VERSION ""

NS_ :

BS_:

BU_: TestTool_HS BCP_HS ECM_HS TCM_HS CGM_HS BCM_HS EBCM_OBD_HS ACCM_HS EBCM_HS TCCM_HS SAS_HS ICCM_OBD_HS ICCM_HS EPS_HS EPB_HS HMIM_HS ONSTAR_HS

BO_ 3221225472 VECTOR__INDEPENDENT_SIG_MSG: 0 Vector__XXX
 SG_ PTOStdbSpdCsCrStVal : 0|3@0+ (1,0) [0|7] "" Vector__XXX
 SG_ HVBatChrgCrdAlrtReq : 0|2@0+ (1,0) [0|3] "" Vector__XXX
 SG_ PTOSet2SpdCsStAvl : 0|1@0+ (1,0) [0|1] "" Vector__XXX
 SG_ PTOSet2SpdCsCrStVal : 0|4@0+ (1,0) [0|15] "" Vector__XXX
 SG_ PTOSet1SpdCsStAvl : 0|1@0+ (1,0) [0|1] "" Vector__XXX
 SG_ PTOSet1SpdCsCrStVal : 0|4@0+ (1,0) [0|15] "" Vector__XXX
 SG_ PTOEngRnTmrCsStAvl : 0|1@0+ (1,0) [0|1] "" Vector__XXX
 SG_ PTOEnRnTmCsCrStVal : 0|4@0+ (1,0) [0|15] "" Vector__XXX
 SG_ ClntCrcFlwRtEst : 0|8@0+ (0.392157,0) [0|100.000035] "%" Vector__XXX
 SG_ MntnceMdStEngRq : 0|1@0+ (1,0) [0|1] "" Vector__XXX
 SG_ PTOAccelUpnBrkRelIO : 0|1@0+ (1,0) [0|1] "" Vector__XXX
 SG_ PTOEngUpnBrkRelIO : 0|1@0+ (1,0) [0|1] "" Vector__XXX
 SG_ PTOManTransInGrIO : 0|1@0+ (1,0) [0|1] "" Vector__XXX
 SG_ PTOServIndOn : 0|1@0+ (1,0) [0|1] "" Vector__XXX
 SG_ PTOTransInGearIO : 0|1@0+ (1,0) [0|1] "" Vector__XXX
 SG_ PTOSetPrkBrkIO : 0|1@0+ (1,0) [0|1] "" Vector__XXX
 SG_ PTORelCltPedIO : 0|1@0+ (1,0) [0|1] "" Vector__XXX
 SG_ PTORelBrkPedIO : 0|1@0+ (1,0) [0|1] "" Vector__XXX
 SG_ PTORelAccPedIO : 0|1@0+ (1,0) [0|1] "" Vector__XXX
 SG_ PTORedEngSpdIO : 0|1@0+ (1,0) [0|1] "" Vector__XXX
 SG_ PTOPrsRelCltPedIO : 0|1@0+ (1,0) [0|1] "" Vector__XXX
 SG_ PTOPrsRelBrkPedIO : 0|1@0+ (1,0) [0|1] "" Vector__XXX
 SG_ PTOEngmntStatInd : 0|2@0+ (1,0) [0|3] "" Vector__XXX
 SG_ PTODisengCrsCntlIO : 0|1@0+ (1,0) [0|1] "" Vector__XXX
 SG_ PTOMobModTrnsInGrIO : 0|1@0+ (1,0) [0|1] "" Vector__XXX
 SG_ ActVbnCtrlMlfIO : 0|1@0+ (1,0) [0|1] "" Vector__XXX
 SG_ SrvSuspSysIO : 0|1@0+ (1,0) [0|1] "" Vector__XXX
 SG_ DCCnvStblznErrIO : 0|1@0+ (1,0) [0|1] "" Vector__XXX

BO_ 558 Air_Cmpresor_Ctrl_Data2_HS: 8 ACCM_HS
 SG_ CDSP_CmpDgrdOp : 25|1@0+ (1,0) [0|1] "" Vector__XXX
 SG_ CDSP_CmpIntShdwnFltSt : 27|2@0+ (1,0) [0|3] "" Vector__XXX
 SG_ CDSP_CmpIntRecblFltSt : 29|2@0+ (1,0) [0|3] "" Vector__XXX
 SG_ CDSP_CmpOpOvrldSt : 31|2@0+ (1,0) [0|3] "" Vector__XXX
 SG_ CDSP_CmpDrCrctFltSt : 17|2@0+ (1,0) [0|3] "" Vector__XXX
 SG_ CDSP_CmpMtrPerfFltSt : 19|2@0+ (1,0) [0|3] "" Vector__XXX
 SG_ CDSP_CmpEEPROMFltSt : 21|2@0+ (1,0) [0|3] "" Vector__XXX
 SG_ CDSP_CmpROMFltSt : 23|2@0+ (1,0) [0|3] "" Vector__XXX
 SG_ CDSP_CmpRAMFltSt : 9|2@0+ (1,0) [0|3] "" Vector__XXX
 SG_ CmpSnsrStPktARC : 7|2@0+ (1,0) [0|3] "N/A" Vector__XXX
 SG_ CSSP_CmpIGBTTpOtRgLSt : 41|2@0+ (1,0) [0|3] "" Vector__XXX
 SG_ CSSP_CmpIGBTTpOtRgHSt : 43|2@0+ (1,0) [0|3] "" Vector__XXX
 SG_ CSSP_CmpCPUTmpOtRgLSt : 45|2@0+ (1,0) [0|3] "" Vector__XXX
 SG_ CSSP_CmpCPUTmpOtRgHSt : 47|2@0+ (1,0) [0|3] "" Vector__XXX
 SG_ CSSP_CmpHVSnsOtRgLSt : 33|2@0+ (1,0) [0|3] "" Vector__XXX
 SG_ CSSP_CmpHVSnsOtRgHSt : 35|2@0+ (1,0) [0|3] "" Vector__XXX
 SG_ CSSP_CmpPhCrntOtRgLSt : 37|2@0+ (1,0) [0|3] "" Vector__XXX
 SG_ CSSP_CmpPhCrntOtRgHSt : 39|2@0+ (1,0) [0|3] "" Vector__XXX
 SG_ CmpDataPktARC : 57|2@0+ (1,0) [0|3] "N/A" Vector__XXX
 SG_ CDP_HVDevShtdnCdARCSt : 49|2@0+ (1,0) [0|3] "" Vector__XXX
 SG_ CDP_CmpSpdReqARCSt : 51|2@0+ (1,0) [0|3] "" Vector__XXX
 SG_ CDP_CmpLossCommOcc : 52|1@0+ (1,0) [0|1] "" Vector__XXX
 SG_ CDP_CmpWkUp : 53|1@0+ (1,0) [0|1] "" Vector__XXX
 SG_ CDP_CmpRunCrnk : 54|1@0+ (1,0) [0|1] "" Vector__XXX
 SG_ CmpSnsrDevStPktARC : 5|2@0+ (1,0) [0|3] "N/A" Vector__XXX
 SG_ CDSP_CmpOvrTmpSt : 11|2@0+ (1,0) [0|3] "" Vector__XXX
 SG_ CDSP_CmpHVAbnrlOrVltSt : 13|2@0+ (1,0) [0|3] "" Vector__XXX
 SG_ CDSP_CmpHVUndrVltgSt : 15|2@0+ (1,0) [0|3] "" Vector__XXX
 SG_ CDSP_CmpHVOvrVltgSt : 1|2@0+ (1,0) [0|3] "" Vector__XXX
 SG_ CDSP_CmpHVOvrCrntSt : 3|2@0+ (1,0) [0|3] "" Vector__XXX
 SG_ CDSP_OvrTempWrnInd : 24|1@0+ (1,0) [0|1] "" Vector__XXX

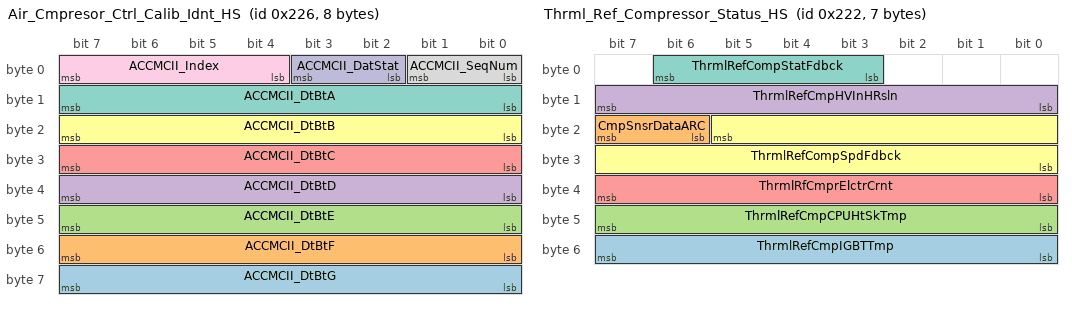
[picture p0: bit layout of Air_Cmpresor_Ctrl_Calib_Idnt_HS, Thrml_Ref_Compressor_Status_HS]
BO_ 550 Air_Cmpresor_Ctrl_Calib_Idnt_HS: 8 ACCM_HS
 SG_ ACCMCII_DtBtG : 63|8@0+ (1,0) [0|0] "" Vector__XXX
 SG_ ACCMCII_DtBtF : 55|8@0+ (1,0) [0|0] "" Vector__XXX
 SG_ ACCMCII_DtBtE : 47|8@0+ (1,0) [0|0] "" Vector__XXX
 SG_ ACCMCII_DtBtD : 39|8@0+ (1,0) [0|0] "" Vector__XXX
 SG_ ACCMCII_DtBtC : 31|8@0+ (1,0) [0|0] "" Vector__XXX
 SG_ ACCMCII_DtBtB : 23|8@0+ (1,0) [0|0] "" Vector__XXX
 SG_ ACCMCII_DtBtA : 15|8@0+ (1,0) [0|0] "" Vector__XXX
 SG_ ACCMCII_SeqNum : 1|2@0+ (1,0) [0|3] "" Vector__XXX
 SG_ ACCMCII_Index : 7|4@0+ (1,0) [0|15] "" Vector__XXX
 SG_ ACCMCII_DatStat : 3|2@0+ (1,0) [0|3] "" Vector__XXX

BO_ 546 Thrml_Ref_Compressor_Status_HS: 7 ACCM_HS
 SG_ ThrmlRefCmpIGBTTmp : 55|8@0+ (1,-40) [-40|215] "deg C" Vector__XXX
 SG_ CmpSnsrDataARC : 23|2@0+ (1,0) [0|3] "N/A" Vector__XXX
 SG_ ThrmlRefCmpCPUHtSkTmp : 47|8@0+ (1,-40) [-40|215] "deg C" Vector__XXX
 SG_ ThrmlRefCmpHVInHRsln : 15|8@0+ (2.5,0) [0|637.5] "V" Vector__XXX
 SG_ ThrmlRfCmprElctrCrnt : 39|8@0+ (0.2,0) [0|51] "A" Vector__XXX
 SG_ ThrmlRefCompSpdFdbck : 21|14@0+ (1,0) [0|16383] "rpm" Vector__XXX
 SG_ ThrmlRefCompStatFdbck : 6|4@0+ (1,0) [0|15] " " Vector__XXX

BO_ 289 ADASIS_RawData_Multiplexed_HS: 8 HMIM_HS
 SG_ Sig0936 : 4|61@0+ (1,0) [0|2.30584300921369E+018] "" Vector__XXX
 SG_ Sig0935 : 7|3@0+ (1,0) [0|7] "" Vector__XXX

BO_ 861 Temp_Diag_CAN_Resp_HS35D: 8 CGM_HS
 SG_ DgnInf : 7|64@0+ (1,0) [0|1.84467440737096E+019] "" Vector__XXX

BO_ 594 USDT_Req_to_HMIM_HS: 8 TestTool_HS
 SG_ DgnInf : 7|64@0+ (1,0) [0|1.84467440737096E+019] ""  CGM_HS,HMIM_HS

BO_ 593 USDT_Req_to_Free_51_HS: 8 TestTool_HS
 SG_ DgnInf : 7|64@0+ (1,0) [0|1.84467440737096E+019] "" Vector__XXX

BO_ 597 USDT_Req_to_Free_55_HS: 8 TestTool_HS
 SG_ DgnInf : 7|64@0+ (1,0) [0|1.84467440737096E+019] "" Vector__XXX

BO_ 592 USDT_Req_to_AVM_HS: 8 TestTool_HS
 SG_ DgnInf : 7|64@0+ (1,0) [0|1.84467440737096E+019] "" Vector__XXX

BO_ 589 USDT_Req_to_ONS_HS: 8 TestTool_HS
 SG_ DgnInf : 7|64@0+ (1,0) [0|1.84467440737096E+019] ""  CGM_HS,ONSTAR_HS

BO_ 582 USDT_Req_to_APPS_HS: 8 TestTool_HS
 SG_ DgnInf : 7|64@0+ (1,0) [0|1.84467440737096E+019] ""  CGM_HS

BO_ 601 USDT_Req_to_MCP_C_HS: 8 TestTool_HS
 SG_ DgnInf : 7|64@0+ (1,0) [0|1.84467440737096E+019] "" Vector__XXX

BO_ 2023 USDT_Req_to_VITM_HS: 8 TestTool_HS
 SG_ DgnInf : 7|64@0+ (1,0) [0|1.84467440737096E+019] "" Vector__XXX

BO_ 2021 USDT_Req_to_OBD_Device5: 8 TestTool_HS
 SG_ DgnInf : 7|64@0+ (1,0) [0|1.84467440737096E+019] ""  EBCM_OBD_HS

BO_ 2019 USDT_Req_to_ICCM_OBD_HS: 8 TestTool_HS
 SG_ DgnInf : 7|64@0+ (1,0) [0|1.84467440737096E+019] ""  ICCM_OBD_HS,ICCM_HS

BO_ 578 USDT_Req_to_EHPS_EPS_HS: 8 TestTool_HS
 SG_ DgnInf : 7|64@0+ (1,0) [0|1.84467440737096E+019] ""  EPS_HS

BO_ 2022 USDT_Req_to_OBD_Device6: 8 TestTool_HS
 SG_ DgnInf : 7|64@0+ (1,0) [0|1.84467440737096E+019] "" Vector__XXX

BO_ 584 USDT_Req_to_Free_48_HS: 8 TestTool_HS
 SG_ DgnInf : 7|64@0+ (1,0) [0|1.84467440737096E+019] "" Vector__XXX

BO_ 586 USDT_Req_to_SAS_HS: 8 TestTool_HS
 SG_ DgnInf : 7|64@0+ (1,0) [0|1.84467440737096E+019] ""  SAS_HS

BO_ 588 USDT_Req_to_PFAF_HS: 8 TestTool_HS
 SG_ DgnInf : 7|64@0+ (1,0) [0|1.84467440737096E+019] ""  CGM_HS

BO_ 580 USDT_Req_to_OBCM_HS: 8 TestTool_HS
 SG_ DgnInf : 7|64@0+ (1,0) [0|1.84467440737096E+019] "" Vector__XXX

BO_ 2020 USDT_Req_to_VICM_HS: 8 TestTool_HS
 SG_ DgnInf : 7|64@0+ (1,0) [0|1.84467440737096E+019] "" Vector__XXX

BO_ 599 USDT_Req_to_MCP_HS: 8 TestTool_HS
 SG_ DgnInf : 7|64@0+ (1,0) [0|1.84467440737096E+019] "" Vector__XXX

BO_ 2017 USDT_Req_to_BCP_HS: 8 TestTool_HS
 SG_ DgnInf : 7|64@0+ (1,0) [0|1.84467440737096E+019] ""  BCP_HS

BO_ 1910 DTC_Triggered_776: 7 BCP_HS
 SG_ DTCI_DTCFaultType_776 : 55|8@0+ (1,0) [0|255] ""  CGM_HS,HMIM_HS,ONSTAR_HS
 SG_ DTCI_CodeSupported_776 : 40|1@0+ (1,0) [0|1] ""  CGM_HS,HMIM_HS,ONSTAR_HS
 SG_ DTCI_CurrentStatus_776 : 41|1@0+ (1,0) [0|1] ""  CGM_HS,HMIM_HS,ONSTAR_HS
 SG_ DTCI_TstNPsdCdClrdSt_776 : 42|1@0+ (1,0) [0|1] ""  CGM_HS,HMIM_HS,ONSTAR_HS
 SG_ DTCI_TstFldCdClrdStat_776 : 43|1@0+ (1,0) [0|1] ""  CGM_HS,HMIM_HS,ONSTAR_HS
 SG_ DTCI_HistStat_776 : 44|1@0+ (1,0) [0|1] ""  CGM_HS,HMIM_HS,ONSTAR_HS
 SG_ DTCI_TstNPsdPwrUpSt_776 : 45|1@0+ (1,0) [0|1] ""  CGM_HS,HMIM_HS,ONSTAR_HS
 SG_ DTCI_TstFldPwrUpSt_776 : 46|1@0+ (1,0) [0|1] ""  CGM_HS,HMIM_HS,ONSTAR_HS
 SG_ DTCI_WrnIndRqdSt_776 : 47|1@0+ (1,0) [0|1] ""  CGM_HS,HMIM_HS,ONSTAR_HS
 SG_ DTCI_DTCFailType_776 : 39|8@0+ (1,0) [0|255] ""  CGM_HS,HMIM_HS,ONSTAR_HS
 SG_ DTCI_DTCNumber_776 : 23|16@0+ (1,0) [0|65535] ""  CGM_HS,HMIM_HS,ONSTAR_HS
 SG_ DTCI_DTCSource_776 : 15|8@0+ (1,0) [0|255] ""  CGM_HS,HMIM_HS,ONSTAR_HS
 SG_ DTCI_DTCTriggered_776 : 0|1@0+ (1,0) [0|1] ""  CGM_HS,HMIM_HS,ONSTAR_HS
 SG_ DTCIUnused7_776 : 1|1@0+ (1,0) [0|1] ""  CGM_HS,HMIM_HS,ONSTAR_HS
 SG_ DTCIUnused6_776 : 2|1@0+ (1,0) [0|1] ""  CGM_HS,HMIM_HS,ONSTAR_HS
 SG_ DTCIUnused5_776 : 3|1@0+ (1,0) [0|1] ""  CGM_HS,HMIM_HS,ONSTAR_HS
 SG_ DTCIUnused4_776 : 4|1@0+ (1,0) [0|1] ""  CGM_HS,HMIM_HS,ONSTAR_HS
 SG_ DTCIUnused3_776 : 5|1@0+ (1,0) [0|1] ""  CGM_HS,HMIM_HS,ONSTAR_HS
 SG_ DTCIUnused2_776 : 6|1@0+ (1,0) [0|1] ""  CGM_HS,HMIM_HS,ONSTAR_HS
 SG_ DTCIUnused1_776 : 7|1@0+ (1,0) [0|1] ""  CGM_HS,HMIM_HS,ONSTAR_HS

BO_ 2025 USDT_Resp_From_BCP_HS: 8 BCP_HS
 SG_ DgnInf : 7|64@0+ (1,0) [0|1.84467440737096E+019] ""  CGM_HS,TestTool_HS,ONSTAR_HS

BO_ 1513 UUDT_Resp_From_BCP_HS: 8 BCP_HS
 SG_ DgnInf : 7|64@0+ (1,0) [0|1.84467440737096E+019] ""  CGM_HS,TestTool_HS,ONSTAR_HS

BO_ 581 USDT_Req_to_ALC_HS: 8 TestTool_HS
 SG_ DgnInf : 7|64@0+ (1,0) [0|1.84467440737096E+019] "" Vector__XXX

BO_ 585 USDT_Req_to_AFL_AHL_HS: 8 TestTool_HS
 SG_ DgnInf : 7|64@0+ (1,0) [0|1.84467440737096E+019] ""  CGM_HS

BO_ 1916 DTC_Triggered_77C: 7 CGM_HS
 SG_ DTCI_DTCFaultType_77C : 55|8@0+ (1,0) [0|255] ""  CGM_HS,HMIM_HS,ONSTAR_HS
 SG_ DTCI_CodeSupported_77C : 40|1@0+ (1,0) [0|1] ""  CGM_HS,HMIM_HS,ONSTAR_HS
 SG_ DTCI_CurrentStatus_77C : 41|1@0+ (1,0) [0|1] ""  CGM_HS,HMIM_HS,ONSTAR_HS
 SG_ DTCI_TstNPsdCdClrdSt_77C : 42|1@0+ (1,0) [0|1] ""  CGM_HS,HMIM_HS,ONSTAR_HS
 SG_ DTCI_TstFldCdClrdStat_77C : 43|1@0+ (1,0) [0|1] ""  CGM_HS,HMIM_HS,ONSTAR_HS
 SG_ DTCI_HistStat_77C : 44|1@0+ (1,0) [0|1] ""  CGM_HS,HMIM_HS,ONSTAR_HS
 SG_ DTCI_TstNPsdPwrUpSt_77C : 45|1@0+ (1,0) [0|1] ""  CGM_HS,HMIM_HS,ONSTAR_HS
 SG_ DTCI_TstFldPwrUpSt_77C : 46|1@0+ (1,0) [0|1] ""  CGM_HS,HMIM_HS,ONSTAR_HS
 SG_ DTCI_WrnIndRqdSt_77C : 47|1@0+ (1,0) [0|1] ""  CGM_HS,HMIM_HS,ONSTAR_HS
 SG_ DTCI_DTCFailType_77C : 39|8@0+ (1,0) [0|255] ""  CGM_HS,HMIM_HS,ONSTAR_HS
 SG_ DTCI_DTCNumber_77C : 23|16@0+ (1,0) [0|65535] ""  CGM_HS,HMIM_HS,ONSTAR_HS
 SG_ DTCI_DTCSource_77C : 15|8@0+ (1,0) [0|255] ""  CGM_HS,HMIM_HS,ONSTAR_HS
 SG_ DTCI_DTCTriggered_77C : 0|1@0+ (1,0) [0|1] ""  CGM_HS,HMIM_HS,ONSTAR_HS
 SG_ DTCIUnused7_77C : 1|1@0+ (1,0) [0|1] ""  CGM_HS,HMIM_HS,ONSTAR_HS
 SG_ DTCIUnused6_77C : 2|1@0+ (1,0) [0|1] ""  CGM_HS,HMIM_HS,ONSTAR_HS
 SG_ DTCIUnused5_77C : 3|1@0+ (1,0) [0|1] ""  CGM_HS,HMIM_HS,ONSTAR_HS
 SG_ DTCIUnused4_77C : 4|1@0+ (1,0) [0|1] ""  CGM_HS,HMIM_HS,ONSTAR_HS
 SG_ DTCIUnused3_77C : 5|1@0+ (1,0) [0|1] ""  CGM_HS,HMIM_HS,ONSTAR_HS
 SG_ DTCIUnused2_77C : 6|1@0+ (1,0) [0|1] ""  CGM_HS,HMIM_HS,ONSTAR_HS
 SG_ DTCIUnused1_77C : 7|1@0+ (1,0) [0|1] ""  CGM_HS,HMIM_HS,ONSTAR_HS

BO_ 1353 UUDT_Resp_From_AHL_AFL_HS: 8 CGM_HS
 SG_ DgnInf_HS549 : 7|64@0+ (1,0) [0|1.84467440737096E+019] ""  CGM_HS,TestTool_HS,ONSTAR_HS

BO_ 1609 USDT_Resp_From_AHL_AFL_HS: 8 CGM_HS
 SG_ DgnInf : 7|64@0+ (1,0) [0|1.84467440737096E+019] ""  CGM_HS,TestTool_HS,ONSTAR_HS

BO_ 590 USDT_Req_to_SADS_HS: 8 TestTool_HS
 SG_ DgnInf : 7|64@0+ (1,0) [0|1.84467440737096E+019] "" Vector__XXX

BO_ 596 USDT_Req_to_EPB_HS: 8 TestTool_HS
 SG_ DgnInf : 7|64@0+ (1,0) [0|1.84467440737096E+019] ""  CGM_HS,EPB_HS

BO_ 1364 UUDT_Resp_From_EPB_HS: 8 EPB_HS
 SG_ DgnInf_HS554 : 7|64@0+ (1,0) [0|1.84467440737096E+019] ""  CGM_HS,ONSTAR_HS,TestTool_HS

BO_ 1917 DTC_Triggered_77D: 7 EPB_HS
 SG_ DTCI_DTCFaultType_77D : 55|8@0+ (1,0) [0|255] ""  CGM_HS,HMIM_HS,ONSTAR_HS
 SG_ DTCI_CodeSupported_77D : 40|1@0+ (1,0) [0|1] ""  CGM_HS,HMIM_HS,ONSTAR_HS
 SG_ DTCI_CurrentStatus_77D : 41|1@0+ (1,0) [0|1] ""  CGM_HS,HMIM_HS,ONSTAR_HS
 SG_ DTCI_TstNPsdCdClrdSt_77D : 42|1@0+ (1,0) [0|1] ""  CGM_HS,HMIM_HS,ONSTAR_HS
 SG_ DTCI_TstFldCdClrdStat_77D : 43|1@0+ (1,0) [0|1] ""  CGM_HS,HMIM_HS,ONSTAR_HS
 SG_ DTCI_HistStat_77D : 44|1@0+ (1,0) [0|1] ""  CGM_HS,HMIM_HS,ONSTAR_HS
 SG_ DTCI_TstNPsdPwrUpSt_77D : 45|1@0+ (1,0) [0|1] ""  CGM_HS,HMIM_HS,ONSTAR_HS
 SG_ DTCI_TstFldPwrUpSt_77D : 46|1@0+ (1,0) [0|1] ""  CGM_HS,HMIM_HS,ONSTAR_HS
 SG_ DTCI_WrnIndRqdSt_77D : 47|1@0+ (1,0) [0|1] ""  CGM_HS,HMIM_HS,ONSTAR_HS
 SG_ DTCI_DTCFailType_77D : 39|8@0+ (1,0) [0|255] ""  CGM_HS,HMIM_HS,ONSTAR_HS
 SG_ DTCI_DTCNumber_77D : 23|16@0+ (1,0) [0|65535] ""  CGM_HS,HMIM_HS,ONSTAR_HS
 SG_ DTCI_DTCSource_77D : 15|8@0+ (1,0) [0|255] ""  CGM_HS,HMIM_HS,ONSTAR_HS
 SG_ DTCI_DTCTriggered_77D : 0|1@0+ (1,0) [0|1] ""  CGM_HS,HMIM_HS,ONSTAR_HS
 SG_ DTCIUnused7_77D : 1|1@0+ (1,0) [0|1] ""  CGM_HS,HMIM_HS,ONSTAR_HS
 SG_ DTCIUnused6_77D : 2|1@0+ (1,0) [0|1] ""  CGM_HS,HMIM_HS,ONSTAR_HS
 SG_ DTCIUnused5_77D : 3|1@0+ (1,0) [0|1] ""  CGM_HS,HMIM_HS,ONSTAR_HS
 SG_ DTCIUnused4_77D : 4|1@0+ (1,0) [0|1] ""  CGM_HS,HMIM_HS,ONSTAR_HS
 SG_ DTCIUnused3_77D : 5|1@0+ (1,0) [0|1] ""  CGM_HS,HMIM_HS,ONSTAR_HS
 SG_ DTCIUnused2_77D : 6|1@0+ (1,0) [0|1] ""  CGM_HS,HMIM_HS,ONSTAR_HS
 SG_ DTCIUnused1_77D : 7|1@0+ (1,0) [0|1] ""  CGM_HS,HMIM_HS,ONSTAR_HS

BO_ 1620 USDT_Resp_From_EPB_HS: 8 EPB_HS
 SG_ DgnInf : 7|64@0+ (1,0) [0|1.84467440737096E+019] ""  CGM_HS,ONSTAR_HS,TestTool_HS

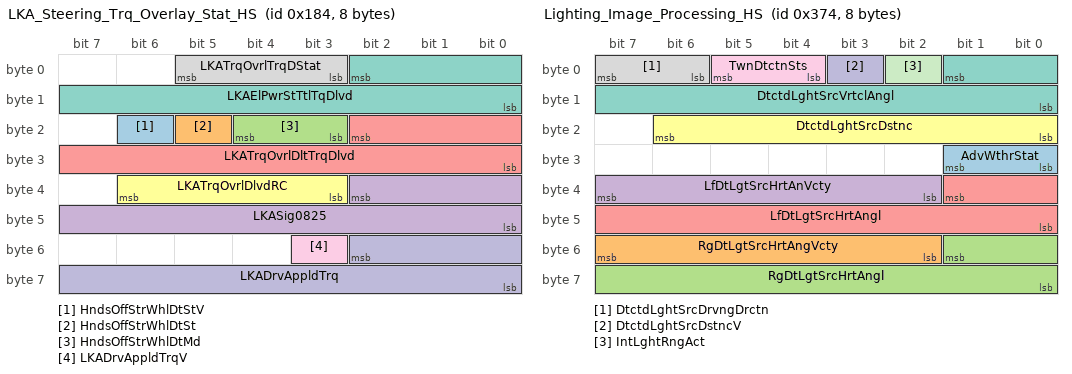
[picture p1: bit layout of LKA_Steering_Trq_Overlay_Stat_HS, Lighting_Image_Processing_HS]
BO_ 388 LKA_Steering_Trq_Overlay_Stat_HS: 8 EPS_HS
 SG_ HndsOffStrWhlDtStV : 22|1@0+ (1,0) [0|1] ""  CGM_HS
 SG_ HndsOffStrWhlDtSt : 21|1@0+ (1,0) [0|1] ""  CGM_HS
 SG_ HndsOffStrWhlDtMd : 20|2@0+ (1,0) [0|3] ""  CGM_HS
 SG_ LKASig0825 : 34|11@0+ (1,0) [0|2047] ""  CGM_HS
 SG_ LKATrqOvrlDltTrqDlvd : 18|11@0- (0.01,0) [-10.24|10.23] "Nm"  CGM_HS
 SG_ LKATrqOvrlDlvdRC : 38|4@0+ (1,0) [0|15] ""  CGM_HS
 SG_ LKAElPwrStTtlTqDlvd : 2|11@0- (0.01,0) [-10.24|10.23] "Nm"  CGM_HS
 SG_ LKATrqOvrlTrqDStat : 5|3@0+ (1,0) [0|7] ""  CGM_HS
 SG_ LKADrvAppldTrqV : 51|1@0+ (1,0) [0|1] ""  CGM_HS
 SG_ LKADrvAppldTrq : 50|11@0- (0.01,0) [-10.24|10.23] "Nm"  CGM_HS

BO_ 587 USDT_Req_to_ECU033_FCM_HS: 8 TestTool_HS
 SG_ DgnInf : 7|64@0+ (1,0) [0|1.84467440737096E+019] ""  CGM_HS

BO_ 884 Lighting_Image_Processing_HS: 8 CGM_HS
 SG_ AdvWthrStat : 25|2@0+ (1,0) [0|3] ""  CGM_HS
 SG_ RgDtLgtSrcHrtAngVcty : 55|6@0- (1,0) [-32|31] "deg/sec"  CGM_HS
 SG_ RgDtLgtSrcHrtAngl : 49|10@0- (0.04,0) [-20.48|20.44] "deg"  CGM_HS
 SG_ LfDtLgtSrcHrtAnVcty : 39|6@0- (1,0) [-32|31] "deg/sec"  CGM_HS
 SG_ LfDtLgtSrcHrtAngl : 33|10@0- (0.04,0) [-20.48|20.44] "deg"  CGM_HS
 SG_ DtctdLghtSrcDstnc : 22|7@0+ (10,0) [0|1270] "m"  CGM_HS
 SG_ DtctdLghtSrcVrtclAngl : 1|10@0- (0.04,0) [-20.48|20.44] "deg"  CGM_HS
 SG_ DtctdLghtSrcDrvngDrctn : 7|2@0+ (1,0) [0|3] ""  CGM_HS
 SG_ TwnDtctnSts : 5|2@0+ (1,0) [0|3] ""  CGM_HS
 SG_ DtctdLghtSrcDstncV : 3|1@0+ (1,0) [0|1] ""  CGM_HS
 SG_ IntLghtRngAct : 2|1@0+ (1,0) [0|1] ""  CGM_HS

BO_ 1930 DTC_Triggered_78A: 7 CGM_HS
 SG_ DTCI_CodeSupported_78A : 40|1@0+ (1,0) [0|1] ""  CGM_HS,HMIM_HS,ONSTAR_HS
 SG_ DTCI_CurrentStatus_78A : 41|1@0+ (1,0) [0|1] ""  CGM_HS,HMIM_HS,ONSTAR_HS
 SG_ DTCI_DTCFailType_78A : 39|8@0+ (1,0) [0|255] ""  CGM_HS,HMIM_HS,ONSTAR_HS
 SG_ DTCI_DTCFaultType_78A : 55|8@0+ (1,0) [0|255] ""  CGM_HS,HMIM_HS,ONSTAR_HS
 SG_ DTCI_DTCNumber_78A : 23|16@0+ (1,0) [0|65535] ""  CGM_HS,HMIM_HS,ONSTAR_HS
 SG_ DTCI_DTCSource_78A : 15|8@0+ (1,0) [0|255] ""  CGM_HS,HMIM_HS,ONSTAR_HS
 SG_ DTCI_DTCTriggered_78A : 0|1@0+ (1,0) [0|1] ""  CGM_HS,HMIM_HS,ONSTAR_HS
 SG_ DTCI_HistStat_78A : 44|1@0+ (1,0) [0|1] ""  CGM_HS,HMIM_HS,ONSTAR_HS
 SG_ DTCI_TstFldCdClrdStat_78A : 43|1@0+ (1,0) [0|1] ""  CGM_HS,HMIM_HS,ONSTAR_HS
 SG_ DTCI_TstFldPwrUpSt_78A : 46|1@0+ (1,0) [0|1] ""  CGM_HS,HMIM_HS,ONSTAR_HS
 SG_ DTCI_TstNPsdCdClrdSt_78A : 42|1@0+ (1,0) [0|1] ""  CGM_HS,HMIM_HS,ONSTAR_HS
 SG_ DTCI_TstNPsdPwrUpSt_78A : 45|1@0+ (1,0) [0|1] ""  CGM_HS,HMIM_HS,ONSTAR_HS
 SG_ DTCIUnused1_78A : 7|1@0+ (1,0) [0|1] ""  CGM_HS,HMIM_HS,ONSTAR_HS
 SG_ DTCIUnused2_78A : 6|1@0+ (1,0) [0|1] ""  CGM_HS,HMIM_HS,ONSTAR_HS
 SG_ DTCIUnused3_78A : 5|1@0+ (1,0) [0|1] ""  CGM_HS,HMIM_HS,ONSTAR_HS
 SG_ DTCIUnused4_78A : 4|1@0+ (1,0) [0|1] ""  CGM_HS,HMIM_HS,ONSTAR_HS
 SG_ DTCIUnused5_78A : 3|1@0+ (1,0) [0|1] ""  CGM_HS,HMIM_HS,ONSTAR_HS
 SG_ DTCIUnused6_78A : 2|1@0+ (1,0) [0|1] ""  CGM_HS,HMIM_HS,ONSTAR_HS
 SG_ DTCIUnused7_78A : 1|1@0+ (1,0) [0|1] ""  CGM_HS,HMIM_HS,ONSTAR_HS
 SG_ DTCI_WrnIndRqdSt_78A : 47|1@0+ (1,0) [0|1] ""  CGM_HS,HMIM_HS,ONSTAR_HS

BO_ 1611 USDT_Resp_From_ECU033_FCM_HS: 8 CGM_HS
 SG_ DgnInf : 7|64@0+ (1,0) [0|1.84467440737096E+019] ""  CGM_HS,TestTool_HS,ONSTAR_HS

BO_ 1355 UUDT_Resp_From_ECU033_FCM_HS: 8 CGM_HS
 SG_ DgnInf_HS54B : 7|64@0+ (1,0) [0|1.84467440737096E+019] ""  CGM_HS,TestTool_HS,ONSTAR_HS

BO_ 598 USDT_Req_to_TCCM_HS: 8 TestTool_HS
 SG_ DgnInf : 7|64@0+ (1,0) [0|1.84467440737096E+019] ""  TCCM_HS

BO_ 1366 UUDT_Resp_From_TCCM_HS: 8 TCCM_HS
 SG_ DgnInf_HS556 : 7|64@0+ (1,0) [0|1.84467440737096E+019] ""  CGM_HS,ONSTAR_HS,TestTool_HS

BO_ 1622 USDT_Resp_From_TCCM_HS: 8 TCCM_HS
 SG_ DgnInf : 7|64@0+ (1,0) [0|1.84467440737096E+019] ""  CGM_HS,ONSTAR_HS,TestTool_HS

BO_ 591 USDT_Req_to_RDCM_HS: 8 TestTool_HS
 SG_ DgnInf : 7|64@0+ (1,0) [0|1.84467440737096E+019] "" Vector__XXX

BO_ 1914 DTC_Triggered_77A: 7 TCCM_HS
 SG_ DTCI_DTCFaultType_77A : 55|8@0+ (1,0) [0|255] ""  CGM_HS,HMIM_HS,ONSTAR_HS
 SG_ DTCI_CodeSupported_77A : 40|1@0+ (1,0) [0|1] ""  CGM_HS,HMIM_HS,ONSTAR_HS
 SG_ DTCI_CurrentStatus_77A : 41|1@0+ (1,0) [0|1] ""  CGM_HS,HMIM_HS,ONSTAR_HS
 SG_ DTCI_TstNPsdCdClrdSt_77A : 42|1@0+ (1,0) [0|1] ""  CGM_HS,HMIM_HS,ONSTAR_HS
 SG_ DTCI_TstFldCdClrdStat_77A : 43|1@0+ (1,0) [0|1] ""  CGM_HS,HMIM_HS,ONSTAR_HS
 SG_ DTCI_HistStat_77A : 44|1@0+ (1,0) [0|1] ""  CGM_HS,HMIM_HS,ONSTAR_HS
 SG_ DTCI_TstNPsdPwrUpSt_77A : 45|1@0+ (1,0) [0|1] ""  CGM_HS,HMIM_HS,ONSTAR_HS
 SG_ DTCI_TstFldPwrUpSt_77A : 46|1@0+ (1,0) [0|1] ""  CGM_HS,HMIM_HS,ONSTAR_HS
 SG_ DTCI_WrnIndRqdSt_77A : 47|1@0+ (1,0) [0|1] ""  CGM_HS,HMIM_HS,ONSTAR_HS
 SG_ DTCI_DTCFailType_77A : 39|8@0+ (1,0) [0|255] ""  CGM_HS,HMIM_HS,ONSTAR_HS
 SG_ DTCI_DTCNumber_77A : 23|16@0+ (1,0) [0|65535] ""  CGM_HS,HMIM_HS,ONSTAR_HS
 SG_ DTCI_DTCSource_77A : 15|8@0+ (1,0) [0|255] ""  CGM_HS,HMIM_HS,ONSTAR_HS
 SG_ DTCI_DTCTriggered_77A : 0|1@0+ (1,0) [0|1] ""  CGM_HS,HMIM_HS,ONSTAR_HS
 SG_ DTCIUnused7_77A : 1|1@0+ (1,0) [0|1] ""  CGM_HS,HMIM_HS,ONSTAR_HS
 SG_ DTCIUnused6_77A : 2|1@0+ (1,0) [0|1] ""  CGM_HS,HMIM_HS,ONSTAR_HS
 SG_ DTCIUnused5_77A : 3|1@0+ (1,0) [0|1] ""  CGM_HS,HMIM_HS,ONSTAR_HS
 SG_ DTCIUnused4_77A : 4|1@0+ (1,0) [0|1] ""  CGM_HS,HMIM_HS,ONSTAR_HS
 SG_ DTCIUnused3_77A : 5|1@0+ (1,0) [0|1] ""  CGM_HS,HMIM_HS,ONSTAR_HS
 SG_ DTCIUnused2_77A : 6|1@0+ (1,0) [0|1] ""  CGM_HS,HMIM_HS,ONSTAR_HS
 SG_ DTCIUnused1_77A : 7|1@0+ (1,0) [0|1] ""  CGM_HS,HMIM_HS,ONSTAR_HS

BO_ 2032 CCP_Command_Receive_Object_HS: 8 TestTool_HS
 SG_ DgnInf : 7|64@0+ (1,0) [0|1.84467440737096E+019] ""  CGM_HS

BO_ 583 USDT_Req_to_PTO_HS: 8 TestTool_HS
 SG_ DgnInf : 7|64@0+ (1,0) [0|1.84467440737096E+019] "" Vector__XXX

BO_ 2034 CCP_Data_Transmission_Object_HS: 8 CGM_HS
 SG_ DgnInf : 7|64@0+ (1,0) [0|1.84467440737096E+019] ""  TestTool_HS

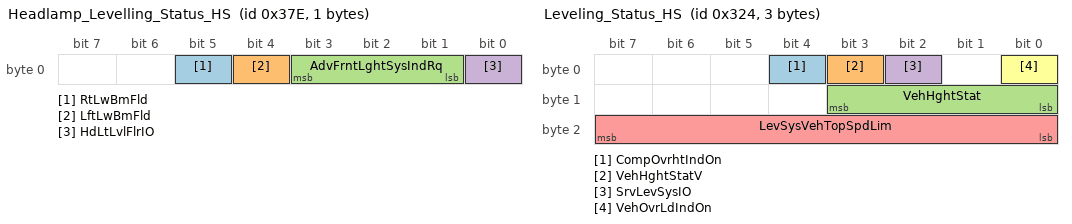
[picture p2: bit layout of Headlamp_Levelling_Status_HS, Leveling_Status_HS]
BO_ 894 Headlamp_Levelling_Status_HS: 1 CGM_HS
 SG_ RtLwBmFld : 5|1@0+ (1,0) [0|1] ""  BCM_HS
 SG_ LftLwBmFld : 4|1@0+ (1,0) [0|1] ""  BCM_HS
 SG_ AdvFrntLghtSysIndRq : 3|3@0+ (1,0) [0|7] ""  BCM_HS
 SG_ HdLtLvlFlrIO : 0|1@0+ (1,0) [0|1] ""  BCM_HS

BO_ 577 USDT_Req_to_BCM_HS: 8 TestTool_HS
 SG_ DgnInf : 7|64@0+ (1,0) [0|1.84467440737096E+019] ""  BCM_HS

BO_ 804 Leveling_Status_HS: 3 ICCM_HS
 SG_ CompOvrhtIndOn : 4|1@0+ (1,0) [0|1] ""  CGM_HS,BCM_HS
 SG_ VehHghtStatV : 3|1@0+ (1,0) [0|1] ""  CGM_HS,EBCM_OBD_HS,EBCM_HS,BCM_HS
 SG_ VehHghtStat : 11|4@0+ (1,0) [0|15] ""  CGM_HS,EBCM_OBD_HS,EBCM_HS,BCM_HS
 SG_ SrvLevSysIO : 2|1@0+ (1,0) [0|1] ""  CGM_HS,ONSTAR_HS,BCM_HS
 SG_ LevSysVehTopSpdLim : 23|8@0+ (2,0) [0|510] "km/h"  CGM_HS,BCM_HS
 SG_ VehOvrLdIndOn : 0|1@0+ (1,0) [0|1] ""  CGM_HS,ONSTAR_HS,BCM_HS

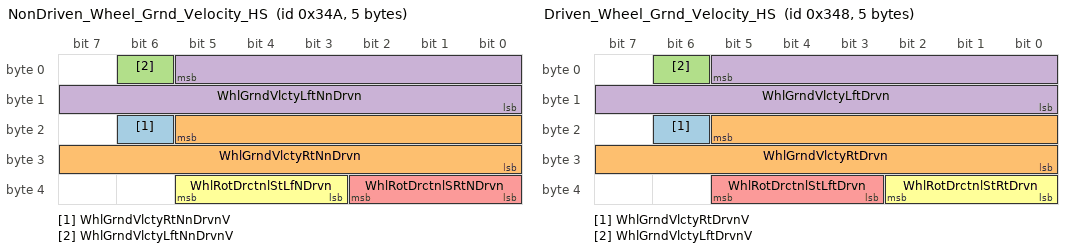
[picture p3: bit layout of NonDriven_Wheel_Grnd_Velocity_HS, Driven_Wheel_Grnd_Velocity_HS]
BO_ 842 NonDriven_Wheel_Grnd_Velocity_HS: 5 EBCM_HS
 SG_ WhlGrndVlctyRtNnDrvnV : 22|1@0+ (1,0) [0|1] ""  CGM_HS,HMIM_HS,EPS_HS,EPB_HS,TCCM_HS,BCM_HS
 SG_ WhlGrndVlctyRtNnDrvn : 21|14@0+ (0.03125,0) [0|511.96875] "km / h"  CGM_HS,HMIM_HS,EPS_HS,EPB_HS,TCCM_HS,BCM_HS
 SG_ WhlGrndVlctyLftNnDrvnV : 6|1@0+ (1,0) [0|1] ""  CGM_HS,HMIM_HS,EPS_HS,EPB_HS,TCCM_HS,BCM_HS
 SG_ WhlGrndVlctyLftNnDrvn : 5|14@0+ (0.03125,0) [0|511.96875] "km / h"  CGM_HS,HMIM_HS,EPS_HS,EPB_HS,TCCM_HS,BCM_HS
 SG_ WhlRotDrctnlSRtNDrvn : 34|3@0+ (1,0) [0|7] ""  CGM_HS,HMIM_HS,EPS_HS
 SG_ WhlRotDrctnlStLfNDrvn : 37|3@0+ (1,0) [0|7] ""  CGM_HS,HMIM_HS,EPS_HS

BO_ 840 Driven_Wheel_Grnd_Velocity_HS: 5 EBCM_HS
 SG_ WhlGrndVlctyRtDrvnV : 22|1@0+ (1,0) [0|1] ""  CGM_HS,HMIM_HS,EPS_HS,TCCM_HS,EPB_HS,BCM_HS
 SG_ WhlGrndVlctyRtDrvn : 21|14@0+ (0.03125,0) [0|511.96875] "km / h"  CGM_HS,HMIM_HS,EPS_HS,TCCM_HS,EPB_HS,BCM_HS
 SG_ WhlGrndVlctyLftDrvnV : 6|1@0+ (1,0) [0|1] ""  CGM_HS,HMIM_HS,EPS_HS,TCCM_HS,EPB_HS,BCM_HS
 SG_ WhlGrndVlctyLftDrvn : 5|14@0+ (0.03125,0) [0|511.96875] "km / h"  CGM_HS,HMIM_HS,EPS_HS,TCCM_HS,EPB_HS,BCM_HS
 SG_ WhlRotDrctnlStLftDrvn : 37|3@0+ (1,0) [0|7] ""  CGM_HS,HMIM_HS,EPS_HS
 SG_ WhlRotDrctnlStRtDrvn : 34|3@0+ (1,0) [0|7] ""  CGM_HS,HMIM_HS,EPS_HS

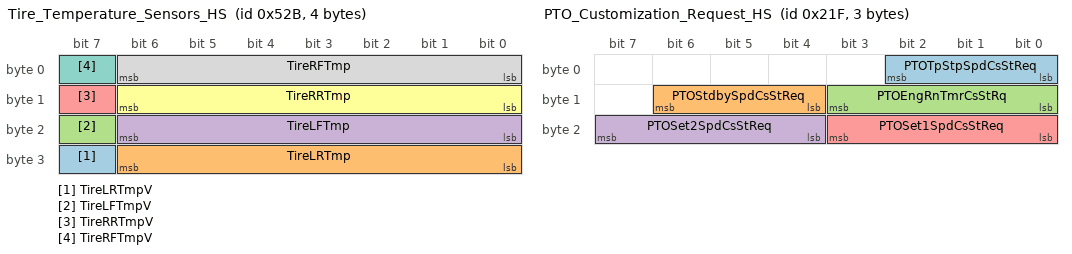
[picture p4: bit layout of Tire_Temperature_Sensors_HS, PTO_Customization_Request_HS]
BO_ 1323 Tire_Temperature_Sensors_HS: 4 BCM_HS
 SG_ TireLRTmpV : 31|1@0+ (1,0) [0|1] ""  CGM_HS,ICCM_OBD_HS,EBCM_OBD_HS,ICCM_HS,EBCM_HS
 SG_ TireLRTmp : 30|7@0+ (1,-20) [-20|107] "deg C"  CGM_HS,ICCM_OBD_HS,EBCM_OBD_HS,ICCM_HS,EBCM_HS
 SG_ TireLFTmpV : 23|1@0+ (1,0) [0|1] ""  CGM_HS,ICCM_OBD_HS,EBCM_OBD_HS,ICCM_HS,EBCM_HS
 SG_ TireLFTmp : 22|7@0+ (1,-20) [-20|107] "deg C"  CGM_HS,ICCM_OBD_HS,EBCM_OBD_HS,ICCM_HS,EBCM_HS
 SG_ TireRRTmpV : 15|1@0+ (1,0) [0|1] ""  CGM_HS,ICCM_OBD_HS,EBCM_OBD_HS,ICCM_HS,EBCM_HS
 SG_ TireRRTmp : 14|7@0+ (1,-20) [-20|107] "deg C"  CGM_HS,ICCM_OBD_HS,EBCM_OBD_HS,ICCM_HS,EBCM_HS
 SG_ TireRFTmpV : 7|1@0+ (1,0) [0|1] ""  CGM_HS,ICCM_OBD_HS,EBCM_OBD_HS,ICCM_HS,EBCM_HS
 SG_ TireRFTmp : 6|7@0+ (1,-20) [-20|107] "deg C"  CGM_HS,ICCM_OBD_HS,EBCM_OBD_HS,ICCM_HS,EBCM_HS

BO_ 543 PTO_Customization_Request_HS: 3 BCM_HS
 SG_ PTOTpStpSpdCsStReq : 2|3@0+ (1,0) [0|7] "" Vector__XXX
 SG_ PTOStdbySpdCsStReq : 14|3@0+ (1,0) [0|7] "" Vector__XXX
 SG_ PTOEngRnTmrCsStRq : 11|4@0+ (1,0) [0|15] "" Vector__XXX
 SG_ PTOSet2SpdCsStReq : 23|4@0+ (1,0) [0|15] "" Vector__XXX
 SG_ PTOSet1SpdCsStReq : 19|4@0+ (1,0) [0|15] "" Vector__XXX

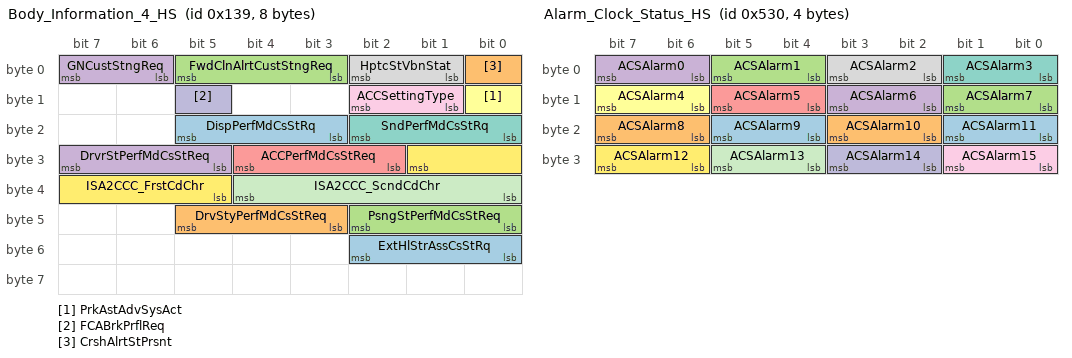
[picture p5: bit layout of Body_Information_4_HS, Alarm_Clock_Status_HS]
BO_ 313 Body_Information_4_HS: 8 BCM_HS
 SG_ ExtHlStrAssCsStRq : 50|3@0+ (1,0) [0|7] ""  EBCM_OBD_HS,EBCM_HS
 SG_ DrvStyPerfMdCsStReq : 45|3@0+ (1,0) [0|7] ""  CGM_HS,EBCM_OBD_HS,EBCM_HS
 SG_ PsngStPerfMdCsStReq : 42|3@0+ (1,0) [0|7] ""  CGM_HS,EBCM_OBD_HS,EBCM_HS
 SG_ DrvrStPerfMdCsStReq : 31|3@0+ (1,0) [0|7] ""  CGM_HS,EBCM_OBD_HS,EBCM_HS
 SG_ ACCPerfMdCsStReq : 28|3@0+ (1,0) [0|7] ""  CGM_HS,EBCM_OBD_HS,EBCM_HS
 SG_ PrkAstAdvSysAct : 8|1@0+ (1,0) [0|1] ""  CGM_HS
 SG_ SndPerfMdCsStRq : 18|3@0+ (1,0) [0|7] ""  CGM_HS,EBCM_OBD_HS,EBCM_HS
 SG_ HptcStVbnStat : 2|2@0+ (1,0) [0|3] ""  CGM_HS
 SG_ ACCSettingType : 10|2@0+ (1,0) [0|3] ""  CGM_HS
 SG_ FCABrkPrflReq : 13|1@0+ (1,0) [0|1] ""  CGM_HS,EBCM_OBD_HS,EBCM_HS
 SG_ ISA2CCC_ScndCdChr : 36|5@0+ (1,0) [0|31] ""  CGM_HS
 SG_ ISA2CCC_FrstCdChr : 25|5@0+ (1,0) [0|31] ""  CGM_HS
 SG_ DispPerfMdCsStRq : 21|3@0+ (1,0) [0|7] ""  CGM_HS,EBCM_OBD_HS,EBCM_HS
 SG_ CrshAlrtStPrsnt : 0|1@0+ (1,0) [0|1] ""  CGM_HS,EBCM_OBD_HS,EBCM_HS
 SG_ FwdClnAlrtCustStngReq : 5|3@0+ (1,0) [0|7] ""  CGM_HS
 SG_ GNCustStngReq : 7|2@0+ (1,0) [0|3] ""  CGM_HS

BO_ 1328 Alarm_Clock_Status_HS: 4 BCM_HS
 SG_ ACSAlarm9 : 21|2@0+ (1,0) [0|3] ""  ICCM_OBD_HS,ICCM_HS
 SG_ ACSAlarm8 : 23|2@0+ (1,0) [0|3] ""  ICCM_OBD_HS,ICCM_HS
 SG_ ACSAlarm7 : 9|2@0+ (1,0) [0|3] ""  ICCM_OBD_HS,ICCM_HS
 SG_ ACSAlarm6 : 11|2@0+ (1,0) [0|3] ""  ICCM_OBD_HS,ICCM_HS
 SG_ ACSAlarm5 : 13|2@0+ (1,0) [0|3] ""  ICCM_OBD_HS,ICCM_HS
 SG_ ACSAlarm4 : 15|2@0+ (1,0) [0|3] ""  ICCM_OBD_HS,ICCM_HS
 SG_ ACSAlarm3 : 1|2@0+ (1,0) [0|3] ""  ICCM_OBD_HS,ICCM_HS
 SG_ ACSAlarm2 : 3|2@0+ (1,0) [0|3] ""  ICCM_OBD_HS,ICCM_HS
 SG_ ACSAlarm15 : 25|2@0+ (1,0) [0|3] ""  ICCM_OBD_HS,ICCM_HS
 SG_ ACSAlarm14 : 27|2@0+ (1,0) [0|3] ""  ICCM_OBD_HS,ICCM_HS
 SG_ ACSAlarm13 : 29|2@0+ (1,0) [0|3] ""  ICCM_OBD_HS,ICCM_HS
 SG_ ACSAlarm12 : 31|2@0+ (1,0) [0|3] ""  ICCM_OBD_HS,ICCM_HS
 SG_ ACSAlarm11 : 17|2@0+ (1,0) [0|3] ""  ICCM_OBD_HS,ICCM_HS
 SG_ ACSAlarm10 : 19|2@0+ (1,0) [0|3] ""  ICCM_OBD_HS,ICCM_HS
 SG_ ACSAlarm1 : 5|2@0+ (1,0) [0|3] ""  ICCM_OBD_HS,ICCM_HS
 SG_ ACSAlarm0 : 7|2@0+ (1,0) [0|3] ""  ICCM_OBD_HS,ICCM_HS

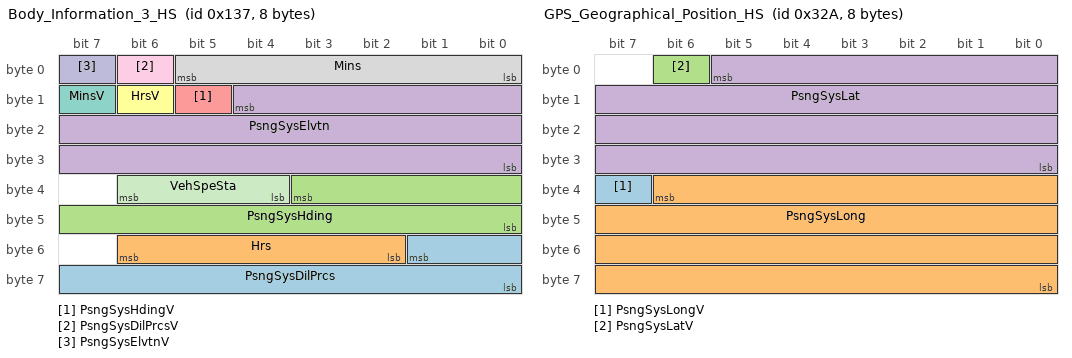
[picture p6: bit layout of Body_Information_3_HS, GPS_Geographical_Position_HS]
BO_ 311 Body_Information_3_HS: 8 BCM_HS
 SG_ PsngSysDilPrcs : 49|10@0+ (0.1,0) [0|102.3] ""  CGM_HS
 SG_ Hrs : 54|5@0+ (1,0) [0|31] "h"  CGM_HS
 SG_ PsngSysHding : 35|12@0+ (0.1,0) [0|409.5] "deg"  CGM_HS
 SG_ PsngSysElvtn : 12|21@0+ (1,-100000) [-100000|1997151] "cm"  CGM_HS
 SG_ PsngSysHdingV : 13|1@0+ (1,0) [0|1] ""  CGM_HS
 SG_ HrsV : 14|1@0+ (1,0) [0|1] ""  CGM_HS
 SG_ MinsV : 15|1@0+ (1,0) [0|1] ""  CGM_HS
 SG_ Mins : 5|6@0+ (1,0) [0|63] "min"  CGM_HS
 SG_ PsngSysDilPrcsV : 6|1@0+ (1,0) [0|1] ""  CGM_HS
 SG_ PsngSysElvtnV : 7|1@0+ (1,0) [0|1] ""  CGM_HS
 SG_ VehSpeSta : 38|3@0+ (1,0) [0|7] ""  CGM_HS

BO_ 810 GPS_Geographical_Position_HS: 8 BCM_HS
 SG_ PsngSysLongV : 39|1@0+ (1,0) [0|1] ""  CGM_HS,EBCM_OBD_HS,EBCM_HS
 SG_ PsngSysLong : 38|31@0- (1,0) [-1073741824|1073741823] "ms arc"  CGM_HS,EBCM_OBD_HS,EBCM_HS
 SG_ PsngSysLatV : 6|1@0+ (1,0) [0|1] ""  CGM_HS,EBCM_OBD_HS,EBCM_HS
 SG_ PsngSysLat : 5|30@0- (1,0) [-536870912|536870911] "ms arc"  CGM_HS,EBCM_OBD_HS,EBCM_HS

BO_ 304 Content_Theft_Sensor_Status_HS: 1 BCM_HS
 SG_ PedFrndlyAlrtCsStReq : 5|3@0+ (1,0) [0|7] ""  CGM_HS
 SG_ AlrmStat : 2|3@0+ (1,0) [0|7] ""  CGM_HS,ICCM_OBD_HS,ICCM_HS

BO_ 1345 UUDT_Resp_From_BCM_HS: 8 BCM_HS
 SG_ DgnInf_HS541 : 7|64@0+ (1,0) [0|1.84467440737096E+019] ""  CGM_HS,ONSTAR_HS,TestTool_HS

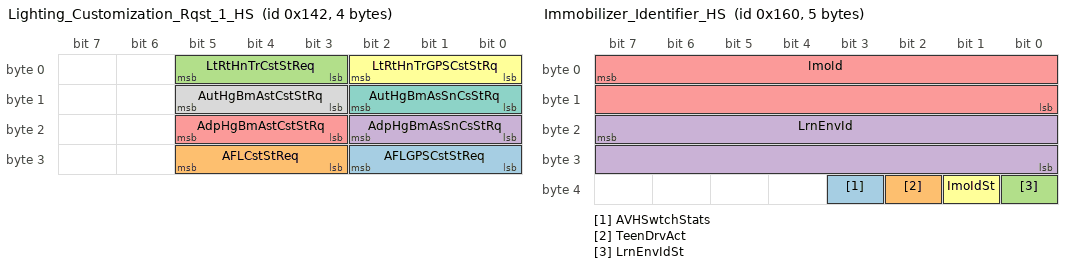
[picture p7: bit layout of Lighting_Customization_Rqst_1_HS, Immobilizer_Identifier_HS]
BO_ 322 Lighting_Customization_Rqst_1_HS: 4 BCM_HS
 SG_ AFLGPSCstStReq : 26|3@0+ (1,0) [0|7] ""  CGM_HS
 SG_ AFLCstStReq : 29|3@0+ (1,0) [0|7] ""  CGM_HS
 SG_ LtRtHnTrCstStReq : 5|3@0+ (1,0) [0|7] ""  CGM_HS
 SG_ AdpHgBmAsSnCsStRq : 18|3@0+ (1,0) [0|7] ""  CGM_HS
 SG_ AdpHgBmAstCstStRq : 21|3@0+ (1,0) [0|7] ""  CGM_HS
 SG_ LtRtHnTrGPSCstStRq : 2|3@0+ (1,0) [0|7] ""  CGM_HS
 SG_ AutHgBmAsSnCsStRq : 10|3@0+ (1,0) [0|7] ""  CGM_HS
 SG_ AutHgBmAstCstStRq : 13|3@0+ (1,0) [0|7] ""  CGM_HS

BO_ 309 Body_Information_2_HS: 8 BCM_HS
 SG_ StBltTgtCSRq : 23|3@0+ (1,0) [0|7] ""  CGM_HS,EBCM_OBD_HS,EBCM_HS
 SG_ ColPrSysCustReq : 15|3@0+ (1,0) [0|7] ""  CGM_HS
 SG_ SecV : 62|1@0+ (1,0) [0|1] ""  CGM_HS
 SG_ Sec : 61|6@0+ (1,0) [0|63] "s"  CGM_HS
 SG_ CldrYr_154 : 55|8@0+ (1,2000) [2000|2255] "year"  CGM_HS
 SG_ CldrYr : 47|8@0+ (1,2000) [2000|2255] "year"  CGM_HS,EBCM_OBD_HS,EBCM_HS
 SG_ CldrMth_154 : 39|4@0+ (1,0) [0|15] ""  CGM_HS
 SG_ CldrMth : 35|4@0+ (1,0) [0|15] ""  CGM_HS,EBCM_OBD_HS,EBCM_HS
 SG_ CldrDay_154 : 30|5@0+ (1,0) [0|31] "days"  CGM_HS
 SG_ CldrDay : 20|5@0+ (1,0) [0|31] "days"  CGM_HS,EBCM_OBD_HS,EBCM_HS
 SG_ PedFrndlyAlrtSndMnAct : 8|1@0+ (1,0) [0|1] ""  CGM_HS
 SG_ AutoHiBmVDA : 25|1@0+ (1,0) [0|1] ""  CGM_HS
 SG_ CtLghtDet : 24|1@0+ (1,0) [0|1] ""  CGM_HS
 SG_ RrClosVDA : 11|1@0+ (1,0) [0|1] ""  CGM_HS,ICCM_OBD_HS,ICCM_HS
 SG_ TCSysDisSwAtv : 4|1@0+ (1,0) [0|1] ""  CGM_HS,EBCM_OBD_HS,EBCM_HS
 SG_ VehMovState : 2|3@0+ (1,0) [0|7] ""  CGM_HS,EBCM_OBD_HS,HMIM_HS,EBCM_HS
 SG_ TCSysDisSwAtvV : 3|1@0+ (1,0) [0|1] ""  CGM_HS,EBCM_OBD_HS,EBCM_HS
 SG_ HillDesCtrlMdSwActV : 10|1@0+ (1,0) [0|1] ""  CGM_HS,EBCM_OBD_HS,EBCM_HS
 SG_ WSWshSwAtv : 5|1@0+ (1,0) [0|1] ""  CGM_HS
 SG_ HillDesCtrlMdSwAct : 9|1@0+ (1,0) [0|1] ""  CGM_HS,EBCM_OBD_HS,EBCM_HS
 SG_ RrClosAjarSwAct : 12|1@0+ (1,0) [0|1] ""  CGM_HS,ICCM_OBD_HS,ICCM_HS
 SG_ WSWprAct : 6|1@0+ (1,0) [0|1] ""  CGM_HS,EBCM_OBD_HS,EBCM_HS

BO_ 352 Immobilizer_Identifier_HS: 5 BCM_HS
 SG_ AVHSwtchStats : 35|1@0+ (1,0) [0|1] ""  EBCM_OBD_HS,EBCM_HS
 SG_ TeenDrvAct : 34|1@0+ (1,0) [0|1] ""  CGM_HS,EBCM_OBD_HS,EBCM_HS
 SG_ LrnEnvIdSt : 32|1@0+ (1,0) [0|1] ""  CGM_HS,EBCM_OBD_HS,ONSTAR_HS,EBCM_HS
 SG_ LrnEnvId : 23|16@0+ (1,0) [0|65535] ""  CGM_HS,EBCM_OBD_HS,ONSTAR_HS,EBCM_HS
 SG_ ImoId : 7|16@0+ (1,0) [0|65535] ""  CGM_HS,EBCM_OBD_HS,ONSTAR_HS,EBCM_HS
 SG_ ImoIdSt : 33|1@0+ (1,0) [0|1] ""  CGM_HS,EBCM_OBD_HS,ONSTAR_HS,EBCM_HS

BO_ 2041 PCU_Resp_From_SDM_HS: 8 BCM_HS
 SG_ PCUInfo_7F9 : 7|64@0+ (1,0) [0|1.84467440737096E+019] ""  TestTool_HS

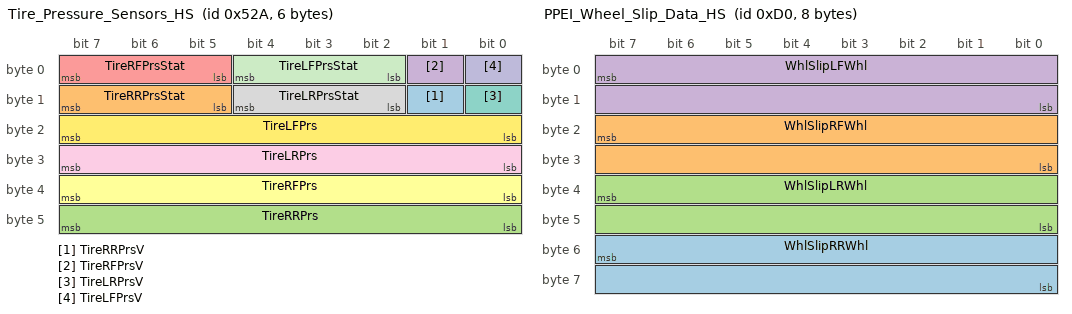
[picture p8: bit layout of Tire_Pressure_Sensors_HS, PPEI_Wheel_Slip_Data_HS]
BO_ 1322 Tire_Pressure_Sensors_HS: 6 BCM_HS
 SG_ TireRRPrsV : 9|1@0+ (1,0) [0|1] ""  CGM_HS,ICCM_OBD_HS,EBCM_OBD_HS,ICCM_HS,EBCM_HS
 SG_ TireRRPrsStat : 15|3@0+ (1,0) [0|7] ""  CGM_HS,ICCM_OBD_HS,EBCM_OBD_HS,ICCM_HS,EBCM_HS
 SG_ TireRRPrs : 47|8@0+ (4,0) [0|1020] "kPaG"  CGM_HS,ICCM_OBD_HS,EBCM_OBD_HS,ICCM_HS,EBCM_HS
 SG_ TireRFPrsV : 1|1@0+ (1,0) [0|1] ""  CGM_HS,ICCM_OBD_HS,EBCM_OBD_HS,ICCM_HS,EBCM_HS
 SG_ TireRFPrsStat : 7|3@0+ (1,0) [0|7] ""  CGM_HS,ICCM_OBD_HS,EBCM_OBD_HS,ICCM_HS,EBCM_HS
 SG_ TireRFPrs : 39|8@0+ (4,0) [0|1020] "kPaG"  CGM_HS,ICCM_OBD_HS,EBCM_OBD_HS,ICCM_HS,EBCM_HS
 SG_ TireLRPrsV : 8|1@0+ (1,0) [0|1] ""  CGM_HS,ICCM_OBD_HS,EBCM_OBD_HS,ICCM_HS,EBCM_HS
 SG_ TireLRPrsStat : 12|3@0+ (1,0) [0|7] ""  CGM_HS,ICCM_OBD_HS,EBCM_OBD_HS,ICCM_HS,EBCM_HS
 SG_ TireLRPrs : 31|8@0+ (4,0) [0|1020] "kPaG"  CGM_HS,ICCM_OBD_HS,EBCM_OBD_HS,ICCM_HS,EBCM_HS
 SG_ TireLFPrsV : 0|1@0+ (1,0) [0|1] ""  CGM_HS,ICCM_OBD_HS,EBCM_OBD_HS,ICCM_HS,EBCM_HS
 SG_ TireLFPrsStat : 4|3@0+ (1,0) [0|7] ""  CGM_HS,ICCM_OBD_HS,EBCM_OBD_HS,ICCM_HS,EBCM_HS
 SG_ TireLFPrs : 23|8@0+ (4,0) [0|1020] "kPaG"  CGM_HS,ICCM_OBD_HS,EBCM_OBD_HS,ICCM_HS,EBCM_HS

BO_ 1601 USDT_Resp_From_BCM_HS: 8 BCM_HS
 SG_ DgnInf : 7|64@0+ (1,0) [0|1.84467440737096E+019] ""  CGM_HS,TestTool_HS,ONSTAR_HS

BO_ 1300 VIN_Digits_2_to_9_HS: 8 BCM_HS
 SG_ VehIdNmDig2_9 : 7|64@0+ (1,0) [0|1] ""  CGM_HS,EBCM_OBD_HS,EPS_HS,EPB_HS,TCCM_HS,EBCM_HS

BO_ 288 Vehicle_Odometer_HS: 5 BCM_HS
 SG_ VehOdo : 7|32@0+ (0.015625,0) [0|67108863.984375] "km"  CGM_HS,EBCM_OBD_HS,EPB_HS,TCCM_HS,EBCM_HS
 SG_ VehOdoV : 32|1@0+ (1,0) [0|1] ""  CGM_HS,EBCM_OBD_HS,EPB_HS,TCCM_HS,EBCM_HS

BO_ 208 PPEI_Wheel_Slip_Data_HS: 8 EBCM_HS
 SG_ WhlSlipRRWhl : 55|16@0+ (0.390625,-12800) [-12800|12799.609375] "%"  TCM_HS
 SG_ WhlSlipRFWhl : 23|16@0+ (0.390625,-12800) [-12800|12799.609375] "%"  TCM_HS
 SG_ WhlSlipLRWhl : 39|16@0+ (0.390625,-12800) [-12800|12799.609375] "%"  TCM_HS
 SG_ WhlSlipLFWhl : 7|16@0+ (0.390625,-12800) [-12800|12799.609375] "%"  TCM_HS

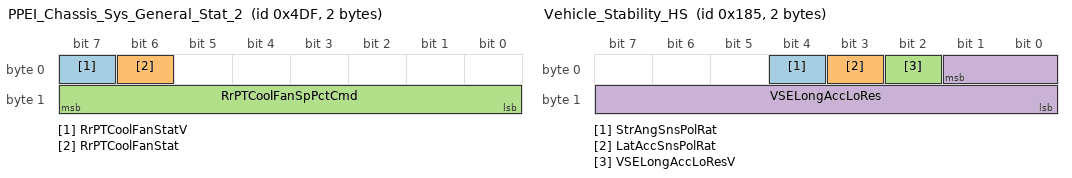
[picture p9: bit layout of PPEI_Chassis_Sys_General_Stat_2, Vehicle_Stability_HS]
BO_ 1247 PPEI_Chassis_Sys_General_Stat_2: 2 ICCM_HS
 SG_ RrPTCoolFanStatV : 7|1@0+ (1,0) [0|1] ""  TCM_HS
 SG_ RrPTCoolFanStat : 6|1@0+ (1,0) [0|1] ""  TCM_HS
 SG_ RrPTCoolFanSpPctCmd : 15|8@0+ (0.392157,0) [0|100.000035] "%"  TCM_HS

BO_ 389 Vehicle_Stability_HS: 2 EBCM_HS
 SG_ StrAngSnsPolRat : 4|1@0+ (1,0) [0|1] ""  CGM_HS,EPS_HS
 SG_ LatAccSnsPolRat : 3|1@0+ (1,0) [0|1] ""  CGM_HS,EPS_HS
 SG_ VSELongAccLoResV : 2|1@0+ (1,0) [0|1] ""  CGM_HS,ICCM_OBD_HS,EPS_HS,ICCM_HS,EPB_HS,BCM_HS,TCM_HS
 SG_ VSELongAccLoRes : 1|10@0- (0.03,0) [-15.36|15.33] "m/s^2"  CGM_HS,ICCM_OBD_HS,EPS_HS,ICCM_HS,EPB_HS,BCM_HS,TCM_HS

BO_ 2018 USDT_Req_to_TCM_MTA_MTIO_HS: 8 TestTool_HS
 SG_ DgnInf : 7|64@0+ (1,0) [0|1.84467440737096E+019] ""  TCM_HS

BO_ 1013 PPEI_Trans_General_Status_4_HS: 1 TCM_HS
 SG_ Sig1889 : 1|2@0+ (1,0) [0|3] ""  EBCM_OBD_HS,EBCM_HS
 SG_ Sig1888 : 3|2@0+ (1,0) [0|3] ""  EBCM_OBD_HS,EBCM_HS

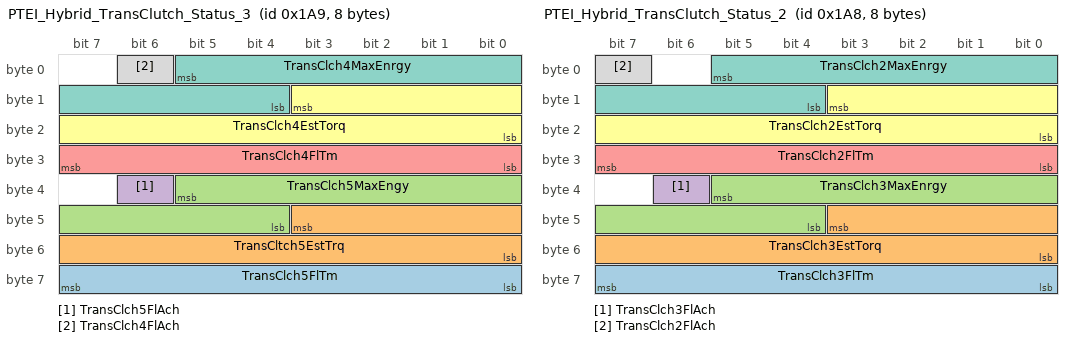
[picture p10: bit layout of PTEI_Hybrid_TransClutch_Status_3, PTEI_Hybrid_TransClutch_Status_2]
BO_ 425 PTEI_Hybrid_TransClutch_Status_3: 8 TCM_HS
 SG_ TransClch5FlTm : 63|8@0+ (0.0125,0) [0|3.1875] "s" Vector__XXX
 SG_ TransCltch5EstTrq : 43|12@0+ (0.5,-5) [-5|2042.5] "Nm" Vector__XXX
 SG_ TransClch5MaxEngy : 37|10@0+ (50,0) [0|51150] "J" Vector__XXX
 SG_ TransClch5FlAch : 38|1@0+ (1,0) [0|1] "" Vector__XXX
 SG_ TransClch4FlTm : 31|8@0+ (0.0125,0) [0|3.1875] "s" Vector__XXX
 SG_ TransClch4EstTorq : 11|12@0+ (0.5,-5) [-5|2042.5] "Nm" Vector__XXX
 SG_ TransClch4MaxEnrgy : 5|10@0+ (50,0) [0|51150] "J" Vector__XXX
 SG_ TransClch4FlAch : 6|1@0+ (1,0) [0|1] "" Vector__XXX

BO_ 424 PTEI_Hybrid_TransClutch_Status_2: 8 TCM_HS
 SG_ TransClch3FlTm : 63|8@0+ (0.0125,0) [0|3.1875] "s" Vector__XXX
 SG_ TransClch3EstTorq : 43|12@0+ (0.5,-5) [-5|2042.5] "Nm" Vector__XXX
 SG_ TransClch3MaxEnrgy : 37|10@0+ (50,0) [0|51150] "J" Vector__XXX
 SG_ TransClch3FlAch : 38|1@0+ (1,0) [0|1] "" Vector__XXX
 SG_ TransClch2FlTm : 31|8@0+ (0.0125,0) [0|3.1875] "s" Vector__XXX
 SG_ TransClch2EstTorq : 11|12@0+ (0.5,-5) [-5|2042.5] "Nm" Vector__XXX
 SG_ TransClch2MaxEnrgy : 5|10@0+ (50,0) [0|51150] "J" Vector__XXX
 SG_ TransClch2FlAch : 7|1@0+ (1,0) [0|1] "" Vector__XXX

BO_TX_BU_ 594 : ONSTAR_HS,TestTool_HS;
BO_TX_BU_ 593 : CGM_HS,ONSTAR_HS,TestTool_HS;
BO_TX_BU_ 597 : CGM_HS,ONSTAR_HS,TestTool_HS;
BO_TX_BU_ 592 : CGM_HS,ONSTAR_HS,TestTool_HS;
BO_TX_BU_ 582 : CGM_HS,ONSTAR_HS,TestTool_HS;
BO_TX_BU_ 601 : CGM_HS,ONSTAR_HS,TestTool_HS;
BO_TX_BU_ 2023 : CGM_HS,ONSTAR_HS,TestTool_HS;
BO_TX_BU_ 2021 : CGM_HS,ONSTAR_HS,TestTool_HS;
BO_TX_BU_ 2019 : CGM_HS,ONSTAR_HS,TestTool_HS;
BO_TX_BU_ 578 : CGM_HS,ONSTAR_HS,TestTool_HS;
BO_TX_BU_ 2022 : CGM_HS,ONSTAR_HS,TestTool_HS;
BO_TX_BU_ 584 : CGM_HS,ONSTAR_HS,TestTool_HS;
BO_TX_BU_ 586 : CGM_HS,ONSTAR_HS,TestTool_HS;
BO_TX_BU_ 588 : CGM_HS,ONSTAR_HS,TestTool_HS;
BO_TX_BU_ 580 : CGM_HS,ONSTAR_HS,TestTool_HS;
BO_TX_BU_ 2020 : CGM_HS,ONSTAR_HS,TestTool_HS;
BO_TX_BU_ 599 : CGM_HS,ONSTAR_HS,TestTool_HS;
BO_TX_BU_ 2017 : CGM_HS,ONSTAR_HS,TestTool_HS;
BO_TX_BU_ 581 : CGM_HS,ONSTAR_HS,TestTool_HS;
BO_TX_BU_ 585 : CGM_HS,ONSTAR_HS,TestTool_HS;
BO_TX_BU_ 590 : CGM_HS,ONSTAR_HS,TestTool_HS;
BO_TX_BU_ 596 : CGM_HS,ONSTAR_HS,TestTool_HS;
BO_TX_BU_ 1364 : CGM_HS,EPB_HS;
BO_TX_BU_ 1620 : CGM_HS,EPB_HS;
BO_TX_BU_ 587 : CGM_HS,ONSTAR_HS,TestTool_HS;
BO_TX_BU_ 598 : CGM_HS,ONSTAR_HS,TestTool_HS;
BO_TX_BU_ 591 : CGM_HS,ONSTAR_HS,TestTool_HS;
BO_TX_BU_ 583 : CGM_HS,ONSTAR_HS,TestTool_HS;
BO_TX_BU_ 577 : CGM_HS,ONSTAR_HS,TestTool_HS;
BO_TX_BU_ 804 : ICCM_OBD_HS,ICCM_HS;
BO_TX_BU_ 842 : EBCM_OBD_HS,EBCM_HS;
BO_TX_BU_ 840 : EBCM_OBD_HS,EBCM_HS;
BO_TX_BU_ 208 : EBCM_OBD_HS,EBCM_HS;
BO_TX_BU_ 1247 : ICCM_OBD_HS,ICCM_HS;
BO_TX_BU_ 389 : EBCM_OBD_HS,EBCM_HS;
BO_TX_BU_ 2018 : CGM_HS,ONSTAR_HS,TestTool_HS;
CM_ SG_ 3221225472 PTORelBrkPedIO "Power Take Off state0800 Brake Pedal To Engage Indication On";
CM_ SG_ 1910 DTCI_DTCFaultType_776 "Based on Powertrain definition.  Not expected to be supported by all devices.";
CM_ SG_ 1910 DTCI_DTCFailType_776 "Assigned per GMW3110, Appendix E";
CM_ SG_ 1910 DTCI_DTCSource_776 "This shall be equal to the Diagnostic Address of the transmittting device.";
CM_ SG_ 1916 DTCI_DTCFaultType_77C "Based on Powertrain definition.  Not expected to be supported by all devices.";
CM_ SG_ 1916 DTCI_DTCFailType_77C "Assigned per GMW3110, Appendix E";
CM_ SG_ 1916 DTCI_DTCSource_77C "This shall be equal to the Diagnostic Address of the transmittting device.";
CM_ SG_ 1917 DTCI_DTCFaultType_77D "Based on Powertrain definition.  Not expected to be supported by all devices.";
CM_ SG_ 1917 DTCI_DTCFailType_77D "Assigned per GMW3110, Appendix E";
CM_ SG_ 1917 DTCI_DTCSource_77D "This shall be equal to the Diagnostic Address of the transmittting device.";
CM_ SG_ 1930 DTCI_DTCFailType_78A "Assigned per GMW3110, Appendix E";
CM_ SG_ 1930 DTCI_DTCFaultType_78A "Based on Powertrain definition.  Not expected to be supported by all devices.";
CM_ SG_ 1930 DTCI_DTCSource_78A "This shall be equal to the Diagnostic Address of the transmittting device.";
CM_ SG_ 1914 DTCI_DTCFaultType_77A "Based on Powertrain definition.  Not expected to be supported by all devices.";
CM_ SG_ 1914 DTCI_DTCFailType_77A "Assigned per GMW3110, Appendix E";
CM_ SG_ 1914 DTCI_DTCSource_77A "This shall be equal to the Diagnostic Address of the transmittting device.";
CM_ SG_ 311 PsngSysHding "The 'usable' range is somewhat less than the encoded range (0.0 to 359.9 degrees).  0.0 degrees represents North, 90.0 degrees represents East.";
CM_ SG_ 810 PsngSysLong "The units of the data are milli-arcseconds (1/3,600,000 of a degree).  The actual 'usable' range of this data is somewhat less than the encoded range (+/- 648,000,000, corresponding to +/- 180 degrees)";
CM_ SG_ 810 PsngSysLat "The units of the data are milli-arcseconds (1/3,600,000 of a degree).  The actual 'usable' range of this data is somewhat less than the encoded range (+/- 324,000,000, corresponding to +/- 90 degrees)";
CM_ SG_ 1300 VehIdNmDig2_9 "Desc: 8 ASCII Characters";
BA_DEF_ SG_  "VNSigSLHSSharedDiagnostic" ENUM  "No","Yes";
BA_DEF_ SG_  "VNSigSLHS_VNReq" ENUM  "No","Yes";
BA_DEF_ SG_  "GenSigSendOnInit" ENUM  "Not Initialized","Application","Handler";
BA_DEF_ SG_  "GenSigSendType" ENUM  "not used","not used","not used","not used","not used","not used","not used","NoSigSendType","not used","not used","OnAnyChange","OnChangeIfActive","OnDelta";
BA_DEF_ SG_  "GenSigDeltaValue" INT 0 0;
BA_DEF_ SG_  "VNSigAllNodes" ENUM  "No","Yes";
BA_DEF_ SG_  "SignalType" STRING ;
BA_DEF_ SG_  "PacketOrder" INT 0 65535;
BA_DEF_ SG_  "SignalLongName" STRING ;
BA_DEF_ SG_  "GenSigStartValue" INT 0 65535;
BA_DEF_ SG_  "TxSignalSendOnInit" ENUM  "Not Initialized","Application","Handler";
BA_DEF_ BO_  "GenMsgILSupport" ENUM  "No","Yes";
BA_DEF_ BO_  "AppGenMsgCycleTime" INT 0 0;
BA_DEF_ BO_  "TpApplType" STRING ;
BA_DEF_ BO_  "Prio" INT 0 7;
BA_DEF_ BO_  "MessageSubnet" ENUM  "LS","MS","HS","CE","PE","HV","FO","S1","HE","LE","HE2","vector_leerstring";
BA_DEF_ BO_  "DiagState" ENUM  "No","Yes";
BA_DEF_ BO_  "GenMsgIlSupport" ENUM  "No","Yes";
BA_DEF_ BO_  "GenMsgStartDelayTime" INT 0 100000;
BA_DEF_ BO_  "GenMsgDelayTime" INT 0 100000;
BA_DEF_ BO_  "GenMsgCycleTime" INT 0 100000;
BA_DEF_ BO_  "GenMsgSendType" ENUM  "cyclicX","spontanX","cyclicIfActiveX","spontanWithDelay","cyclicAndSpontanX","cyclicAndSpontanWithDelay","spontanWithRepitition","cyclicIfActiveAndSpontanWD";
BA_DEF_ BO_  "DiagResponse" ENUM  "No","Yes";
BA_DEF_ BO_  "DiagRequest" ENUM  "No","Yes";
BA_DEF_ BO_  "NmMessage" ENUM  "No","Yes";
BA_DEF_REL_ BU_SG_REL_  "GenSigSuprvResp" ENUM  "None","Notify App","Substitute Default";
BA_DEF_REL_ BU_SG_REL_  "GenSigSuprvRespSubValue" INT 0 65535;
BA_DEF_REL_ BU_SG_REL_  "GenSigRxStartValue" STRING ;
BA_DEF_REL_ BU_SG_REL_  "GenSigVDAFailResp" ENUM  "No","Yes";
BA_DEF_REL_ BU_SG_REL_  "GenSigVDAFailComment" STRING ;
BA_DEF_REL_ BU_SG_REL_  "GenSigVBitRespComment" STRING ;
BA_DEF_REL_ BU_SG_REL_  "GenSigVBitResp" ENUM  "No","Yes";
BA_DEF_REL_ BU_SG_REL_  "GenSigSuprvRespComment" STRING ;
BA_DEF_REL_ BU_SG_REL_  "GenSigTimeoutMsg" HEX 0 268435455;
BA_DEF_REL_ BU_SG_REL_  "GenSigTimeoutTime" INT 0 5000;
BA_DEF_DEF_  "VNSigSLHSSharedDiagnostic" "No";
BA_DEF_DEF_  "VNSigSLHS_VNReq" "No";
BA_DEF_DEF_  "GenSigSendOnInit" "Not Initialized";
BA_DEF_DEF_  "GenSigSendType" "NoSigSendType";
BA_DEF_DEF_  "GenSigDeltaValue" 0;
BA_DEF_DEF_  "VNSigAllNodes" "No";
BA_DEF_DEF_  "SignalType" "";
BA_DEF_DEF_  "PacketOrder" 0;
BA_DEF_DEF_  "SignalLongName" "";
BA_DEF_DEF_  "GenSigStartValue" 0;
BA_DEF_DEF_  "TxSignalSendOnInit" "Not Initialized";
BA_DEF_DEF_  "GenMsgILSupport" "Yes";
BA_DEF_DEF_  "AppGenMsgCycleTime" 0;
BA_DEF_DEF_  "TpApplType" "";
BA_DEF_DEF_  "Prio" 0;
BA_DEF_DEF_  "MessageSubnet" "LS";
BA_DEF_DEF_  "DiagState" "No";
BA_DEF_DEF_  "GenMsgIlSupport" "Yes";
BA_DEF_DEF_  "GenMsgStartDelayTime" 0;
BA_DEF_DEF_  "GenMsgDelayTime" 0;
BA_DEF_DEF_  "GenMsgCycleTime" 0;
BA_DEF_DEF_  "GenMsgSendType" "spontanX";
BA_DEF_DEF_  "DiagResponse" "No";
BA_DEF_DEF_  "DiagRequest" "No";
BA_DEF_DEF_  "NmMessage" "No";
BA_DEF_DEF_REL_ "GenSigSuprvResp" "None";
BA_DEF_DEF_REL_ "GenSigSuprvRespSubValue" 0;
BA_DEF_DEF_REL_ "GenSigRxStartValue" "";
BA_DEF_DEF_REL_ "GenSigVDAFailResp" "No";
BA_DEF_DEF_REL_ "GenSigVDAFailComment" "";
BA_DEF_DEF_REL_ "GenSigVBitRespComment" "";
BA_DEF_DEF_REL_ "GenSigVBitResp" "No";
BA_DEF_DEF_REL_ "GenSigSuprvRespComment" "";
BA_DEF_DEF_REL_ "GenSigTimeoutMsg" 0;
BA_DEF_DEF_REL_ "GenSigTimeoutTime" 0;
BA_ "GenMsgSendType" BO_ 558 0;
BA_ "GenMsgCycleTime" BO_ 558 100;
BA_ "MessageSubnet" BO_ 558 2;
BA_ "GenMsgSendType" BO_ 550 0;
BA_ "GenMsgCycleTime" BO_ 550 500;
BA_ "MessageSubnet" BO_ 550 2;
BA_ "GenMsgSendType" BO_ 546 0;
BA_ "GenMsgCycleTime" BO_ 546 100;
BA_ "MessageSubnet" BO_ 546 2;
BA_ "GenMsgSendType" BO_ 289 0;
BA_ "GenMsgCycleTime" BO_ 289 20;
BA_ "MessageSubnet" BO_ 289 2;
BA_ "DiagResponse" BO_ 861 1;
BA_ "MessageSubnet" BO_ 861 2;
BA_ "DiagRequest" BO_ 594 1;
BA_ "MessageSubnet" BO_ 594 2;
BA_ "DiagRequest" BO_ 593 1;
BA_ "MessageSubnet" BO_ 593 2;
BA_ "DiagRequest" BO_ 597 1;
BA_ "MessageSubnet" BO_ 597 2;
BA_ "DiagRequest" BO_ 592 1;
BA_ "MessageSubnet" BO_ 592 2;
BA_ "DiagRequest" BO_ 589 1;
BA_ "MessageSubnet" BO_ 589 2;
BA_ "DiagRequest" BO_ 582 1;
BA_ "MessageSubnet" BO_ 582 2;
BA_ "DiagRequest" BO_ 601 1;
BA_ "MessageSubnet" BO_ 601 2;
BA_ "DiagRequest" BO_ 2023 1;
BA_ "MessageSubnet" BO_ 2023 2;
BA_ "DiagRequest" BO_ 2021 1;
BA_ "MessageSubnet" BO_ 2021 2;
BA_ "DiagRequest" BO_ 2019 1;
BA_ "MessageSubnet" BO_ 2019 2;
BA_ "DiagRequest" BO_ 578 1;
BA_ "MessageSubnet" BO_ 578 2;
BA_ "DiagRequest" BO_ 2022 1;
BA_ "MessageSubnet" BO_ 2022 2;
BA_ "DiagRequest" BO_ 584 1;
BA_ "MessageSubnet" BO_ 584 2;
BA_ "DiagRequest" BO_ 586 1;
BA_ "MessageSubnet" BO_ 586 2;
BA_ "DiagRequest" BO_ 588 1;
BA_ "MessageSubnet" BO_ 588 2;
BA_ "GenMsgILSupport" BO_ 588 0;
BA_ "DiagRequest" BO_ 580 1;
BA_ "MessageSubnet" BO_ 580 2;
BA_ "DiagRequest" BO_ 2020 1;
BA_ "MessageSubnet" BO_ 2020 2;
BA_ "DiagRequest" BO_ 599 1;
BA_ "MessageSubnet" BO_ 599 2;
BA_ "DiagRequest" BO_ 2017 1;
BA_ "MessageSubnet" BO_ 2017 2;
BA_ "GenMsgSendType" BO_ 1910 0;
BA_ "GenMsgCycleTime" BO_ 1910 1000;
BA_ "MessageSubnet" BO_ 1910 2;
BA_ "Prio" BO_ 1910 6;
BA_ "DiagResponse" BO_ 2025 1;
BA_ "MessageSubnet" BO_ 2025 2;
BA_ "MessageSubnet" BO_ 1513 2;
BA_ "TpApplType" BO_ 1513 "DiagUUDTResponse";
BA_ "GenMsgILSupport" BO_ 1513 0;
BA_ "DiagRequest" BO_ 581 1;
BA_ "MessageSubnet" BO_ 581 2;
BA_ "DiagRequest" BO_ 585 1;
BA_ "MessageSubnet" BO_ 585 2;
BA_ "GenMsgSendType" BO_ 1916 0;
BA_ "GenMsgCycleTime" BO_ 1916 1000;
BA_ "MessageSubnet" BO_ 1916 2;
BA_ "Prio" BO_ 1916 6;
BA_ "MessageSubnet" BO_ 1353 2;
BA_ "TpApplType" BO_ 1353 "DiagUUDTResponse";
BA_ "GenMsgILSupport" BO_ 1353 0;
BA_ "DiagResponse" BO_ 1609 1;
BA_ "MessageSubnet" BO_ 1609 2;
BA_ "DiagRequest" BO_ 590 1;
BA_ "MessageSubnet" BO_ 590 2;
BA_ "DiagRequest" BO_ 596 1;
BA_ "MessageSubnet" BO_ 596 2;
BA_ "MessageSubnet" BO_ 1364 2;
BA_ "TpApplType" BO_ 1364 "DiagUUDTResponse";
BA_ "GenMsgILSupport" BO_ 1364 0;
BA_ "GenMsgSendType" BO_ 1917 0;
BA_ "GenMsgCycleTime" BO_ 1917 1000;
BA_ "MessageSubnet" BO_ 1917 2;
BA_ "Prio" BO_ 1917 6;
BA_ "DiagResponse" BO_ 1620 1;
BA_ "MessageSubnet" BO_ 1620 2;
BA_ "GenMsgSendType" BO_ 388 0;
BA_ "GenMsgCycleTime" BO_ 388 100;
BA_ "MessageSubnet" BO_ 388 2;
BA_ "DiagRequest" BO_ 587 1;
BA_ "MessageSubnet" BO_ 587 2;
BA_ "GenMsgILSupport" BO_ 587 0;
BA_ "GenMsgSendType" BO_ 884 0;
BA_ "GenMsgCycleTime" BO_ 884 40;
BA_ "MessageSubnet" BO_ 884 2;
BA_ "GenMsgSendType" BO_ 1930 0;
BA_ "GenMsgCycleTime" BO_ 1930 1000;
BA_ "MessageSubnet" BO_ 1930 2;
BA_ "DiagResponse" BO_ 1611 1;
BA_ "MessageSubnet" BO_ 1611 2;
BA_ "GenMsgILSupport" BO_ 1611 0;
BA_ "MessageSubnet" BO_ 1355 2;
BA_ "TpApplType" BO_ 1355 "DiagUUDTResponse";
BA_ "GenMsgILSupport" BO_ 1355 0;
BA_ "DiagRequest" BO_ 598 1;
BA_ "MessageSubnet" BO_ 598 2;
BA_ "MessageSubnet" BO_ 1366 2;
BA_ "TpApplType" BO_ 1366 "DiagUUDTResponse";
BA_ "GenMsgILSupport" BO_ 1366 0;
BA_ "DiagResponse" BO_ 1622 1;
BA_ "MessageSubnet" BO_ 1622 2;
BA_ "DiagRequest" BO_ 591 1;
BA_ "MessageSubnet" BO_ 591 2;
BA_ "GenMsgSendType" BO_ 1914 0;
BA_ "GenMsgCycleTime" BO_ 1914 1000;
BA_ "MessageSubnet" BO_ 1914 2;
BA_ "Prio" BO_ 1914 6;
BA_ "DiagRequest" BO_ 2032 1;
BA_ "MessageSubnet" BO_ 2032 2;
BA_ "DiagRequest" BO_ 583 1;
BA_ "MessageSubnet" BO_ 583 2;
BA_ "DiagResponse" BO_ 2034 1;
BA_ "MessageSubnet" BO_ 2034 2;
BA_ "GenMsgSendType" BO_ 894 0;
BA_ "GenMsgCycleTime" BO_ 894 1500;
BA_ "MessageSubnet" BO_ 894 2;
BA_ "DiagRequest" BO_ 577 1;
BA_ "MessageSubnet" BO_ 577 2;
BA_ "GenMsgSendType" BO_ 804 0;
BA_ "GenMsgCycleTime" BO_ 804 500;
BA_ "MessageSubnet" BO_ 804 2;
BA_ "GenMsgSendType" BO_ 842 0;
BA_ "GenMsgCycleTime" BO_ 842 50;
BA_ "MessageSubnet" BO_ 842 2;
BA_ "GenMsgSendType" BO_ 840 0;
BA_ "GenMsgCycleTime" BO_ 840 50;
BA_ "MessageSubnet" BO_ 840 2;
BA_ "GenMsgSendType" BO_ 1323 0;
BA_ "GenMsgCycleTime" BO_ 1323 1000;
BA_ "GenMsgStartDelayTime" BO_ 1323 50;
BA_ "MessageSubnet" BO_ 1323 2;
BA_ "GenMsgSendType" BO_ 543 0;
BA_ "GenMsgCycleTime" BO_ 543 100;
BA_ "GenMsgStartDelayTime" BO_ 543 110;
BA_ "MessageSubnet" BO_ 543 2;
BA_ "GenMsgSendType" BO_ 313 0;
BA_ "GenMsgCycleTime" BO_ 313 100;
BA_ "GenMsgStartDelayTime" BO_ 313 70;
BA_ "MessageSubnet" BO_ 313 2;
BA_ "GenMsgSendType" BO_ 1328 0;
BA_ "GenMsgCycleTime" BO_ 1328 1000;
BA_ "GenMsgStartDelayTime" BO_ 1328 80;
BA_ "MessageSubnet" BO_ 1328 2;
BA_ "GenMsgSendType" BO_ 311 0;
BA_ "GenMsgCycleTime" BO_ 311 100;
BA_ "GenMsgStartDelayTime" BO_ 311 60;
BA_ "MessageSubnet" BO_ 311 2;
BA_ "GenMsgSendType" BO_ 810 0;
BA_ "GenMsgCycleTime" BO_ 810 100;
BA_ "GenMsgStartDelayTime" BO_ 810 80;
BA_ "MessageSubnet" BO_ 810 2;
BA_ "GenMsgSendType" BO_ 304 0;
BA_ "GenMsgCycleTime" BO_ 304 1000;
BA_ "GenMsgStartDelayTime" BO_ 304 20;
BA_ "MessageSubnet" BO_ 304 2;
BA_ "MessageSubnet" BO_ 1345 2;
BA_ "TpApplType" BO_ 1345 "DiagUUDTResponse";
BA_ "GenMsgILSupport" BO_ 1345 0;
BA_ "GenMsgSendType" BO_ 322 0;
BA_ "GenMsgCycleTime" BO_ 322 100;
BA_ "GenMsgStartDelayTime" BO_ 322 90;
BA_ "MessageSubnet" BO_ 322 2;
BA_ "GenMsgSendType" BO_ 309 0;
BA_ "GenMsgCycleTime" BO_ 309 100;
BA_ "GenMsgStartDelayTime" BO_ 309 50;
BA_ "MessageSubnet" BO_ 309 2;
BA_ "GenMsgSendType" BO_ 352 0;
BA_ "GenMsgCycleTime" BO_ 352 100;
BA_ "GenMsgStartDelayTime" BO_ 352 30;
BA_ "MessageSubnet" BO_ 352 2;
BA_ "MessageSubnet" BO_ 2041 2;
BA_ "GenMsgSendType" BO_ 1322 0;
BA_ "GenMsgCycleTime" BO_ 1322 1000;
BA_ "GenMsgStartDelayTime" BO_ 1322 40;
BA_ "MessageSubnet" BO_ 1322 2;
BA_ "DiagResponse" BO_ 1601 1;
BA_ "MessageSubnet" BO_ 1601 2;
BA_ "GenMsgSendType" BO_ 1300 0;
BA_ "GenMsgCycleTime" BO_ 1300 1000;
BA_ "GenMsgStartDelayTime" BO_ 1300 70;
BA_ "MessageSubnet" BO_ 1300 2;
BA_ "GenMsgSendType" BO_ 288 0;
BA_ "GenMsgCycleTime" BO_ 288 5000;
BA_ "GenMsgStartDelayTime" BO_ 288 10;
BA_ "MessageSubnet" BO_ 288 2;
BA_ "GenMsgSendType" BO_ 208 0;
BA_ "GenMsgCycleTime" BO_ 208 100;
BA_ "MessageSubnet" BO_ 208 2;
BA_ "GenMsgSendType" BO_ 1247 0;
BA_ "GenMsgCycleTime" BO_ 1247 500;
BA_ "MessageSubnet" BO_ 1247 2;
BA_ "GenMsgSendType" BO_ 389 0;
BA_ "GenMsgCycleTime" BO_ 389 20;
BA_ "MessageSubnet" BO_ 389 2;
BA_ "DiagRequest" BO_ 2018 1;
BA_ "MessageSubnet" BO_ 2018 2;
BA_ "GenMsgSendType" BO_ 1013 0;
BA_ "GenMsgCycleTime" BO_ 1013 250;
BA_ "MessageSubnet" BO_ 1013 2;
BA_ "GenMsgSendType" BO_ 425 0;
BA_ "GenMsgCycleTime" BO_ 425 25;
BA_ "MessageSubnet" BO_ 425 2;
BA_ "GenMsgSendType" BO_ 424 0;
BA_ "GenMsgCycleTime" BO_ 424 25;
BA_ "MessageSubnet" BO_ 424 2;
BA_ "SignalLongName" SG_ 3221225472 PTOStdbSpdCsCrStVal "Power Take Off Standby Speed Customization Current Setting Value";
BA_ "SignalType" SG_ 3221225472 PTOStdbSpdCsCrStVal "ENM";
BA_ "VNSigAllNodes" SG_ 3221225472 PTOStdbSpdCsCrStVal 1;
BA_ "SignalLongName" SG_ 3221225472 HVBatChrgCrdAlrtReq "High Voltage Battery Charge Cord Alert Request";
BA_ "SignalType" SG_ 3221225472 HVBatChrgCrdAlrtReq "ENM";
BA_ "VNSigAllNodes" SG_ 3221225472 HVBatChrgCrdAlrtReq 1;
BA_ "GenSigSendType" SG_ 3221225472 HVBatChrgCrdAlrtReq 10;
BA_ "SignalLongName" SG_ 3221225472 PTOSet2SpdCsStAvl "Power Take Off Set 2 Speed Customization Setting Available";
BA_ "SignalType" SG_ 3221225472 PTOSet2SpdCsStAvl "BLN";
BA_ "VNSigAllNodes" SG_ 3221225472 PTOSet2SpdCsStAvl 1;
BA_ "SignalLongName" SG_ 3221225472 PTOSet2SpdCsCrStVal "Power Take Off Set 2 Speed Customization Current Setting Value";
BA_ "SignalType" SG_ 3221225472 PTOSet2SpdCsCrStVal "ENM";
BA_ "VNSigAllNodes" SG_ 3221225472 PTOSet2SpdCsCrStVal 1;
BA_ "SignalLongName" SG_ 3221225472 PTOSet1SpdCsStAvl "Power Take Off Set 1 Speed Customization Setting Available";
BA_ "SignalType" SG_ 3221225472 PTOSet1SpdCsStAvl "BLN";
BA_ "VNSigAllNodes" SG_ 3221225472 PTOSet1SpdCsStAvl 1;
BA_ "SignalLongName" SG_ 3221225472 PTOSet1SpdCsCrStVal "Power Take Off Set 1 Speed Customization Current Setting Value";
BA_ "SignalType" SG_ 3221225472 PTOSet1SpdCsCrStVal "ENM";
BA_ "VNSigAllNodes" SG_ 3221225472 PTOSet1SpdCsCrStVal 1;
BA_ "SignalLongName" SG_ 3221225472 PTOEngRnTmrCsStAvl "Power Take Off Engine Run Timer Customization Setting Available";
BA_ "SignalType" SG_ 3221225472 PTOEngRnTmrCsStAvl "BLN";
BA_ "VNSigAllNodes" SG_ 3221225472 PTOEngRnTmrCsStAvl 1;
BA_ "SignalLongName" SG_ 3221225472 PTOEnRnTmCsCrStVal "Power Take Off Engine Run Timer Customization Current Setting Value";
BA_ "SignalType" SG_ 3221225472 PTOEnRnTmCsCrStVal "ENM";
BA_ "VNSigAllNodes" SG_ 3221225472 PTOEnRnTmCsCrStVal 1;
BA_ "SignalLongName" SG_ 3221225472 ClntCrcFlwRtEst "Coolant Circulation Flow Rate Estimated";
BA_ "SignalType" SG_ 3221225472 ClntCrcFlwRtEst "UNM";
BA_ "VNSigAllNodes" SG_ 3221225472 ClntCrcFlwRtEst 1;
BA_ "GenSigDeltaValue" SG_ 3221225472 ClntCrcFlwRtEst 1;
BA_ "GenSigSendType" SG_ 3221225472 ClntCrcFlwRtEst 12;
BA_ "GenSigSendOnInit" SG_ 3221225472 ClntCrcFlwRtEst 1;
BA_ "SignalLongName" SG_ 3221225472 MntnceMdStEngRq "Maintenance Mode Start Engine Request";
BA_ "SignalType" SG_ 3221225472 MntnceMdStEngRq "BLN";
BA_ "VNSigAllNodes" SG_ 3221225472 MntnceMdStEngRq 1;
BA_ "GenSigSendType" SG_ 3221225472 MntnceMdStEngRq 10;
BA_ "GenSigSendOnInit" SG_ 3221225472 MntnceMdStEngRq 2;
BA_ "SignalLongName" SG_ 3221225472 PTOAccelUpnBrkRelIO "Power Take Off Acceleration Upon Brake state0800 Indication On";
BA_ "SignalType" SG_ 3221225472 PTOAccelUpnBrkRelIO "BLN";
BA_ "VNSigAllNodes" SG_ 3221225472 PTOAccelUpnBrkRelIO 1;
BA_ "SignalLongName" SG_ 3221225472 PTOEngUpnBrkRelIO "Power Take Off Engage Upon Brake state0800 Indication On";
BA_ "SignalType" SG_ 3221225472 PTOEngUpnBrkRelIO "BLN";
BA_ "VNSigAllNodes" SG_ 3221225472 PTOEngUpnBrkRelIO 1;
BA_ "SignalLongName" SG_ 3221225472 PTOManTransInGrIO "Power Take Off Manual Transmission In Gear Indication On";
BA_ "SignalType" SG_ 3221225472 PTOManTransInGrIO "BLN";
BA_ "VNSigAllNodes" SG_ 3221225472 PTOManTransInGrIO 1;
BA_ "SignalLongName" SG_ 3221225472 PTOServIndOn "Power Take Off Service Indication On";
BA_ "SignalType" SG_ 3221225472 PTOServIndOn "BLN";
BA_ "VNSigAllNodes" SG_ 3221225472 PTOServIndOn 1;
BA_ "SignalLongName" SG_ 3221225472 PTOTransInGearIO "Power Take Off Transmission In Gear Indication On";
BA_ "SignalType" SG_ 3221225472 PTOTransInGearIO "BLN";
BA_ "VNSigAllNodes" SG_ 3221225472 PTOTransInGearIO 1;
BA_ "SignalLongName" SG_ 3221225472 PTOSetPrkBrkIO "Power Take Off Set Park Brake Indication On";
BA_ "SignalType" SG_ 3221225472 PTOSetPrkBrkIO "BLN";
BA_ "VNSigAllNodes" SG_ 3221225472 PTOSetPrkBrkIO 1;
BA_ "SignalLongName" SG_ 3221225472 PTORelCltPedIO "Power Take Off state0800 Clutch Pedal Indication On";
BA_ "SignalType" SG_ 3221225472 PTORelCltPedIO "BLN";
BA_ "VNSigAllNodes" SG_ 3221225472 PTORelCltPedIO 1;
BA_ "SignalLongName" SG_ 3221225472 PTORelBrkPedIO "Power Take Off state0800 Brake Pedal Indication On";
BA_ "SignalType" SG_ 3221225472 PTORelBrkPedIO "BLN";
BA_ "VNSigAllNodes" SG_ 3221225472 PTORelBrkPedIO 1;
BA_ "SignalLongName" SG_ 3221225472 PTORelAccPedIO "Power Take Off state0800 Accelerator Pedal Indication On";
BA_ "SignalType" SG_ 3221225472 PTORelAccPedIO "BLN";
BA_ "VNSigAllNodes" SG_ 3221225472 PTORelAccPedIO 1;
BA_ "SignalLongName" SG_ 3221225472 PTORedEngSpdIO "Power Take Off Reduce Engine Speed Indication On";
BA_ "SignalType" SG_ 3221225472 PTORedEngSpdIO "BLN";
BA_ "VNSigAllNodes" SG_ 3221225472 PTORedEngSpdIO 1;
BA_ "SignalLongName" SG_ 3221225472 PTOPrsRelCltPedIO "Power Take Off Press and state0800 Clutch Pedal Indication On";
BA_ "SignalType" SG_ 3221225472 PTOPrsRelCltPedIO "BLN";
BA_ "VNSigAllNodes" SG_ 3221225472 PTOPrsRelCltPedIO 1;
BA_ "SignalLongName" SG_ 3221225472 PTOPrsRelBrkPedIO "Power Take Off Press and state0800 Brake Pedal Indication On";
BA_ "SignalType" SG_ 3221225472 PTOPrsRelBrkPedIO "BLN";
BA_ "VNSigAllNodes" SG_ 3221225472 PTOPrsRelBrkPedIO 1;
BA_ "SignalLongName" SG_ 3221225472 PTOEngmntStatInd "Power Take Off Engagement Status Indication";
BA_ "SignalType" SG_ 3221225472 PTOEngmntStatInd "ENM";
BA_ "VNSigAllNodes" SG_ 3221225472 PTOEngmntStatInd 1;
BA_ "SignalLongName" SG_ 3221225472 PTODisengCrsCntlIO "Power Take Off Disengage Cruise Control Indication On";
BA_ "SignalType" SG_ 3221225472 PTODisengCrsCntlIO "BLN";
BA_ "VNSigAllNodes" SG_ 3221225472 PTODisengCrsCntlIO 1;
BA_ "SignalLongName" SG_ 3221225472 PTOMobModTrnsInGrIO "Power Take Off Mobile Mode Transmission In Gear Indication On";
BA_ "SignalType" SG_ 3221225472 PTOMobModTrnsInGrIO "BLN";
BA_ "VNSigAllNodes" SG_ 3221225472 PTOMobModTrnsInGrIO 1;
BA_ "GenSigSendType" SG_ 3221225472 PTOMobModTrnsInGrIO 10;
BA_ "SignalLongName" SG_ 3221225472 ActVbnCtrlMlfIO "Active Vibration Control Malfunction Indication On";
BA_ "SignalType" SG_ 3221225472 ActVbnCtrlMlfIO "BLN";
BA_ "VNSigAllNodes" SG_ 3221225472 ActVbnCtrlMlfIO 1;
BA_ "SignalLongName" SG_ 3221225472 SrvSuspSysIO "Service Suspension System Indication On";
BA_ "SignalType" SG_ 3221225472 SrvSuspSysIO "BLN";
BA_ "VNSigAllNodes" SG_ 3221225472 SrvSuspSysIO 1;
BA_ "SignalLongName" SG_ 3221225472 DCCnvStblznErrIO "DC Converter Stabilization Error Indication On";
BA_ "SignalType" SG_ 3221225472 DCCnvStblznErrIO "BLN";
BA_ "VNSigAllNodes" SG_ 3221225472 DCCnvStblznErrIO 1;
BA_ "SignalLongName" SG_ 558 CDSP_CmpDgrdOp "Compressor Device State Packet : Compressor Degraded Operation";
BA_ "PacketOrder" SG_ 558 CDSP_CmpDgrdOp 14;
BA_ "SignalType" SG_ 558 CDSP_CmpDgrdOp "BLN";
BA_ "VNSigAllNodes" SG_ 558 CDSP_CmpDgrdOp 1;
BA_ "SignalLongName" SG_ 558 CDSP_CmpIntShdwnFltSt "Compressor Device State Packet : Compressor Internal Shutdown Fault State";
BA_ "PacketOrder" SG_ 558 CDSP_CmpIntShdwnFltSt 13;
BA_ "SignalType" SG_ 558 CDSP_CmpIntShdwnFltSt "ENM";
BA_ "VNSigAllNodes" SG_ 558 CDSP_CmpIntShdwnFltSt 1;
BA_ "SignalLongName" SG_ 558 CDSP_CmpIntRecblFltSt "Compressor Device State Packet : Compressor Internal Recoverable Fault State";
BA_ "PacketOrder" SG_ 558 CDSP_CmpIntRecblFltSt 12;
BA_ "SignalType" SG_ 558 CDSP_CmpIntRecblFltSt "ENM";
BA_ "VNSigAllNodes" SG_ 558 CDSP_CmpIntRecblFltSt 1;
BA_ "SignalLongName" SG_ 558 CDSP_CmpOpOvrldSt "Compressor Device State Packet : Compressor Output Overload State";
BA_ "PacketOrder" SG_ 558 CDSP_CmpOpOvrldSt 11;
BA_ "SignalType" SG_ 558 CDSP_CmpOpOvrldSt "ENM";
BA_ "VNSigAllNodes" SG_ 558 CDSP_CmpOpOvrldSt 1;
BA_ "SignalLongName" SG_ 558 CDSP_CmpDrCrctFltSt "Compressor Device State Packet : Compressor Drive Circuit Fault State";
BA_ "PacketOrder" SG_ 558 CDSP_CmpDrCrctFltSt 10;
BA_ "SignalType" SG_ 558 CDSP_CmpDrCrctFltSt "ENM";
BA_ "VNSigAllNodes" SG_ 558 CDSP_CmpDrCrctFltSt 1;
BA_ "SignalLongName" SG_ 558 CDSP_CmpMtrPerfFltSt "Compressor Device State Packet : Compressor Motor Performance Fault State";
BA_ "PacketOrder" SG_ 558 CDSP_CmpMtrPerfFltSt 9;
BA_ "SignalType" SG_ 558 CDSP_CmpMtrPerfFltSt "ENM";
BA_ "VNSigAllNodes" SG_ 558 CDSP_CmpMtrPerfFltSt 1;
BA_ "SignalLongName" SG_ 558 CDSP_CmpEEPROMFltSt "Compressor Device State Packet : Compressor Electrically Erasable Programmable Read-Only Memory Fault State";
BA_ "PacketOrder" SG_ 558 CDSP_CmpEEPROMFltSt 8;
BA_ "SignalType" SG_ 558 CDSP_CmpEEPROMFltSt "ENM";
BA_ "VNSigAllNodes" SG_ 558 CDSP_CmpEEPROMFltSt 1;
BA_ "SignalLongName" SG_ 558 CDSP_CmpROMFltSt "Compressor Device State Packet : Compressor Read Only Memory Fault State";
BA_ "PacketOrder" SG_ 558 CDSP_CmpROMFltSt 7;
BA_ "SignalType" SG_ 558 CDSP_CmpROMFltSt "ENM";
BA_ "VNSigAllNodes" SG_ 558 CDSP_CmpROMFltSt 1;
BA_ "SignalLongName" SG_ 558 CDSP_CmpRAMFltSt "Compressor Device State Packet : Compressor Random Access Memory Fault State";
BA_ "PacketOrder" SG_ 558 CDSP_CmpRAMFltSt 6;
BA_ "SignalType" SG_ 558 CDSP_CmpRAMFltSt "ENM";
BA_ "VNSigAllNodes" SG_ 558 CDSP_CmpRAMFltSt 1;
BA_ "SignalLongName" SG_ 558 CmpSnsrStPktARC "Compressor Sensor State Packet Alive Rolling Count";
BA_ "SignalType" SG_ 558 CmpSnsrStPktARC "UNM";
BA_ "VNSigAllNodes" SG_ 558 CmpSnsrStPktARC 1;
BA_ "SignalLongName" SG_ 558 CSSP_CmpIGBTTpOtRgLSt "Compressor Sensor State Packet : Compressor Insulated Gate Bipolar Transistor Temperature Out of Range Low State";
BA_ "PacketOrder" SG_ 558 CSSP_CmpIGBTTpOtRgLSt 8;
BA_ "SignalType" SG_ 558 CSSP_CmpIGBTTpOtRgLSt "ENM";
BA_ "VNSigAllNodes" SG_ 558 CSSP_CmpIGBTTpOtRgLSt 1;
BA_ "SignalLongName" SG_ 558 CSSP_CmpIGBTTpOtRgHSt "Compressor Sensor State Packet : Compressor Insulated Gate Bipolar Transistor Temperature Out of Range High State";
BA_ "PacketOrder" SG_ 558 CSSP_CmpIGBTTpOtRgHSt 7;
BA_ "SignalType" SG_ 558 CSSP_CmpIGBTTpOtRgHSt "ENM";
BA_ "VNSigAllNodes" SG_ 558 CSSP_CmpIGBTTpOtRgHSt 1;
BA_ "SignalLongName" SG_ 558 CSSP_CmpCPUTmpOtRgLSt "Compressor Sensor State Packet : Compressor Central Processing Unit Temperature Out of Range Low State";
BA_ "PacketOrder" SG_ 558 CSSP_CmpCPUTmpOtRgLSt 6;
BA_ "SignalType" SG_ 558 CSSP_CmpCPUTmpOtRgLSt "ENM";
BA_ "VNSigAllNodes" SG_ 558 CSSP_CmpCPUTmpOtRgLSt 1;
BA_ "SignalLongName" SG_ 558 CSSP_CmpCPUTmpOtRgHSt "Compressor Sensor State Packet : Compressor Central Processing Unit Temperature Out of Range High State";
BA_ "PacketOrder" SG_ 558 CSSP_CmpCPUTmpOtRgHSt 5;
BA_ "SignalType" SG_ 558 CSSP_CmpCPUTmpOtRgHSt "ENM";
BA_ "VNSigAllNodes" SG_ 558 CSSP_CmpCPUTmpOtRgHSt 1;
BA_ "SignalLongName" SG_ 558 CSSP_CmpHVSnsOtRgLSt "Compressor Sensor State Packet : Compressor High Voltage Sensor Out of Range Low State";
BA_ "PacketOrder" SG_ 558 CSSP_CmpHVSnsOtRgLSt 4;
BA_ "SignalType" SG_ 558 CSSP_CmpHVSnsOtRgLSt "ENM";
BA_ "VNSigAllNodes" SG_ 558 CSSP_CmpHVSnsOtRgLSt 1;
BA_ "SignalLongName" SG_ 558 CSSP_CmpHVSnsOtRgHSt "Compressor Sensor State Packet : Compressor High Voltage Sensor Out of Range High State";
BA_ "PacketOrder" SG_ 558 CSSP_CmpHVSnsOtRgHSt 3;
BA_ "SignalType" SG_ 558 CSSP_CmpHVSnsOtRgHSt "ENM";
BA_ "VNSigAllNodes" SG_ 558 CSSP_CmpHVSnsOtRgHSt 1;
BA_ "SignalLongName" SG_ 558 CSSP_CmpPhCrntOtRgLSt "Compressor Sensor State Packet : Compressor Phase Current Out of Range Low State";
BA_ "PacketOrder" SG_ 558 CSSP_CmpPhCrntOtRgLSt 2;
BA_ "SignalType" SG_ 558 CSSP_CmpPhCrntOtRgLSt "ENM";
BA_ "VNSigAllNodes" SG_ 558 CSSP_CmpPhCrntOtRgLSt 1;
BA_ "SignalLongName" SG_ 558 CSSP_CmpPhCrntOtRgHSt "Compressor Sensor State Packet : Compressor Phase Current Out of Range High State";
BA_ "PacketOrder" SG_ 558 CSSP_CmpPhCrntOtRgHSt 1;
BA_ "SignalType" SG_ 558 CSSP_CmpPhCrntOtRgHSt "ENM";
BA_ "VNSigAllNodes" SG_ 558 CSSP_CmpPhCrntOtRgHSt 1;
BA_ "SignalLongName" SG_ 558 CmpDataPktARC "Compressor Data Paket Alive Rolling Count";
BA_ "SignalType" SG_ 558 CmpDataPktARC "UNM";
BA_ "VNSigAllNodes" SG_ 558 CmpDataPktARC 1;
BA_ "SignalLongName" SG_ 558 CDP_HVDevShtdnCdARCSt "Compressor Data Packet : High Voltage Device Shutdown Commanded Alive Rolling Count State";
BA_ "PacketOrder" SG_ 558 CDP_HVDevShtdnCdARCSt 5;
BA_ "SignalType" SG_ 558 CDP_HVDevShtdnCdARCSt "ENM";
BA_ "VNSigAllNodes" SG_ 558 CDP_HVDevShtdnCdARCSt 1;
BA_ "SignalLongName" SG_ 558 CDP_CmpSpdReqARCSt "Compressor Data Packet : Compressor Speed Request Alive Rolling Count State";
BA_ "PacketOrder" SG_ 558 CDP_CmpSpdReqARCSt 4;
BA_ "SignalType" SG_ 558 CDP_CmpSpdReqARCSt "ENM";
BA_ "VNSigAllNodes" SG_ 558 CDP_CmpSpdReqARCSt 1;
BA_ "SignalLongName" SG_ 558 CDP_CmpLossCommOcc "Compressor Data Packet : Compressor Loss of Communication Occurred";
BA_ "PacketOrder" SG_ 558 CDP_CmpLossCommOcc 3;
BA_ "SignalType" SG_ 558 CDP_CmpLossCommOcc "BLN";
BA_ "VNSigAllNodes" SG_ 558 CDP_CmpLossCommOcc 1;
BA_ "SignalLongName" SG_ 558 CDP_CmpWkUp "Compressor Data Packet : Compressor Wake up";
BA_ "PacketOrder" SG_ 558 CDP_CmpWkUp 2;
BA_ "SignalType" SG_ 558 CDP_CmpWkUp "BLN";
BA_ "VNSigAllNodes" SG_ 558 CDP_CmpWkUp 1;
BA_ "SignalLongName" SG_ 558 CDP_CmpRunCrnk "Compressor Data Packet : Compressor Run Crank";
BA_ "PacketOrder" SG_ 558 CDP_CmpRunCrnk 1;
BA_ "SignalType" SG_ 558 CDP_CmpRunCrnk "BLN";
BA_ "VNSigAllNodes" SG_ 558 CDP_CmpRunCrnk 1;
BA_ "SignalLongName" SG_ 558 CmpSnsrDevStPktARC "Compressor Device State Packet Alive Rolling Count";
BA_ "SignalType" SG_ 558 CmpSnsrDevStPktARC "UNM";
BA_ "VNSigAllNodes" SG_ 558 CmpSnsrDevStPktARC 1;
BA_ "SignalLongName" SG_ 558 CDSP_CmpOvrTmpSt "Compressor Device State Packet : Compressor Over Temperature State";
BA_ "PacketOrder" SG_ 558 CDSP_CmpOvrTmpSt 5;
BA_ "SignalType" SG_ 558 CDSP_CmpOvrTmpSt "ENM";
BA_ "VNSigAllNodes" SG_ 558 CDSP_CmpOvrTmpSt 1;
BA_ "SignalLongName" SG_ 558 CDSP_CmpHVAbnrlOrVltSt "Compressor Device State Packet : Compressor High Voltage Abnormal Over Voltage State";
BA_ "PacketOrder" SG_ 558 CDSP_CmpHVAbnrlOrVltSt 4;
BA_ "SignalType" SG_ 558 CDSP_CmpHVAbnrlOrVltSt "ENM";
BA_ "VNSigAllNodes" SG_ 558 CDSP_CmpHVAbnrlOrVltSt 1;
BA_ "SignalLongName" SG_ 558 CDSP_CmpHVUndrVltgSt "Compressor Device State Packet : Compressor High Voltage Under Voltage State";
BA_ "PacketOrder" SG_ 558 CDSP_CmpHVUndrVltgSt 3;
BA_ "SignalType" SG_ 558 CDSP_CmpHVUndrVltgSt "ENM";
BA_ "VNSigAllNodes" SG_ 558 CDSP_CmpHVUndrVltgSt 1;
BA_ "SignalLongName" SG_ 558 CDSP_CmpHVOvrVltgSt "Compressor Device State Packet : Compressor High Voltage Over Voltage State";
BA_ "PacketOrder" SG_ 558 CDSP_CmpHVOvrVltgSt 2;
BA_ "SignalType" SG_ 558 CDSP_CmpHVOvrVltgSt "ENM";
BA_ "VNSigAllNodes" SG_ 558 CDSP_CmpHVOvrVltgSt 1;
BA_ "SignalLongName" SG_ 558 CDSP_CmpHVOvrCrntSt "Compressor Device State Packet : Compressor High Voltage Over Current State";
BA_ "PacketOrder" SG_ 558 CDSP_CmpHVOvrCrntSt 1;
BA_ "SignalType" SG_ 558 CDSP_CmpHVOvrCrntSt "ENM";
BA_ "VNSigAllNodes" SG_ 558 CDSP_CmpHVOvrCrntSt 1;
BA_ "SignalLongName" SG_ 558 CDSP_OvrTempWrnInd "Compressor Device State Packet : Over Temperature Warning Indication";
BA_ "PacketOrder" SG_ 558 CDSP_OvrTempWrnInd 15;
BA_ "SignalType" SG_ 558 CDSP_OvrTempWrnInd "BLN";
BA_ "VNSigAllNodes" SG_ 558 CDSP_OvrTempWrnInd 1;
BA_ "SignalLongName" SG_ 550 ACCMCII_DtBtG "Air Compressor Control Module Calibration Identification : Data Byte G";
BA_ "PacketOrder" SG_ 550 ACCMCII_DtBtG 10;
BA_ "SignalType" SG_ 550 ACCMCII_DtBtG "ASC";
BA_ "VNSigAllNodes" SG_ 550 ACCMCII_DtBtG 1;
BA_ "SignalLongName" SG_ 550 ACCMCII_DtBtF "Air Compressor Control Module Calibration Identification : Data Byte F";
BA_ "PacketOrder" SG_ 550 ACCMCII_DtBtF 9;
BA_ "SignalType" SG_ 550 ACCMCII_DtBtF "ASC";
BA_ "VNSigAllNodes" SG_ 550 ACCMCII_DtBtF 1;
BA_ "SignalLongName" SG_ 550 ACCMCII_DtBtE "Air Compressor Control Module Calibration Identification : Data Byte E";
BA_ "PacketOrder" SG_ 550 ACCMCII_DtBtE 8;
BA_ "SignalType" SG_ 550 ACCMCII_DtBtE "ASC";
BA_ "VNSigAllNodes" SG_ 550 ACCMCII_DtBtE 1;
BA_ "SignalLongName" SG_ 550 ACCMCII_DtBtD "Air Compressor Control Module Calibration Identification : Data Byte D";
BA_ "PacketOrder" SG_ 550 ACCMCII_DtBtD 7;
BA_ "SignalType" SG_ 550 ACCMCII_DtBtD "ASC";
BA_ "VNSigAllNodes" SG_ 550 ACCMCII_DtBtD 1;
BA_ "SignalLongName" SG_ 550 ACCMCII_DtBtC "Air Compressor Control Module Calibration Identification : Data Byte C";
BA_ "PacketOrder" SG_ 550 ACCMCII_DtBtC 6;
BA_ "SignalType" SG_ 550 ACCMCII_DtBtC "ASC";
BA_ "VNSigAllNodes" SG_ 550 ACCMCII_DtBtC 1;
BA_ "SignalLongName" SG_ 550 ACCMCII_DtBtB "Air Compressor Control Module Calibration Identification : Data Byte B";
BA_ "PacketOrder" SG_ 550 ACCMCII_DtBtB 5;
BA_ "SignalType" SG_ 550 ACCMCII_DtBtB "ASC";
BA_ "VNSigAllNodes" SG_ 550 ACCMCII_DtBtB 1;
BA_ "SignalLongName" SG_ 550 ACCMCII_DtBtA "Air Compressor Control Module Calibration Identification : Data Byte A";
BA_ "PacketOrder" SG_ 550 ACCMCII_DtBtA 4;
BA_ "SignalType" SG_ 550 ACCMCII_DtBtA "ASC";
BA_ "VNSigAllNodes" SG_ 550 ACCMCII_DtBtA 1;
BA_ "SignalLongName" SG_ 550 ACCMCII_SeqNum "Air Compressor Control Module Calibration Identification : Sequence Number";
BA_ "PacketOrder" SG_ 550 ACCMCII_SeqNum 3;
BA_ "SignalType" SG_ 550 ACCMCII_SeqNum "UNM";
BA_ "VNSigAllNodes" SG_ 550 ACCMCII_SeqNum 1;
BA_ "SignalLongName" SG_ 550 ACCMCII_Index "Air Compressor Control Module Calibration Identification : Index";
BA_ "PacketOrder" SG_ 550 ACCMCII_Index 1;
BA_ "SignalType" SG_ 550 ACCMCII_Index "UNM";
BA_ "VNSigAllNodes" SG_ 550 ACCMCII_Index 1;
BA_ "SignalLongName" SG_ 550 ACCMCII_DatStat "Air Compressor Control Module Calibration Identification : Data Status";
BA_ "PacketOrder" SG_ 550 ACCMCII_DatStat 2;
BA_ "SignalType" SG_ 550 ACCMCII_DatStat "ENM";
BA_ "VNSigAllNodes" SG_ 550 ACCMCII_DatStat 1;
BA_ "SignalLongName" SG_ 546 ThrmlRefCmpIGBTTmp "Thermal Refrigerant Compressor Insulated Gate Bipolar Transistor Temperature";
BA_ "SignalType" SG_ 546 ThrmlRefCmpIGBTTmp "UNM";
BA_ "VNSigAllNodes" SG_ 546 ThrmlRefCmpIGBTTmp 1;
BA_ "SignalLongName" SG_ 546 CmpSnsrDataARC "Compressor Sensor Data Alive Rolling Count";
BA_ "SignalType" SG_ 546 CmpSnsrDataARC "UNM";
BA_ "VNSigAllNodes" SG_ 546 CmpSnsrDataARC 1;
BA_ "SignalLongName" SG_ 546 ThrmlRefCmpCPUHtSkTmp "Thermal Refrigerant Compressor Central Processing Unit Heat Sink Temperature";
BA_ "SignalType" SG_ 546 ThrmlRefCmpCPUHtSkTmp "UNM";
BA_ "VNSigAllNodes" SG_ 546 ThrmlRefCmpCPUHtSkTmp 1;
BA_ "SignalLongName" SG_ 546 ThrmlRefCmpHVInHRsln "Thermal Refrigerant Compressor High Voltage Input High Resolution";
BA_ "SignalType" SG_ 546 ThrmlRefCmpHVInHRsln "UNM";
BA_ "VNSigAllNodes" SG_ 546 ThrmlRefCmpHVInHRsln 1;
BA_ "SignalLongName" SG_ 546 ThrmlRfCmprElctrCrnt "Thermal Refrigerant Compressor Electrical Current";
BA_ "SignalType" SG_ 546 ThrmlRfCmprElctrCrnt "UNM";
BA_ "VNSigAllNodes" SG_ 546 ThrmlRfCmprElctrCrnt 1;
BA_ "SignalLongName" SG_ 546 ThrmlRefCompSpdFdbck "Thermal Refrigerant Compressor Speed Feedback";
BA_ "SignalType" SG_ 546 ThrmlRefCompSpdFdbck "UNM";
BA_ "VNSigAllNodes" SG_ 546 ThrmlRefCompSpdFdbck 1;
BA_ "SignalLongName" SG_ 546 ThrmlRefCompStatFdbck "Thermal Refrigerant Compressor Status Feedback";
BA_ "SignalType" SG_ 546 ThrmlRefCompStatFdbck "ENM";
BA_ "VNSigAllNodes" SG_ 546 ThrmlRefCompStatFdbck 1;
BA_ "SignalLongName" SG_ 289 Sig0936 "Signal0936";
BA_ "PacketOrder" SG_ 289 Sig0936 2;
BA_ "SignalType" SG_ 289 Sig0936 "UNM";
BA_ "VNSigAllNodes" SG_ 289 Sig0936 1;
BA_ "SignalLongName" SG_ 289 Sig0935 "Signal0935";
BA_ "PacketOrder" SG_ 289 Sig0935 1;
BA_ "SignalType" SG_ 289 Sig0935 "ENM";
BA_ "VNSigAllNodes" SG_ 289 Sig0935 1;
BA_ "SignalLongName" SG_ 861 DgnInf "Diagnostic Information";
BA_ "SignalType" SG_ 861 DgnInf "UNM";
BA_ "VNSigAllNodes" SG_ 861 DgnInf 1;
BA_ "VNSigSLHSSharedDiagnostic" SG_ 861 DgnInf 1;
BA_ "SignalLongName" SG_ 594 DgnInf "Diagnostic Information";
BA_ "SignalType" SG_ 594 DgnInf "UNM";
BA_ "VNSigAllNodes" SG_ 594 DgnInf 1;
BA_ "VNSigSLHSSharedDiagnostic" SG_ 594 DgnInf 1;
BA_ "SignalLongName" SG_ 593 DgnInf "Diagnostic Information";
BA_ "SignalType" SG_ 593 DgnInf "UNM";
BA_ "VNSigAllNodes" SG_ 593 DgnInf 1;
BA_ "VNSigSLHSSharedDiagnostic" SG_ 593 DgnInf 1;
BA_ "SignalLongName" SG_ 597 DgnInf "Diagnostic Information";
BA_ "SignalType" SG_ 597 DgnInf "UNM";
BA_ "VNSigAllNodes" SG_ 597 DgnInf 1;
BA_ "VNSigSLHSSharedDiagnostic" SG_ 597 DgnInf 1;
BA_ "SignalLongName" SG_ 592 DgnInf "Diagnostic Information";
BA_ "SignalType" SG_ 592 DgnInf "UNM";
BA_ "VNSigAllNodes" SG_ 592 DgnInf 1;
BA_ "VNSigSLHSSharedDiagnostic" SG_ 592 DgnInf 1;
BA_ "SignalLongName" SG_ 589 DgnInf "Diagnostic Information";
BA_ "SignalType" SG_ 589 DgnInf "UNM";
BA_ "VNSigAllNodes" SG_ 589 DgnInf 1;
BA_ "VNSigSLHSSharedDiagnostic" SG_ 589 DgnInf 1;
BA_ "SignalLongName" SG_ 582 DgnInf "Diagnostic Information";
BA_ "SignalType" SG_ 582 DgnInf "UNM";
BA_ "VNSigAllNodes" SG_ 582 DgnInf 1;
BA_ "VNSigSLHSSharedDiagnostic" SG_ 582 DgnInf 1;
BA_ "SignalLongName" SG_ 601 DgnInf "Diagnostic Information";
BA_ "SignalType" SG_ 601 DgnInf "UNM";
BA_ "VNSigAllNodes" SG_ 601 DgnInf 1;
BA_ "VNSigSLHSSharedDiagnostic" SG_ 601 DgnInf 1;
BA_ "SignalLongName" SG_ 2023 DgnInf "Diagnostic Information";
BA_ "SignalType" SG_ 2023 DgnInf "UNM";
BA_ "VNSigAllNodes" SG_ 2023 DgnInf 1;
BA_ "VNSigSLHSSharedDiagnostic" SG_ 2023 DgnInf 1;
BA_ "SignalLongName" SG_ 2021 DgnInf "Diagnostic Information";
BA_ "SignalType" SG_ 2021 DgnInf "UNM";
BA_ "VNSigAllNodes" SG_ 2021 DgnInf 1;
BA_ "VNSigSLHSSharedDiagnostic" SG_ 2021 DgnInf 1;
BA_ "SignalLongName" SG_ 2019 DgnInf "Diagnostic Information";
BA_ "SignalType" SG_ 2019 DgnInf "UNM";
BA_ "VNSigAllNodes" SG_ 2019 DgnInf 1;
BA_ "VNSigSLHSSharedDiagnostic" SG_ 2019 DgnInf 1;
BA_ "SignalLongName" SG_ 578 DgnInf "Diagnostic Information";
BA_ "SignalType" SG_ 578 DgnInf "UNM";
BA_ "VNSigAllNodes" SG_ 578 DgnInf 1;
BA_ "VNSigSLHSSharedDiagnostic" SG_ 578 DgnInf 1;
BA_ "SignalLongName" SG_ 2022 DgnInf "Diagnostic Information";
BA_ "SignalType" SG_ 2022 DgnInf "UNM";
BA_ "VNSigAllNodes" SG_ 2022 DgnInf 1;
BA_ "VNSigSLHSSharedDiagnostic" SG_ 2022 DgnInf 1;
BA_ "SignalLongName" SG_ 584 DgnInf "Diagnostic Information";
BA_ "SignalType" SG_ 584 DgnInf "UNM";
BA_ "VNSigAllNodes" SG_ 584 DgnInf 1;
BA_ "VNSigSLHSSharedDiagnostic" SG_ 584 DgnInf 1;
BA_ "SignalLongName" SG_ 586 DgnInf "Diagnostic Information";
BA_ "SignalType" SG_ 586 DgnInf "UNM";
BA_ "VNSigAllNodes" SG_ 586 DgnInf 1;
BA_ "VNSigSLHSSharedDiagnostic" SG_ 586 DgnInf 1;
BA_ "SignalLongName" SG_ 588 DgnInf "Diagnostic Information";
BA_ "SignalType" SG_ 588 DgnInf "UNM";
BA_ "VNSigAllNodes" SG_ 588 DgnInf 1;
BA_ "VNSigSLHSSharedDiagnostic" SG_ 588 DgnInf 1;
BA_ "SignalLongName" SG_ 580 DgnInf "Diagnostic Information";
BA_ "SignalType" SG_ 580 DgnInf "UNM";
BA_ "VNSigAllNodes" SG_ 580 DgnInf 1;
BA_ "VNSigSLHSSharedDiagnostic" SG_ 580 DgnInf 1;
BA_ "SignalLongName" SG_ 2020 DgnInf "Diagnostic Information";
BA_ "SignalType" SG_ 2020 DgnInf "UNM";
BA_ "VNSigAllNodes" SG_ 2020 DgnInf 1;
BA_ "VNSigSLHSSharedDiagnostic" SG_ 2020 DgnInf 1;
BA_ "SignalLongName" SG_ 599 DgnInf "Diagnostic Information";
BA_ "SignalType" SG_ 599 DgnInf "UNM";
BA_ "VNSigAllNodes" SG_ 599 DgnInf 1;
BA_ "VNSigSLHSSharedDiagnostic" SG_ 599 DgnInf 1;
BA_ "SignalLongName" SG_ 2017 DgnInf "Diagnostic Information";
BA_ "SignalType" SG_ 2017 DgnInf "UNM";
BA_ "VNSigAllNodes" SG_ 2017 DgnInf 1;
BA_ "VNSigSLHSSharedDiagnostic" SG_ 2017 DgnInf 1;
BA_ "SignalLongName" SG_ 1910 DTCI_DTCFaultType_776 "Diagnostic Trouble Code Information Extended 776 : Diagnostic Trouble Code Fault Type";
BA_ "PacketOrder" SG_ 1910 DTCI_DTCFaultType_776 20;
BA_ "SignalType" SG_ 1910 DTCI_DTCFaultType_776 "ENM";
BA_ "VNSigAllNodes" SG_ 1910 DTCI_DTCFaultType_776 1;
BA_ "SignalLongName" SG_ 1910 DTCI_CodeSupported_776 "Diagnostic Trouble Code Information Extended 776 : Code Supported";
BA_ "PacketOrder" SG_ 1910 DTCI_CodeSupported_776 19;
BA_ "SignalType" SG_ 1910 DTCI_CodeSupported_776 "BLN";
BA_ "VNSigAllNodes" SG_ 1910 DTCI_CodeSupported_776 1;
BA_ "SignalLongName" SG_ 1910 DTCI_CurrentStatus_776 "Diagnostic Trouble Code Information Extended 776 : Current Status";
BA_ "PacketOrder" SG_ 1910 DTCI_CurrentStatus_776 18;
BA_ "SignalType" SG_ 1910 DTCI_CurrentStatus_776 "BLN";
BA_ "VNSigAllNodes" SG_ 1910 DTCI_CurrentStatus_776 1;
BA_ "SignalLongName" SG_ 1910 DTCI_TstNPsdCdClrdSt_776 "Diagnostic Trouble Code Information Extended 776 : Test Not Passed Since Code Cleared Status";
BA_ "PacketOrder" SG_ 1910 DTCI_TstNPsdCdClrdSt_776 17;
BA_ "SignalType" SG_ 1910 DTCI_TstNPsdCdClrdSt_776 "BLN";
BA_ "VNSigAllNodes" SG_ 1910 DTCI_TstNPsdCdClrdSt_776 1;
BA_ "SignalLongName" SG_ 1910 DTCI_TstFldCdClrdStat_776 "Diagnostic Trouble Code Information Extended 776 : Test Failed Since Code Cleared Status";
BA_ "PacketOrder" SG_ 1910 DTCI_TstFldCdClrdStat_776 16;
BA_ "SignalType" SG_ 1910 DTCI_TstFldCdClrdStat_776 "BLN";
BA_ "VNSigAllNodes" SG_ 1910 DTCI_TstFldCdClrdStat_776 1;
BA_ "SignalLongName" SG_ 1910 DTCI_HistStat_776 "Diagnostic Trouble Code Information Extended 776 : History Status";
BA_ "PacketOrder" SG_ 1910 DTCI_HistStat_776 15;
BA_ "SignalType" SG_ 1910 DTCI_HistStat_776 "BLN";
BA_ "VNSigAllNodes" SG_ 1910 DTCI_HistStat_776 1;
BA_ "SignalLongName" SG_ 1910 DTCI_TstNPsdPwrUpSt_776 "Diagnostic Trouble Code Information Extended 776 : Test Not Passed Since Power Up Status";
BA_ "PacketOrder" SG_ 1910 DTCI_TstNPsdPwrUpSt_776 14;
BA_ "SignalType" SG_ 1910 DTCI_TstNPsdPwrUpSt_776 "BLN";
BA_ "VNSigAllNodes" SG_ 1910 DTCI_TstNPsdPwrUpSt_776 1;
BA_ "SignalLongName" SG_ 1910 DTCI_TstFldPwrUpSt_776 "Diagnostic Trouble Code Information Extended 776 : Test Failed Since Power Up Status";
BA_ "PacketOrder" SG_ 1910 DTCI_TstFldPwrUpSt_776 13;
BA_ "SignalType" SG_ 1910 DTCI_TstFldPwrUpSt_776 "BLN";
BA_ "VNSigAllNodes" SG_ 1910 DTCI_TstFldPwrUpSt_776 1;
BA_ "SignalLongName" SG_ 1910 DTCI_WrnIndRqdSt_776 "Diagnostic Trouble Code Information Extended 776 : Warning Indicator Requested Status";
BA_ "PacketOrder" SG_ 1910 DTCI_WrnIndRqdSt_776 12;
BA_ "SignalType" SG_ 1910 DTCI_WrnIndRqdSt_776 "BLN";
BA_ "VNSigAllNodes" SG_ 1910 DTCI_WrnIndRqdSt_776 1;
BA_ "SignalLongName" SG_ 1910 DTCI_DTCFailType_776 "Diagnostic Trouble Code Information Extended 776 : Diagnostic Trouble Code Failure Type";
BA_ "PacketOrder" SG_ 1910 DTCI_DTCFailType_776 11;
BA_ "SignalType" SG_ 1910 DTCI_DTCFailType_776 "UNM";
BA_ "VNSigAllNodes" SG_ 1910 DTCI_DTCFailType_776 1;
BA_ "SignalLongName" SG_ 1910 DTCI_DTCNumber_776 "Diagnostic Trouble Code Information Extended 776 : Diagnostic Trouble Code Number";
BA_ "PacketOrder" SG_ 1910 DTCI_DTCNumber_776 10;
BA_ "SignalType" SG_ 1910 DTCI_DTCNumber_776 "UNM";
BA_ "VNSigAllNodes" SG_ 1910 DTCI_DTCNumber_776 1;
BA_ "SignalLongName" SG_ 1910 DTCI_DTCSource_776 "Diagnostic Trouble Code Information Extended 776 : Diagnostic Trouble Code Source";
BA_ "PacketOrder" SG_ 1910 DTCI_DTCSource_776 9;
BA_ "SignalType" SG_ 1910 DTCI_DTCSource_776 "UNM";
BA_ "VNSigAllNodes" SG_ 1910 DTCI_DTCSource_776 1;
BA_ "SignalLongName" SG_ 1910 DTCI_DTCTriggered_776 "Diagnostic Trouble Code Information Extended 776 : Diagnostic Trouble Code Triggered";
BA_ "PacketOrder" SG_ 1910 DTCI_DTCTriggered_776 8;
BA_ "SignalType" SG_ 1910 DTCI_DTCTriggered_776 "BLN";
BA_ "VNSigAllNodes" SG_ 1910 DTCI_DTCTriggered_776 1;
BA_ "SignalLongName" SG_ 1910 DTCIUnused7_776 "Diagnostic Trouble Code Information Extended 776 : Unused 7";
BA_ "PacketOrder" SG_ 1910 DTCIUnused7_776 7;
BA_ "SignalType" SG_ 1910 DTCIUnused7_776 "BLN";
BA_ "VNSigAllNodes" SG_ 1910 DTCIUnused7_776 1;
BA_ "SignalLongName" SG_ 1910 DTCIUnused6_776 "Diagnostic Trouble Code Information Extended 776 : Unused 6";
BA_ "PacketOrder" SG_ 1910 DTCIUnused6_776 6;
BA_ "SignalType" SG_ 1910 DTCIUnused6_776 "BLN";
BA_ "VNSigAllNodes" SG_ 1910 DTCIUnused6_776 1;
BA_ "SignalLongName" SG_ 1910 DTCIUnused5_776 "Diagnostic Trouble Code Information Extended 776 : Unused 5";
BA_ "PacketOrder" SG_ 1910 DTCIUnused5_776 5;
BA_ "SignalType" SG_ 1910 DTCIUnused5_776 "BLN";
BA_ "VNSigAllNodes" SG_ 1910 DTCIUnused5_776 1;
BA_ "SignalLongName" SG_ 1910 DTCIUnused4_776 "Diagnostic Trouble Code Information Extended 776 : Unused 4";
BA_ "PacketOrder" SG_ 1910 DTCIUnused4_776 4;
BA_ "SignalType" SG_ 1910 DTCIUnused4_776 "BLN";
BA_ "VNSigAllNodes" SG_ 1910 DTCIUnused4_776 1;
BA_ "SignalLongName" SG_ 1910 DTCIUnused3_776 "Diagnostic Trouble Code Information Extended 776 : Unused 3";
BA_ "PacketOrder" SG_ 1910 DTCIUnused3_776 3;
BA_ "SignalType" SG_ 1910 DTCIUnused3_776 "BLN";
BA_ "VNSigAllNodes" SG_ 1910 DTCIUnused3_776 1;
BA_ "SignalLongName" SG_ 1910 DTCIUnused2_776 "Diagnostic Trouble Code Information Extended 776 : Unused 2";
BA_ "PacketOrder" SG_ 1910 DTCIUnused2_776 2;
BA_ "SignalType" SG_ 1910 DTCIUnused2_776 "BLN";
BA_ "VNSigAllNodes" SG_ 1910 DTCIUnused2_776 1;
BA_ "SignalLongName" SG_ 1910 DTCIUnused1_776 "Diagnostic Trouble Code Information Extended 776 : Unused 1";
BA_ "PacketOrder" SG_ 1910 DTCIUnused1_776 1;
BA_ "SignalType" SG_ 1910 DTCIUnused1_776 "BLN";
BA_ "VNSigAllNodes" SG_ 1910 DTCIUnused1_776 1;
BA_ "SignalLongName" SG_ 2025 DgnInf "Diagnostic Information";
BA_ "SignalType" SG_ 2025 DgnInf "UNM";
BA_ "VNSigAllNodes" SG_ 2025 DgnInf 1;
BA_ "VNSigSLHSSharedDiagnostic" SG_ 2025 DgnInf 1;
BA_ "SignalLongName" SG_ 1513 DgnInf "Diagnostic Information";
BA_ "SignalType" SG_ 1513 DgnInf "UNM";
BA_ "VNSigAllNodes" SG_ 1513 DgnInf 1;
BA_ "VNSigSLHSSharedDiagnostic" SG_ 1513 DgnInf 1;
BA_ "SignalLongName" SG_ 581 DgnInf "Diagnostic Information";
BA_ "SignalType" SG_ 581 DgnInf "UNM";
BA_ "VNSigAllNodes" SG_ 581 DgnInf 1;
BA_ "VNSigSLHSSharedDiagnostic" SG_ 581 DgnInf 1;
BA_ "SignalLongName" SG_ 585 DgnInf "Diagnostic Information";
BA_ "SignalType" SG_ 585 DgnInf "UNM";
BA_ "VNSigAllNodes" SG_ 585 DgnInf 1;
BA_ "VNSigSLHSSharedDiagnostic" SG_ 585 DgnInf 1;
BA_ "SignalLongName" SG_ 1916 DTCI_DTCFaultType_77C "Diagnostic Trouble Code Information Extended 77C : Diagnostic Trouble Code Fault Type";
BA_ "PacketOrder" SG_ 1916 DTCI_DTCFaultType_77C 20;
BA_ "SignalType" SG_ 1916 DTCI_DTCFaultType_77C "ENM";
BA_ "VNSigAllNodes" SG_ 1916 DTCI_DTCFaultType_77C 1;
BA_ "SignalLongName" SG_ 1916 DTCI_CodeSupported_77C "Diagnostic Trouble Code Information Extended 77C : Code Supported";
BA_ "PacketOrder" SG_ 1916 DTCI_CodeSupported_77C 19;
BA_ "SignalType" SG_ 1916 DTCI_CodeSupported_77C "BLN";
BA_ "VNSigAllNodes" SG_ 1916 DTCI_CodeSupported_77C 1;
BA_ "SignalLongName" SG_ 1916 DTCI_CurrentStatus_77C "Diagnostic Trouble Code Information Extended 77C : Current Status";
BA_ "PacketOrder" SG_ 1916 DTCI_CurrentStatus_77C 18;
BA_ "SignalType" SG_ 1916 DTCI_CurrentStatus_77C "BLN";
BA_ "VNSigAllNodes" SG_ 1916 DTCI_CurrentStatus_77C 1;
BA_ "SignalLongName" SG_ 1916 DTCI_TstNPsdCdClrdSt_77C "Diagnostic Trouble Code Information Extended 77C : Test Not Passed Since Code Cleared Status";
BA_ "PacketOrder" SG_ 1916 DTCI_TstNPsdCdClrdSt_77C 17;
BA_ "SignalType" SG_ 1916 DTCI_TstNPsdCdClrdSt_77C "BLN";
BA_ "VNSigAllNodes" SG_ 1916 DTCI_TstNPsdCdClrdSt_77C 1;
BA_ "SignalLongName" SG_ 1916 DTCI_TstFldCdClrdStat_77C "Diagnostic Trouble Code Information Extended 77C : Test Failed Since Code Cleared Status";
BA_ "PacketOrder" SG_ 1916 DTCI_TstFldCdClrdStat_77C 16;
BA_ "SignalType" SG_ 1916 DTCI_TstFldCdClrdStat_77C "BLN";
BA_ "VNSigAllNodes" SG_ 1916 DTCI_TstFldCdClrdStat_77C 1;
BA_ "SignalLongName" SG_ 1916 DTCI_HistStat_77C "Diagnostic Trouble Code Information Extended 77C : History Status";
BA_ "PacketOrder" SG_ 1916 DTCI_HistStat_77C 15;
BA_ "SignalType" SG_ 1916 DTCI_HistStat_77C "BLN";
BA_ "VNSigAllNodes" SG_ 1916 DTCI_HistStat_77C 1;
BA_ "SignalLongName" SG_ 1916 DTCI_TstNPsdPwrUpSt_77C "Diagnostic Trouble Code Information Extended 77C : Test Not Passed Since Power Up Status";
BA_ "PacketOrder" SG_ 1916 DTCI_TstNPsdPwrUpSt_77C 14;
BA_ "SignalType" SG_ 1916 DTCI_TstNPsdPwrUpSt_77C "BLN";
BA_ "VNSigAllNodes" SG_ 1916 DTCI_TstNPsdPwrUpSt_77C 1;
BA_ "SignalLongName" SG_ 1916 DTCI_TstFldPwrUpSt_77C "Diagnostic Trouble Code Information Extended 77C : Test Failed Since Power Up Status";
BA_ "PacketOrder" SG_ 1916 DTCI_TstFldPwrUpSt_77C 13;
BA_ "SignalType" SG_ 1916 DTCI_TstFldPwrUpSt_77C "BLN";
BA_ "VNSigAllNodes" SG_ 1916 DTCI_TstFldPwrUpSt_77C 1;
BA_ "SignalLongName" SG_ 1916 DTCI_WrnIndRqdSt_77C "Diagnostic Trouble Code Information Extended 77C : Warning Indicator Requested Status";
BA_ "PacketOrder" SG_ 1916 DTCI_WrnIndRqdSt_77C 12;
BA_ "SignalType" SG_ 1916 DTCI_WrnIndRqdSt_77C "BLN";
BA_ "VNSigAllNodes" SG_ 1916 DTCI_WrnIndRqdSt_77C 1;
BA_ "SignalLongName" SG_ 1916 DTCI_DTCFailType_77C "Diagnostic Trouble Code Information Extended 77C : Diagnostic Trouble Code Failure Type";
BA_ "PacketOrder" SG_ 1916 DTCI_DTCFailType_77C 11;
BA_ "SignalType" SG_ 1916 DTCI_DTCFailType_77C "UNM";
BA_ "VNSigAllNodes" SG_ 1916 DTCI_DTCFailType_77C 1;
BA_ "SignalLongName" SG_ 1916 DTCI_DTCNumber_77C "Diagnostic Trouble Code Information Extended 77C : Diagnostic Trouble Code Number";
BA_ "PacketOrder" SG_ 1916 DTCI_DTCNumber_77C 10;
BA_ "SignalType" SG_ 1916 DTCI_DTCNumber_77C "UNM";
BA_ "VNSigAllNodes" SG_ 1916 DTCI_DTCNumber_77C 1;
BA_ "SignalLongName" SG_ 1916 DTCI_DTCSource_77C "Diagnostic Trouble Code Information Extended 77C : Diagnostic Trouble Code Source";
BA_ "PacketOrder" SG_ 1916 DTCI_DTCSource_77C 9;
BA_ "SignalType" SG_ 1916 DTCI_DTCSource_77C "UNM";
BA_ "VNSigAllNodes" SG_ 1916 DTCI_DTCSource_77C 1;
BA_ "SignalLongName" SG_ 1916 DTCI_DTCTriggered_77C "Diagnostic Trouble Code Information Extended 77C : Diagnostic Trouble Code Triggered";
BA_ "PacketOrder" SG_ 1916 DTCI_DTCTriggered_77C 8;
BA_ "SignalType" SG_ 1916 DTCI_DTCTriggered_77C "BLN";
BA_ "VNSigAllNodes" SG_ 1916 DTCI_DTCTriggered_77C 1;
BA_ "SignalLongName" SG_ 1916 DTCIUnused7_77C "Diagnostic Trouble Code Information Extended 77C : Unused 7";
BA_ "PacketOrder" SG_ 1916 DTCIUnused7_77C 7;
BA_ "SignalType" SG_ 1916 DTCIUnused7_77C "BLN";
BA_ "VNSigAllNodes" SG_ 1916 DTCIUnused7_77C 1;
BA_ "SignalLongName" SG_ 1916 DTCIUnused6_77C "Diagnostic Trouble Code Information Extended 77C : Unused 6";
BA_ "PacketOrder" SG_ 1916 DTCIUnused6_77C 6;
BA_ "SignalType" SG_ 1916 DTCIUnused6_77C "BLN";
BA_ "VNSigAllNodes" SG_ 1916 DTCIUnused6_77C 1;
BA_ "SignalLongName" SG_ 1916 DTCIUnused5_77C "Diagnostic Trouble Code Information Extended 77C : Unused 5";
BA_ "PacketOrder" SG_ 1916 DTCIUnused5_77C 5;
BA_ "SignalType" SG_ 1916 DTCIUnused5_77C "BLN";
BA_ "VNSigAllNodes" SG_ 1916 DTCIUnused5_77C 1;
BA_ "SignalLongName" SG_ 1916 DTCIUnused4_77C "Diagnostic Trouble Code Information Extended 77C : Unused 4";
BA_ "PacketOrder" SG_ 1916 DTCIUnused4_77C 4;
BA_ "SignalType" SG_ 1916 DTCIUnused4_77C "BLN";
BA_ "VNSigAllNodes" SG_ 1916 DTCIUnused4_77C 1;
BA_ "SignalLongName" SG_ 1916 DTCIUnused3_77C "Diagnostic Trouble Code Information Extended 77C : Unused 3";
BA_ "PacketOrder" SG_ 1916 DTCIUnused3_77C 3;
BA_ "SignalType" SG_ 1916 DTCIUnused3_77C "BLN";
BA_ "VNSigAllNodes" SG_ 1916 DTCIUnused3_77C 1;
BA_ "SignalLongName" SG_ 1916 DTCIUnused2_77C "Diagnostic Trouble Code Information Extended 77C : Unused 2";
BA_ "PacketOrder" SG_ 1916 DTCIUnused2_77C 2;
BA_ "SignalType" SG_ 1916 DTCIUnused2_77C "BLN";
BA_ "VNSigAllNodes" SG_ 1916 DTCIUnused2_77C 1;
BA_ "SignalLongName" SG_ 1916 DTCIUnused1_77C "Diagnostic Trouble Code Information Extended 77C : Unused 1";
BA_ "PacketOrder" SG_ 1916 DTCIUnused1_77C 1;
BA_ "SignalType" SG_ 1916 DTCIUnused1_77C "BLN";
BA_ "VNSigAllNodes" SG_ 1916 DTCIUnused1_77C 1;
BA_ "SignalLongName" SG_ 1353 DgnInf_HS549 "Diagnostic Information HS549";
BA_ "SignalType" SG_ 1353 DgnInf_HS549 "UNM";
BA_ "VNSigAllNodes" SG_ 1353 DgnInf_HS549 1;
BA_ "VNSigSLHSSharedDiagnostic" SG_ 1353 DgnInf_HS549 1;
BA_ "SignalLongName" SG_ 1609 DgnInf "Diagnostic Information";
BA_ "SignalType" SG_ 1609 DgnInf "UNM";
BA_ "VNSigAllNodes" SG_ 1609 DgnInf 1;
BA_ "VNSigSLHSSharedDiagnostic" SG_ 1609 DgnInf 1;
BA_ "SignalLongName" SG_ 590 DgnInf "Diagnostic Information";
BA_ "SignalType" SG_ 590 DgnInf "UNM";
BA_ "VNSigAllNodes" SG_ 590 DgnInf 1;
BA_ "VNSigSLHSSharedDiagnostic" SG_ 590 DgnInf 1;
BA_ "SignalLongName" SG_ 596 DgnInf "Diagnostic Information";
BA_ "SignalType" SG_ 596 DgnInf "UNM";
BA_ "VNSigAllNodes" SG_ 596 DgnInf 1;
BA_ "VNSigSLHSSharedDiagnostic" SG_ 596 DgnInf 1;
BA_ "SignalLongName" SG_ 1364 DgnInf_HS554 "Diagnostic Information HS554";
BA_ "SignalType" SG_ 1364 DgnInf_HS554 "UNM";
BA_ "VNSigAllNodes" SG_ 1364 DgnInf_HS554 1;
BA_ "VNSigSLHSSharedDiagnostic" SG_ 1364 DgnInf_HS554 1;
BA_ "SignalLongName" SG_ 1917 DTCI_DTCFaultType_77D "Diagnostic Trouble Code Information Extended 77D : Diagnostic Trouble Code Fault Type";
BA_ "PacketOrder" SG_ 1917 DTCI_DTCFaultType_77D 20;
BA_ "SignalType" SG_ 1917 DTCI_DTCFaultType_77D "ENM";
BA_ "VNSigAllNodes" SG_ 1917 DTCI_DTCFaultType_77D 1;
BA_ "SignalLongName" SG_ 1917 DTCI_CodeSupported_77D "Diagnostic Trouble Code Information Extended 77D : Code Supported";
BA_ "PacketOrder" SG_ 1917 DTCI_CodeSupported_77D 19;
BA_ "SignalType" SG_ 1917 DTCI_CodeSupported_77D "BLN";
BA_ "VNSigAllNodes" SG_ 1917 DTCI_CodeSupported_77D 1;
BA_ "SignalLongName" SG_ 1917 DTCI_CurrentStatus_77D "Diagnostic Trouble Code Information Extended 77D : Current Status";
BA_ "PacketOrder" SG_ 1917 DTCI_CurrentStatus_77D 18;
BA_ "SignalType" SG_ 1917 DTCI_CurrentStatus_77D "BLN";
BA_ "VNSigAllNodes" SG_ 1917 DTCI_CurrentStatus_77D 1;
BA_ "SignalLongName" SG_ 1917 DTCI_TstNPsdCdClrdSt_77D "Diagnostic Trouble Code Information Extended 77D : Test Not Passed Since Code Cleared Status";
BA_ "PacketOrder" SG_ 1917 DTCI_TstNPsdCdClrdSt_77D 17;
BA_ "SignalType" SG_ 1917 DTCI_TstNPsdCdClrdSt_77D "BLN";
BA_ "VNSigAllNodes" SG_ 1917 DTCI_TstNPsdCdClrdSt_77D 1;
BA_ "SignalLongName" SG_ 1917 DTCI_TstFldCdClrdStat_77D "Diagnostic Trouble Code Information Extended 77D : Test Failed Since Code Cleared Status";
BA_ "PacketOrder" SG_ 1917 DTCI_TstFldCdClrdStat_77D 16;
BA_ "SignalType" SG_ 1917 DTCI_TstFldCdClrdStat_77D "BLN";
BA_ "VNSigAllNodes" SG_ 1917 DTCI_TstFldCdClrdStat_77D 1;
BA_ "SignalLongName" SG_ 1917 DTCI_HistStat_77D "Diagnostic Trouble Code Information Extended 77D : History Status";
BA_ "PacketOrder" SG_ 1917 DTCI_HistStat_77D 15;
BA_ "SignalType" SG_ 1917 DTCI_HistStat_77D "BLN";
BA_ "VNSigAllNodes" SG_ 1917 DTCI_HistStat_77D 1;
BA_ "SignalLongName" SG_ 1917 DTCI_TstNPsdPwrUpSt_77D "Diagnostic Trouble Code Information Extended 77D : Test Not Passed Since Power Up Status";
BA_ "PacketOrder" SG_ 1917 DTCI_TstNPsdPwrUpSt_77D 14;
BA_ "SignalType" SG_ 1917 DTCI_TstNPsdPwrUpSt_77D "BLN";
BA_ "VNSigAllNodes" SG_ 1917 DTCI_TstNPsdPwrUpSt_77D 1;
BA_ "SignalLongName" SG_ 1917 DTCI_TstFldPwrUpSt_77D "Diagnostic Trouble Code Information Extended 77D : Test Failed Since Power Up Status";
BA_ "PacketOrder" SG_ 1917 DTCI_TstFldPwrUpSt_77D 13;
BA_ "SignalType" SG_ 1917 DTCI_TstFldPwrUpSt_77D "BLN";
BA_ "VNSigAllNodes" SG_ 1917 DTCI_TstFldPwrUpSt_77D 1;
BA_ "SignalLongName" SG_ 1917 DTCI_WrnIndRqdSt_77D "Diagnostic Trouble Code Information Extended 77D : Warning Indicator Requested Status";
BA_ "PacketOrder" SG_ 1917 DTCI_WrnIndRqdSt_77D 12;
BA_ "SignalType" SG_ 1917 DTCI_WrnIndRqdSt_77D "BLN";
BA_ "VNSigAllNodes" SG_ 1917 DTCI_WrnIndRqdSt_77D 1;
BA_ "SignalLongName" SG_ 1917 DTCI_DTCFailType_77D "Diagnostic Trouble Code Information Extended 77D : Diagnostic Trouble Code Failure Type";
BA_ "PacketOrder" SG_ 1917 DTCI_DTCFailType_77D 11;
BA_ "SignalType" SG_ 1917 DTCI_DTCFailType_77D "UNM";
BA_ "VNSigAllNodes" SG_ 1917 DTCI_DTCFailType_77D 1;
BA_ "SignalLongName" SG_ 1917 DTCI_DTCNumber_77D "Diagnostic Trouble Code Information Extended 77D : Diagnostic Trouble Code Number";
BA_ "PacketOrder" SG_ 1917 DTCI_DTCNumber_77D 10;
BA_ "SignalType" SG_ 1917 DTCI_DTCNumber_77D "UNM";
BA_ "VNSigAllNodes" SG_ 1917 DTCI_DTCNumber_77D 1;
BA_ "SignalLongName" SG_ 1917 DTCI_DTCSource_77D "Diagnostic Trouble Code Information Extended 77D : Diagnostic Trouble Code Source";
BA_ "PacketOrder" SG_ 1917 DTCI_DTCSource_77D 9;
BA_ "SignalType" SG_ 1917 DTCI_DTCSource_77D "UNM";
BA_ "VNSigAllNodes" SG_ 1917 DTCI_DTCSource_77D 1;
BA_ "SignalLongName" SG_ 1917 DTCI_DTCTriggered_77D "Diagnostic Trouble Code Information Extended 77D : Diagnostic Trouble Code Triggered";
BA_ "PacketOrder" SG_ 1917 DTCI_DTCTriggered_77D 8;
BA_ "SignalType" SG_ 1917 DTCI_DTCTriggered_77D "BLN";
BA_ "VNSigAllNodes" SG_ 1917 DTCI_DTCTriggered_77D 1;
BA_ "SignalLongName" SG_ 1917 DTCIUnused7_77D "Diagnostic Trouble Code Information Extended 77D : Unused 7";
BA_ "PacketOrder" SG_ 1917 DTCIUnused7_77D 7;
BA_ "SignalType" SG_ 1917 DTCIUnused7_77D "BLN";
BA_ "VNSigAllNodes" SG_ 1917 DTCIUnused7_77D 1;
BA_ "SignalLongName" SG_ 1917 DTCIUnused6_77D "Diagnostic Trouble Code Information Extended 77D : Unused 6";
BA_ "PacketOrder" SG_ 1917 DTCIUnused6_77D 6;
BA_ "SignalType" SG_ 1917 DTCIUnused6_77D "BLN";
BA_ "VNSigAllNodes" SG_ 1917 DTCIUnused6_77D 1;
BA_ "SignalLongName" SG_ 1917 DTCIUnused5_77D "Diagnostic Trouble Code Information Extended 77D : Unused 5";
BA_ "PacketOrder" SG_ 1917 DTCIUnused5_77D 5;
BA_ "SignalType" SG_ 1917 DTCIUnused5_77D "BLN";
BA_ "VNSigAllNodes" SG_ 1917 DTCIUnused5_77D 1;
BA_ "SignalLongName" SG_ 1917 DTCIUnused4_77D "Diagnostic Trouble Code Information Extended 77D : Unused 4";
BA_ "PacketOrder" SG_ 1917 DTCIUnused4_77D 4;
BA_ "SignalType" SG_ 1917 DTCIUnused4_77D "BLN";
BA_ "VNSigAllNodes" SG_ 1917 DTCIUnused4_77D 1;
BA_ "SignalLongName" SG_ 1917 DTCIUnused3_77D "Diagnostic Trouble Code Information Extended 77D : Unused 3";
BA_ "PacketOrder" SG_ 1917 DTCIUnused3_77D 3;
BA_ "SignalType" SG_ 1917 DTCIUnused3_77D "BLN";
BA_ "VNSigAllNodes" SG_ 1917 DTCIUnused3_77D 1;
BA_ "SignalLongName" SG_ 1917 DTCIUnused2_77D "Diagnostic Trouble Code Information Extended 77D : Unused 2";
BA_ "PacketOrder" SG_ 1917 DTCIUnused2_77D 2;
BA_ "SignalType" SG_ 1917 DTCIUnused2_77D "BLN";
BA_ "VNSigAllNodes" SG_ 1917 DTCIUnused2_77D 1;
BA_ "SignalLongName" SG_ 1917 DTCIUnused1_77D "Diagnostic Trouble Code Information Extended 77D : Unused 1";
BA_ "PacketOrder" SG_ 1917 DTCIUnused1_77D 1;
BA_ "SignalType" SG_ 1917 DTCIUnused1_77D "BLN";
BA_ "VNSigAllNodes" SG_ 1917 DTCIUnused1_77D 1;
BA_ "SignalLongName" SG_ 1620 DgnInf "Diagnostic Information";
BA_ "SignalType" SG_ 1620 DgnInf "UNM";
BA_ "VNSigAllNodes" SG_ 1620 DgnInf 1;
BA_ "VNSigSLHSSharedDiagnostic" SG_ 1620 DgnInf 1;
BA_ "SignalLongName" SG_ 388 HndsOffStrWhlDtStV "Hands Off Steering Wheel Detection State Validity";
BA_ "SignalType" SG_ 388 HndsOffStrWhlDtStV "ENM";
BA_ "VNSigAllNodes" SG_ 388 HndsOffStrWhlDtStV 1;
BA_ "SignalLongName" SG_ 388 HndsOffStrWhlDtSt "Hands Off Steering Wheel Detection State";
BA_ "SignalType" SG_ 388 HndsOffStrWhlDtSt "ENM";
BA_ "VNSigAllNodes" SG_ 388 HndsOffStrWhlDtSt 1;
BA_ "SignalLongName" SG_ 388 HndsOffStrWhlDtMd "Hands Off Steering Wheel Detection Mode";
BA_ "SignalType" SG_ 388 HndsOffStrWhlDtMd "ENM";
BA_ "VNSigAllNodes" SG_ 388 HndsOffStrWhlDtMd 1;
BA_ "SignalLongName" SG_ 388 LKASig0825 "Lane Keeping Assist Signal0825";
BA_ "SignalType" SG_ 388 LKASig0825 "UNM";
BA_ "VNSigAllNodes" SG_ 388 LKASig0825 1;
BA_ "SignalLongName" SG_ 388 LKATrqOvrlDltTrqDlvd "Lane Keeping Assist Torque Overlay Delta Torque Delivered";
BA_ "SignalType" SG_ 388 LKATrqOvrlDltTrqDlvd "SNM";
BA_ "VNSigAllNodes" SG_ 388 LKATrqOvrlDltTrqDlvd 1;
BA_ "SignalLongName" SG_ 388 LKATrqOvrlDlvdRC "Lane Keeping Assist Torque Overlay Delivered Rolling Count";
BA_ "SignalType" SG_ 388 LKATrqOvrlDlvdRC "UNM";
BA_ "VNSigAllNodes" SG_ 388 LKATrqOvrlDlvdRC 1;
BA_ "SignalLongName" SG_ 388 LKAElPwrStTtlTqDlvd "Lane Keeping Assist Electrical Power Steering Total Torque Delivered";
BA_ "SignalType" SG_ 388 LKAElPwrStTtlTqDlvd "SNM";
BA_ "VNSigAllNodes" SG_ 388 LKAElPwrStTtlTqDlvd 1;
BA_ "SignalLongName" SG_ 388 LKATrqOvrlTrqDStat "Lane Keeping Assist Torque Overlay Torque Delivered Status";
BA_ "SignalType" SG_ 388 LKATrqOvrlTrqDStat "ENM";
BA_ "VNSigAllNodes" SG_ 388 LKATrqOvrlTrqDStat 1;
BA_ "SignalLongName" SG_ 388 LKADrvAppldTrqV "Lane Keeping Assist Driver Applied Torque Validity";
BA_ "SignalType" SG_ 388 LKADrvAppldTrqV "ENM";
BA_ "VNSigAllNodes" SG_ 388 LKADrvAppldTrqV 1;
BA_ "SignalLongName" SG_ 388 LKADrvAppldTrq "Lane Keeping Assist Driver Applied Torque";
BA_ "SignalType" SG_ 388 LKADrvAppldTrq "SNM";
BA_ "VNSigAllNodes" SG_ 388 LKADrvAppldTrq 1;
BA_ "SignalLongName" SG_ 587 DgnInf "Diagnostic Information";
BA_ "SignalType" SG_ 587 DgnInf "UNM";
BA_ "VNSigAllNodes" SG_ 587 DgnInf 1;
BA_ "VNSigSLHSSharedDiagnostic" SG_ 587 DgnInf 1;
BA_ "SignalLongName" SG_ 884 AdvWthrStat "Adverse Weather Status";
BA_ "SignalType" SG_ 884 AdvWthrStat "ENM";
BA_ "VNSigAllNodes" SG_ 884 AdvWthrStat 1;
BA_ "SignalLongName" SG_ 884 RgDtLgtSrcHrtAngVcty "Right Detected Light Source Horizontal Angular Velocity";
BA_ "SignalType" SG_ 884 RgDtLgtSrcHrtAngVcty "SNM";
BA_ "VNSigAllNodes" SG_ 884 RgDtLgtSrcHrtAngVcty 1;
BA_ "SignalLongName" SG_ 884 RgDtLgtSrcHrtAngl "Right Detected Light Source Horizontal Angle";
BA_ "SignalType" SG_ 884 RgDtLgtSrcHrtAngl "SNM";
BA_ "VNSigAllNodes" SG_ 884 RgDtLgtSrcHrtAngl 1;
BA_ "SignalLongName" SG_ 884 LfDtLgtSrcHrtAnVcty "Left Detected Light Source Horizontal Angular Velocity";
BA_ "SignalType" SG_ 884 LfDtLgtSrcHrtAnVcty "SNM";
BA_ "VNSigAllNodes" SG_ 884 LfDtLgtSrcHrtAnVcty 1;
BA_ "SignalLongName" SG_ 884 LfDtLgtSrcHrtAngl "Left Detected Light Source Horizontal Angle";
BA_ "SignalType" SG_ 884 LfDtLgtSrcHrtAngl "SNM";
BA_ "VNSigAllNodes" SG_ 884 LfDtLgtSrcHrtAngl 1;
BA_ "SignalLongName" SG_ 884 DtctdLghtSrcDstnc "Detected Light Source Distance";
BA_ "SignalType" SG_ 884 DtctdLghtSrcDstnc "UNM";
BA_ "VNSigAllNodes" SG_ 884 DtctdLghtSrcDstnc 1;
BA_ "SignalLongName" SG_ 884 DtctdLghtSrcVrtclAngl "Detected Light Source Vertical Angle";
BA_ "SignalType" SG_ 884 DtctdLghtSrcVrtclAngl "SNM";
BA_ "VNSigAllNodes" SG_ 884 DtctdLghtSrcVrtclAngl 1;
BA_ "SignalLongName" SG_ 884 DtctdLghtSrcDrvngDrctn "Detected Light Source Driving Direction";
BA_ "SignalType" SG_ 884 DtctdLghtSrcDrvngDrctn "ENM";
BA_ "VNSigAllNodes" SG_ 884 DtctdLghtSrcDrvngDrctn 1;
BA_ "SignalLongName" SG_ 884 TwnDtctnSts "Town Detection Status";
BA_ "SignalType" SG_ 884 TwnDtctnSts "ENM";
BA_ "VNSigAllNodes" SG_ 884 TwnDtctnSts 1;
BA_ "SignalLongName" SG_ 884 DtctdLghtSrcDstncV "Detected Light Source Distance Validity";
BA_ "SignalType" SG_ 884 DtctdLghtSrcDstncV "ENM";
BA_ "VNSigAllNodes" SG_ 884 DtctdLghtSrcDstncV 1;
BA_ "SignalLongName" SG_ 884 IntLghtRngAct "Intelligent Light Ranging Active";
BA_ "SignalType" SG_ 884 IntLghtRngAct "BLN";
BA_ "VNSigAllNodes" SG_ 884 IntLghtRngAct 1;
BA_ "SignalLongName" SG_ 1930 DTCI_CodeSupported_78A "Diagnostic Trouble Code Information Extended 78A : Code Supported";
BA_ "PacketOrder" SG_ 1930 DTCI_CodeSupported_78A 19;
BA_ "SignalType" SG_ 1930 DTCI_CodeSupported_78A "BLN";
BA_ "VNSigAllNodes" SG_ 1930 DTCI_CodeSupported_78A 1;
BA_ "SignalLongName" SG_ 1930 DTCI_CurrentStatus_78A "Diagnostic Trouble Code Information Extended 78A : Current Status";
BA_ "PacketOrder" SG_ 1930 DTCI_CurrentStatus_78A 18;
BA_ "SignalType" SG_ 1930 DTCI_CurrentStatus_78A "BLN";
BA_ "VNSigAllNodes" SG_ 1930 DTCI_CurrentStatus_78A 1;
BA_ "SignalLongName" SG_ 1930 DTCI_DTCFailType_78A "Diagnostic Trouble Code Information Extended 78A : Diagnostic Trouble Code Failure Type";
BA_ "PacketOrder" SG_ 1930 DTCI_DTCFailType_78A 11;
BA_ "SignalType" SG_ 1930 DTCI_DTCFailType_78A "UNM";
BA_ "VNSigAllNodes" SG_ 1930 DTCI_DTCFailType_78A 1;
BA_ "SignalLongName" SG_ 1930 DTCI_DTCFaultType_78A "Diagnostic Trouble Code Information Extended 78A : Diagnostic Trouble Code Fault Type";
BA_ "PacketOrder" SG_ 1930 DTCI_DTCFaultType_78A 20;
BA_ "SignalType" SG_ 1930 DTCI_DTCFaultType_78A "ENM";
BA_ "VNSigAllNodes" SG_ 1930 DTCI_DTCFaultType_78A 1;
BA_ "SignalLongName" SG_ 1930 DTCI_DTCNumber_78A "Diagnostic Trouble Code Information Extended 78A : Diagnostic Trouble Code Number";
BA_ "PacketOrder" SG_ 1930 DTCI_DTCNumber_78A 10;
BA_ "SignalType" SG_ 1930 DTCI_DTCNumber_78A "UNM";
BA_ "VNSigAllNodes" SG_ 1930 DTCI_DTCNumber_78A 1;
BA_ "SignalLongName" SG_ 1930 DTCI_DTCSource_78A "Diagnostic Trouble Code Information Extended 78A : Diagnostic Trouble Code Source";
BA_ "PacketOrder" SG_ 1930 DTCI_DTCSource_78A 9;
BA_ "SignalType" SG_ 1930 DTCI_DTCSource_78A "UNM";
BA_ "VNSigAllNodes" SG_ 1930 DTCI_DTCSource_78A 1;
BA_ "SignalLongName" SG_ 1930 DTCI_DTCTriggered_78A "Diagnostic Trouble Code Information Extended 78A : Diagnostic Trouble Code Triggered";
BA_ "PacketOrder" SG_ 1930 DTCI_DTCTriggered_78A 8;
BA_ "SignalType" SG_ 1930 DTCI_DTCTriggered_78A "BLN";
BA_ "VNSigAllNodes" SG_ 1930 DTCI_DTCTriggered_78A 1;
BA_ "SignalLongName" SG_ 1930 DTCI_HistStat_78A "Diagnostic Trouble Code Information Extended 78A : History Status";
BA_ "PacketOrder" SG_ 1930 DTCI_HistStat_78A 15;
BA_ "SignalType" SG_ 1930 DTCI_HistStat_78A "BLN";
BA_ "VNSigAllNodes" SG_ 1930 DTCI_HistStat_78A 1;
BA_ "SignalLongName" SG_ 1930 DTCI_TstFldCdClrdStat_78A "Diagnostic Trouble Code Information Extended 78A : Test Failed Since Code Cleared Status";
BA_ "PacketOrder" SG_ 1930 DTCI_TstFldCdClrdStat_78A 16;
BA_ "SignalType" SG_ 1930 DTCI_TstFldCdClrdStat_78A "BLN";
BA_ "VNSigAllNodes" SG_ 1930 DTCI_TstFldCdClrdStat_78A 1;
BA_ "SignalLongName" SG_ 1930 DTCI_TstFldPwrUpSt_78A "Diagnostic Trouble Code Information Extended 78A : Test Failed Since Power Up Status";
BA_ "PacketOrder" SG_ 1930 DTCI_TstFldPwrUpSt_78A 13;
BA_ "SignalType" SG_ 1930 DTCI_TstFldPwrUpSt_78A "BLN";
BA_ "VNSigAllNodes" SG_ 1930 DTCI_TstFldPwrUpSt_78A 1;
BA_ "SignalLongName" SG_ 1930 DTCI_TstNPsdCdClrdSt_78A "Diagnostic Trouble Code Information Extended 78A : Test Not Passed Since Code Cleared Status";
BA_ "PacketOrder" SG_ 1930 DTCI_TstNPsdCdClrdSt_78A 17;
BA_ "SignalType" SG_ 1930 DTCI_TstNPsdCdClrdSt_78A "BLN";
BA_ "VNSigAllNodes" SG_ 1930 DTCI_TstNPsdCdClrdSt_78A 1;
BA_ "SignalLongName" SG_ 1930 DTCI_TstNPsdPwrUpSt_78A "Diagnostic Trouble Code Information Extended 78A : Test Not Passed Since Power Up Status";
BA_ "PacketOrder" SG_ 1930 DTCI_TstNPsdPwrUpSt_78A 14;
BA_ "SignalType" SG_ 1930 DTCI_TstNPsdPwrUpSt_78A "BLN";
BA_ "VNSigAllNodes" SG_ 1930 DTCI_TstNPsdPwrUpSt_78A 1;
BA_ "SignalLongName" SG_ 1930 DTCIUnused1_78A "Diagnostic Trouble Code Information Extended 78A : Unused 1";
BA_ "PacketOrder" SG_ 1930 DTCIUnused1_78A 1;
BA_ "SignalType" SG_ 1930 DTCIUnused1_78A "BLN";
BA_ "VNSigAllNodes" SG_ 1930 DTCIUnused1_78A 1;
BA_ "SignalLongName" SG_ 1930 DTCIUnused2_78A "Diagnostic Trouble Code Information Extended 78A : Unused 2";
BA_ "PacketOrder" SG_ 1930 DTCIUnused2_78A 2;
BA_ "SignalType" SG_ 1930 DTCIUnused2_78A "BLN";
BA_ "VNSigAllNodes" SG_ 1930 DTCIUnused2_78A 1;
BA_ "SignalLongName" SG_ 1930 DTCIUnused3_78A "Diagnostic Trouble Code Information Extended 78A : Unused 3";
BA_ "PacketOrder" SG_ 1930 DTCIUnused3_78A 3;
BA_ "SignalType" SG_ 1930 DTCIUnused3_78A "BLN";
BA_ "VNSigAllNodes" SG_ 1930 DTCIUnused3_78A 1;
BA_ "SignalLongName" SG_ 1930 DTCIUnused4_78A "Diagnostic Trouble Code Information Extended 78A : Unused 4";
BA_ "PacketOrder" SG_ 1930 DTCIUnused4_78A 4;
BA_ "SignalType" SG_ 1930 DTCIUnused4_78A "BLN";
BA_ "VNSigAllNodes" SG_ 1930 DTCIUnused4_78A 1;
BA_ "SignalLongName" SG_ 1930 DTCIUnused5_78A "Diagnostic Trouble Code Information Extended 78A : Unused 5";
BA_ "PacketOrder" SG_ 1930 DTCIUnused5_78A 5;
BA_ "SignalType" SG_ 1930 DTCIUnused5_78A "BLN";
BA_ "VNSigAllNodes" SG_ 1930 DTCIUnused5_78A 1;
BA_ "SignalLongName" SG_ 1930 DTCIUnused6_78A "Diagnostic Trouble Code Information Extended 78A : Unused 6";
BA_ "PacketOrder" SG_ 1930 DTCIUnused6_78A 6;
BA_ "SignalType" SG_ 1930 DTCIUnused6_78A "BLN";
BA_ "VNSigAllNodes" SG_ 1930 DTCIUnused6_78A 1;
BA_ "SignalLongName" SG_ 1930 DTCIUnused7_78A "Diagnostic Trouble Code Information Extended 78A : Unused 7";
BA_ "PacketOrder" SG_ 1930 DTCIUnused7_78A 7;
BA_ "SignalType" SG_ 1930 DTCIUnused7_78A "BLN";
BA_ "VNSigAllNodes" SG_ 1930 DTCIUnused7_78A 1;
BA_ "SignalLongName" SG_ 1930 DTCI_WrnIndRqdSt_78A "Diagnostic Trouble Code Information Extended 78A : Warning Indicator Requested Status";
BA_ "PacketOrder" SG_ 1930 DTCI_WrnIndRqdSt_78A 12;
BA_ "SignalType" SG_ 1930 DTCI_WrnIndRqdSt_78A "BLN";
BA_ "VNSigAllNodes" SG_ 1930 DTCI_WrnIndRqdSt_78A 1;
BA_ "SignalLongName" SG_ 1611 DgnInf "Diagnostic Information";
BA_ "SignalType" SG_ 1611 DgnInf "UNM";
BA_ "VNSigAllNodes" SG_ 1611 DgnInf 1;
BA_ "VNSigSLHSSharedDiagnostic" SG_ 1611 DgnInf 1;
BA_ "SignalLongName" SG_ 1355 DgnInf_HS54B "Diagnostic Information HS54B";
BA_ "SignalType" SG_ 1355 DgnInf_HS54B "UNM";
BA_ "VNSigAllNodes" SG_ 1355 DgnInf_HS54B 1;
BA_ "VNSigSLHSSharedDiagnostic" SG_ 1355 DgnInf_HS54B 1;
BA_ "SignalLongName" SG_ 598 DgnInf "Diagnostic Information";
BA_ "SignalType" SG_ 598 DgnInf "UNM";
BA_ "VNSigAllNodes" SG_ 598 DgnInf 1;
BA_ "VNSigSLHSSharedDiagnostic" SG_ 598 DgnInf 1;
BA_ "SignalLongName" SG_ 1366 DgnInf_HS556 "Diagnostic Information HS556";
BA_ "SignalType" SG_ 1366 DgnInf_HS556 "UNM";
BA_ "VNSigAllNodes" SG_ 1366 DgnInf_HS556 1;
BA_ "VNSigSLHSSharedDiagnostic" SG_ 1366 DgnInf_HS556 1;
BA_ "SignalLongName" SG_ 1622 DgnInf "Diagnostic Information";
BA_ "SignalType" SG_ 1622 DgnInf "UNM";
BA_ "VNSigAllNodes" SG_ 1622 DgnInf 1;
BA_ "VNSigSLHSSharedDiagnostic" SG_ 1622 DgnInf 1;
BA_ "SignalLongName" SG_ 591 DgnInf "Diagnostic Information";
BA_ "SignalType" SG_ 591 DgnInf "UNM";
BA_ "VNSigAllNodes" SG_ 591 DgnInf 1;
BA_ "VNSigSLHSSharedDiagnostic" SG_ 591 DgnInf 1;
BA_ "SignalLongName" SG_ 1914 DTCI_DTCFaultType_77A "Diagnostic Trouble Code Information Extended 77A : Diagnostic Trouble Code Fault Type";
BA_ "PacketOrder" SG_ 1914 DTCI_DTCFaultType_77A 20;
BA_ "SignalType" SG_ 1914 DTCI_DTCFaultType_77A "ENM";
BA_ "VNSigAllNodes" SG_ 1914 DTCI_DTCFaultType_77A 1;
BA_ "SignalLongName" SG_ 1914 DTCI_CodeSupported_77A "Diagnostic Trouble Code Information Extended 77A : Code Supported";
BA_ "PacketOrder" SG_ 1914 DTCI_CodeSupported_77A 19;
BA_ "SignalType" SG_ 1914 DTCI_CodeSupported_77A "BLN";
BA_ "VNSigAllNodes" SG_ 1914 DTCI_CodeSupported_77A 1;
BA_ "SignalLongName" SG_ 1914 DTCI_CurrentStatus_77A "Diagnostic Trouble Code Information Extended 77A : Current Status";
BA_ "PacketOrder" SG_ 1914 DTCI_CurrentStatus_77A 18;
BA_ "SignalType" SG_ 1914 DTCI_CurrentStatus_77A "BLN";
BA_ "VNSigAllNodes" SG_ 1914 DTCI_CurrentStatus_77A 1;
BA_ "SignalLongName" SG_ 1914 DTCI_TstNPsdCdClrdSt_77A "Diagnostic Trouble Code Information Extended 77A : Test Not Passed Since Code Cleared Status";
BA_ "PacketOrder" SG_ 1914 DTCI_TstNPsdCdClrdSt_77A 17;
BA_ "SignalType" SG_ 1914 DTCI_TstNPsdCdClrdSt_77A "BLN";
BA_ "VNSigAllNodes" SG_ 1914 DTCI_TstNPsdCdClrdSt_77A 1;
BA_ "SignalLongName" SG_ 1914 DTCI_TstFldCdClrdStat_77A "Diagnostic Trouble Code Information Extended 77A : Test Failed Since Code Cleared Status";
BA_ "PacketOrder" SG_ 1914 DTCI_TstFldCdClrdStat_77A 16;
BA_ "SignalType" SG_ 1914 DTCI_TstFldCdClrdStat_77A "BLN";
BA_ "VNSigAllNodes" SG_ 1914 DTCI_TstFldCdClrdStat_77A 1;
BA_ "SignalLongName" SG_ 1914 DTCI_HistStat_77A "Diagnostic Trouble Code Information Extended 77A : History Status";
BA_ "PacketOrder" SG_ 1914 DTCI_HistStat_77A 15;
BA_ "SignalType" SG_ 1914 DTCI_HistStat_77A "BLN";
BA_ "VNSigAllNodes" SG_ 1914 DTCI_HistStat_77A 1;
BA_ "SignalLongName" SG_ 1914 DTCI_TstNPsdPwrUpSt_77A "Diagnostic Trouble Code Information Extended 77A : Test Not Passed Since Power Up Status";
BA_ "PacketOrder" SG_ 1914 DTCI_TstNPsdPwrUpSt_77A 14;
BA_ "SignalType" SG_ 1914 DTCI_TstNPsdPwrUpSt_77A "BLN";
BA_ "VNSigAllNodes" SG_ 1914 DTCI_TstNPsdPwrUpSt_77A 1;
BA_ "SignalLongName" SG_ 1914 DTCI_TstFldPwrUpSt_77A "Diagnostic Trouble Code Information Extended 77A : Test Failed Since Power Up Status";
BA_ "PacketOrder" SG_ 1914 DTCI_TstFldPwrUpSt_77A 13;
BA_ "SignalType" SG_ 1914 DTCI_TstFldPwrUpSt_77A "BLN";
BA_ "VNSigAllNodes" SG_ 1914 DTCI_TstFldPwrUpSt_77A 1;
BA_ "SignalLongName" SG_ 1914 DTCI_WrnIndRqdSt_77A "Diagnostic Trouble Code Information Extended 77A : Warning Indicator Requested Status";
BA_ "PacketOrder" SG_ 1914 DTCI_WrnIndRqdSt_77A 12;
BA_ "SignalType" SG_ 1914 DTCI_WrnIndRqdSt_77A "BLN";
BA_ "VNSigAllNodes" SG_ 1914 DTCI_WrnIndRqdSt_77A 1;
BA_ "SignalLongName" SG_ 1914 DTCI_DTCFailType_77A "Diagnostic Trouble Code Information Extended 77A : Diagnostic Trouble Code Failure Type";
BA_ "PacketOrder" SG_ 1914 DTCI_DTCFailType_77A 11;
BA_ "SignalType" SG_ 1914 DTCI_DTCFailType_77A "UNM";
BA_ "VNSigAllNodes" SG_ 1914 DTCI_DTCFailType_77A 1;
BA_ "SignalLongName" SG_ 1914 DTCI_DTCNumber_77A "Diagnostic Trouble Code Information Extended 77A : Diagnostic Trouble Code Number";
BA_ "PacketOrder" SG_ 1914 DTCI_DTCNumber_77A 10;
BA_ "SignalType" SG_ 1914 DTCI_DTCNumber_77A "UNM";
BA_ "VNSigAllNodes" SG_ 1914 DTCI_DTCNumber_77A 1;
BA_ "SignalLongName" SG_ 1914 DTCI_DTCSource_77A "Diagnostic Trouble Code Information Extended 77A : Diagnostic Trouble Code Source";
BA_ "PacketOrder" SG_ 1914 DTCI_DTCSource_77A 9;
BA_ "SignalType" SG_ 1914 DTCI_DTCSource_77A "UNM";
BA_ "VNSigAllNodes" SG_ 1914 DTCI_DTCSource_77A 1;
BA_ "SignalLongName" SG_ 1914 DTCI_DTCTriggered_77A "Diagnostic Trouble Code Information Extended 77A : Diagnostic Trouble Code Triggered";
BA_ "PacketOrder" SG_ 1914 DTCI_DTCTriggered_77A 8;
BA_ "SignalType" SG_ 1914 DTCI_DTCTriggered_77A "BLN";
BA_ "VNSigAllNodes" SG_ 1914 DTCI_DTCTriggered_77A 1;
BA_ "SignalLongName" SG_ 1914 DTCIUnused7_77A "Diagnostic Trouble Code Information Extended 77A : Unused 7";
BA_ "PacketOrder" SG_ 1914 DTCIUnused7_77A 7;
BA_ "SignalType" SG_ 1914 DTCIUnused7_77A "BLN";
BA_ "VNSigAllNodes" SG_ 1914 DTCIUnused7_77A 1;
BA_ "SignalLongName" SG_ 1914 DTCIUnused6_77A "Diagnostic Trouble Code Information Extended 77A : Unused 6";
BA_ "PacketOrder" SG_ 1914 DTCIUnused6_77A 6;
BA_ "SignalType" SG_ 1914 DTCIUnused6_77A "BLN";
BA_ "VNSigAllNodes" SG_ 1914 DTCIUnused6_77A 1;
BA_ "SignalLongName" SG_ 1914 DTCIUnused5_77A "Diagnostic Trouble Code Information Extended 77A : Unused 5";
BA_ "PacketOrder" SG_ 1914 DTCIUnused5_77A 5;
BA_ "SignalType" SG_ 1914 DTCIUnused5_77A "BLN";
BA_ "VNSigAllNodes" SG_ 1914 DTCIUnused5_77A 1;
BA_ "SignalLongName" SG_ 1914 DTCIUnused4_77A "Diagnostic Trouble Code Information Extended 77A : Unused 4";
BA_ "PacketOrder" SG_ 1914 DTCIUnused4_77A 4;
BA_ "SignalType" SG_ 1914 DTCIUnused4_77A "BLN";
BA_ "VNSigAllNodes" SG_ 1914 DTCIUnused4_77A 1;
BA_ "SignalLongName" SG_ 1914 DTCIUnused3_77A "Diagnostic Trouble Code Information Extended 77A : Unused 3";
BA_ "PacketOrder" SG_ 1914 DTCIUnused3_77A 3;
BA_ "SignalType" SG_ 1914 DTCIUnused3_77A "BLN";
BA_ "VNSigAllNodes" SG_ 1914 DTCIUnused3_77A 1;
BA_ "SignalLongName" SG_ 1914 DTCIUnused2_77A "Diagnostic Trouble Code Information Extended 77A : Unused 2";
BA_ "PacketOrder" SG_ 1914 DTCIUnused2_77A 2;
BA_ "SignalType" SG_ 1914 DTCIUnused2_77A "BLN";
BA_ "VNSigAllNodes" SG_ 1914 DTCIUnused2_77A 1;
BA_ "SignalLongName" SG_ 1914 DTCIUnused1_77A "Diagnostic Trouble Code Information Extended 77A : Unused 1";
BA_ "PacketOrder" SG_ 1914 DTCIUnused1_77A 1;
BA_ "SignalType" SG_ 1914 DTCIUnused1_77A "BLN";
BA_ "VNSigAllNodes" SG_ 1914 DTCIUnused1_77A 1;
BA_ "SignalLongName" SG_ 2032 DgnInf "Diagnostic Information";
BA_ "SignalType" SG_ 2032 DgnInf "UNM";
BA_ "VNSigAllNodes" SG_ 2032 DgnInf 1;
BA_ "VNSigSLHSSharedDiagnostic" SG_ 2032 DgnInf 1;
BA_ "SignalLongName" SG_ 583 DgnInf "Diagnostic Information";
BA_ "SignalType" SG_ 583 DgnInf "UNM";
BA_ "VNSigAllNodes" SG_ 583 DgnInf 1;
BA_ "VNSigSLHSSharedDiagnostic" SG_ 583 DgnInf 1;
BA_ "SignalLongName" SG_ 2034 DgnInf "Diagnostic Information";
BA_ "SignalType" SG_ 2034 DgnInf "UNM";
BA_ "VNSigAllNodes" SG_ 2034 DgnInf 1;
BA_ "VNSigSLHSSharedDiagnostic" SG_ 2034 DgnInf 1;
BA_ "SignalLongName" SG_ 894 RtLwBmFld "Right Low Beam Failed";
BA_ "SignalType" SG_ 894 RtLwBmFld "BLN";
BA_ "VNSigAllNodes" SG_ 894 RtLwBmFld 1;
BA_ "GenSigSendType" SG_ 894 RtLwBmFld 10;
BA_ "GenSigSendOnInit" SG_ 894 RtLwBmFld 1;
BA_ "SignalLongName" SG_ 894 LftLwBmFld "Left Low Beam Failed";
BA_ "SignalType" SG_ 894 LftLwBmFld "BLN";
BA_ "VNSigAllNodes" SG_ 894 LftLwBmFld 1;
BA_ "GenSigSendType" SG_ 894 LftLwBmFld 10;
BA_ "GenSigSendOnInit" SG_ 894 LftLwBmFld 1;
BA_ "SignalLongName" SG_ 894 AdvFrntLghtSysIndRq "Advanced Front Lighting System Indication Request";
BA_ "SignalType" SG_ 894 AdvFrntLghtSysIndRq "ENM";
BA_ "VNSigAllNodes" SG_ 894 AdvFrntLghtSysIndRq 1;
BA_ "SignalLongName" SG_ 894 HdLtLvlFlrIO "Head Light Leveling Failure Indication On";
BA_ "SignalType" SG_ 894 HdLtLvlFlrIO "BLN";
BA_ "VNSigAllNodes" SG_ 894 HdLtLvlFlrIO 1;
BA_ "SignalLongName" SG_ 577 DgnInf "Diagnostic Information";
BA_ "SignalType" SG_ 577 DgnInf "UNM";
BA_ "VNSigAllNodes" SG_ 577 DgnInf 1;
BA_ "VNSigSLHSSharedDiagnostic" SG_ 577 DgnInf 1;
BA_ "SignalLongName" SG_ 804 CompOvrhtIndOn "Compressor Overheated Indication On";
BA_ "SignalType" SG_ 804 CompOvrhtIndOn "BLN";
BA_ "VNSigAllNodes" SG_ 804 CompOvrhtIndOn 1;
BA_ "SignalLongName" SG_ 804 VehHghtStatV "Vehicle Height Status Validity";
BA_ "SignalType" SG_ 804 VehHghtStatV "ENM";
BA_ "VNSigAllNodes" SG_ 804 VehHghtStatV 1;
BA_ "SignalLongName" SG_ 804 VehHghtStat "Vehicle Height Status";
BA_ "SignalType" SG_ 804 VehHghtStat "ENM";
BA_ "VNSigAllNodes" SG_ 804 VehHghtStat 1;
BA_ "SignalLongName" SG_ 804 SrvLevSysIO "Service Leveling System Indication On";
BA_ "SignalType" SG_ 804 SrvLevSysIO "BLN";
BA_ "VNSigAllNodes" SG_ 804 SrvLevSysIO 1;
BA_ "SignalLongName" SG_ 804 LevSysVehTopSpdLim "Leveling System Vehicle Top Speed Limit Value";
BA_ "SignalType" SG_ 804 LevSysVehTopSpdLim "UNM";
BA_ "VNSigAllNodes" SG_ 804 LevSysVehTopSpdLim 1;
BA_ "SignalLongName" SG_ 804 VehOvrLdIndOn "Vehicle Overloaded Indication On";
BA_ "SignalType" SG_ 804 VehOvrLdIndOn "BLN";
BA_ "VNSigAllNodes" SG_ 804 VehOvrLdIndOn 1;
BA_ "SignalLongName" SG_ 842 WhlGrndVlctyRtNnDrvnV "Wheel Ground Velocity Right Non Driven Validity";
BA_ "SignalType" SG_ 842 WhlGrndVlctyRtNnDrvnV "ENM";
BA_ "VNSigAllNodes" SG_ 842 WhlGrndVlctyRtNnDrvnV 1;
BA_ "SignalLongName" SG_ 842 WhlGrndVlctyRtNnDrvn "Wheel Ground Velocity Right Non Driven";
BA_ "SignalType" SG_ 842 WhlGrndVlctyRtNnDrvn "UNM";
BA_ "VNSigAllNodes" SG_ 842 WhlGrndVlctyRtNnDrvn 1;
BA_ "SignalLongName" SG_ 842 WhlGrndVlctyLftNnDrvnV "Wheel Ground Velocity Left Non Driven Validity";
BA_ "SignalType" SG_ 842 WhlGrndVlctyLftNnDrvnV "ENM";
BA_ "VNSigAllNodes" SG_ 842 WhlGrndVlctyLftNnDrvnV 1;
BA_ "SignalLongName" SG_ 842 WhlGrndVlctyLftNnDrvn "Wheel Ground Velocity Left Non Driven";
BA_ "SignalType" SG_ 842 WhlGrndVlctyLftNnDrvn "UNM";
BA_ "VNSigAllNodes" SG_ 842 WhlGrndVlctyLftNnDrvn 1;
BA_ "SignalLongName" SG_ 842 WhlRotDrctnlSRtNDrvn "Wheel Rotational Directional Status Right Non Driven";
BA_ "SignalType" SG_ 842 WhlRotDrctnlSRtNDrvn "ENM";
BA_ "VNSigAllNodes" SG_ 842 WhlRotDrctnlSRtNDrvn 1;
BA_ "SignalLongName" SG_ 842 WhlRotDrctnlStLfNDrvn "Wheel Rotational Directional Status Left Non Driven";
BA_ "SignalType" SG_ 842 WhlRotDrctnlStLfNDrvn "ENM";
BA_ "VNSigAllNodes" SG_ 842 WhlRotDrctnlStLfNDrvn 1;
BA_ "SignalLongName" SG_ 840 WhlGrndVlctyRtDrvnV "Wheel Ground Velocity Right Driven Validity";
BA_ "SignalType" SG_ 840 WhlGrndVlctyRtDrvnV "ENM";
BA_ "VNSigAllNodes" SG_ 840 WhlGrndVlctyRtDrvnV 1;
BA_ "SignalLongName" SG_ 840 WhlGrndVlctyRtDrvn "Wheel Ground Velocity Right Driven";
BA_ "SignalType" SG_ 840 WhlGrndVlctyRtDrvn "UNM";
BA_ "VNSigAllNodes" SG_ 840 WhlGrndVlctyRtDrvn 1;
BA_ "SignalLongName" SG_ 840 WhlGrndVlctyLftDrvnV "Wheel Ground Velocity Left Driven Validity";
BA_ "SignalType" SG_ 840 WhlGrndVlctyLftDrvnV "ENM";
BA_ "VNSigAllNodes" SG_ 840 WhlGrndVlctyLftDrvnV 1;
BA_ "SignalLongName" SG_ 840 WhlGrndVlctyLftDrvn "Wheel Ground Velocity Left Driven";
BA_ "SignalType" SG_ 840 WhlGrndVlctyLftDrvn "UNM";
BA_ "VNSigAllNodes" SG_ 840 WhlGrndVlctyLftDrvn 1;
BA_ "SignalLongName" SG_ 840 WhlRotDrctnlStLftDrvn "Wheel Rotational Directional Status Left Driven";
BA_ "SignalType" SG_ 840 WhlRotDrctnlStLftDrvn "ENM";
BA_ "VNSigAllNodes" SG_ 840 WhlRotDrctnlStLftDrvn 1;
BA_ "SignalLongName" SG_ 840 WhlRotDrctnlStRtDrvn "Wheel Rotational Directional Status Right Driven";
BA_ "SignalType" SG_ 840 WhlRotDrctnlStRtDrvn "ENM";
BA_ "VNSigAllNodes" SG_ 840 WhlRotDrctnlStRtDrvn 1;
BA_ "SignalLongName" SG_ 1323 TireLRTmpV "Tire Left Rear Temperature Validity";
BA_ "SignalType" SG_ 1323 TireLRTmpV "ENM";
BA_ "VNSigAllNodes" SG_ 1323 TireLRTmpV 1;
BA_ "SignalLongName" SG_ 1323 TireLRTmp "Tire Left Rear Temperature";
BA_ "SignalType" SG_ 1323 TireLRTmp "UNM";
BA_ "VNSigAllNodes" SG_ 1323 TireLRTmp 1;
BA_ "SignalLongName" SG_ 1323 TireLFTmpV "Tire Left Front Temperature Validity";
BA_ "SignalType" SG_ 1323 TireLFTmpV "ENM";
BA_ "VNSigAllNodes" SG_ 1323 TireLFTmpV 1;
BA_ "SignalLongName" SG_ 1323 TireLFTmp "Tire Left Front Temperature";
BA_ "SignalType" SG_ 1323 TireLFTmp "UNM";
BA_ "VNSigAllNodes" SG_ 1323 TireLFTmp 1;
BA_ "SignalLongName" SG_ 1323 TireRRTmpV "Tire Right Rear Temperature Validity";
BA_ "SignalType" SG_ 1323 TireRRTmpV "ENM";
BA_ "VNSigAllNodes" SG_ 1323 TireRRTmpV 1;
BA_ "SignalLongName" SG_ 1323 TireRRTmp "Tire Right Rear Temperature";
BA_ "SignalType" SG_ 1323 TireRRTmp "UNM";
BA_ "VNSigAllNodes" SG_ 1323 TireRRTmp 1;
BA_ "SignalLongName" SG_ 1323 TireRFTmpV "Tire Right Front Temperature Validity";
BA_ "SignalType" SG_ 1323 TireRFTmpV "ENM";
BA_ "VNSigAllNodes" SG_ 1323 TireRFTmpV 1;
BA_ "SignalLongName" SG_ 1323 TireRFTmp "Tire Right Front Temperature";
BA_ "SignalType" SG_ 1323 TireRFTmp "UNM";
BA_ "VNSigAllNodes" SG_ 1323 TireRFTmp 1;
BA_ "SignalLongName" SG_ 543 PTOTpStpSpdCsStReq "Power Take Off Tap Step Speed Customization Setting Request";
BA_ "SignalType" SG_ 543 PTOTpStpSpdCsStReq "ENM";
BA_ "VNSigAllNodes" SG_ 543 PTOTpStpSpdCsStReq 1;
BA_ "GenSigSendType" SG_ 543 PTOTpStpSpdCsStReq 10;
BA_ "SignalLongName" SG_ 543 PTOStdbySpdCsStReq "Power Take Off Standby Speed Customization Setting Request";
BA_ "SignalType" SG_ 543 PTOStdbySpdCsStReq "ENM";
BA_ "VNSigAllNodes" SG_ 543 PTOStdbySpdCsStReq 1;
BA_ "GenSigSendType" SG_ 543 PTOStdbySpdCsStReq 10;
BA_ "SignalLongName" SG_ 543 PTOEngRnTmrCsStRq "Power Take Off Engine Run Timer Customization Setting Request";
BA_ "SignalType" SG_ 543 PTOEngRnTmrCsStRq "ENM";
BA_ "VNSigAllNodes" SG_ 543 PTOEngRnTmrCsStRq 1;
BA_ "GenSigSendType" SG_ 543 PTOEngRnTmrCsStRq 10;
BA_ "SignalLongName" SG_ 543 PTOSet2SpdCsStReq "Power Take Off Set 2 Speed Customization Setting Request";
BA_ "SignalType" SG_ 543 PTOSet2SpdCsStReq "ENM";
BA_ "VNSigAllNodes" SG_ 543 PTOSet2SpdCsStReq 1;
BA_ "GenSigSendType" SG_ 543 PTOSet2SpdCsStReq 10;
BA_ "SignalLongName" SG_ 543 PTOSet1SpdCsStReq "Power Take Off Set 1 Speed Customization Setting Request";
BA_ "SignalType" SG_ 543 PTOSet1SpdCsStReq "ENM";
BA_ "VNSigAllNodes" SG_ 543 PTOSet1SpdCsStReq 1;
BA_ "GenSigSendType" SG_ 543 PTOSet1SpdCsStReq 10;
BA_ "SignalLongName" SG_ 313 ExtHlStrAssCsStRq "Extended Hill Start Assist Customization Setting Request";
BA_ "SignalType" SG_ 313 ExtHlStrAssCsStRq "ENM";
BA_ "VNSigAllNodes" SG_ 313 ExtHlStrAssCsStRq 1;
BA_ "GenSigSendType" SG_ 313 ExtHlStrAssCsStRq 10;
BA_ "GenSigSendOnInit" SG_ 313 ExtHlStrAssCsStRq 1;
BA_ "SignalLongName" SG_ 313 DrvStyPerfMdCsStReq "Driving Style Performance Mode Customization Setting Request";
BA_ "SignalType" SG_ 313 DrvStyPerfMdCsStReq "ENM";
BA_ "VNSigAllNodes" SG_ 313 DrvStyPerfMdCsStReq 1;
BA_ "GenSigSendType" SG_ 313 DrvStyPerfMdCsStReq 10;
BA_ "SignalLongName" SG_ 313 PsngStPerfMdCsStReq "Passenger Seat Performance Mode Customization Setting Request";
BA_ "SignalType" SG_ 313 PsngStPerfMdCsStReq "ENM";
BA_ "VNSigAllNodes" SG_ 313 PsngStPerfMdCsStReq 1;
BA_ "GenSigSendType" SG_ 313 PsngStPerfMdCsStReq 10;
BA_ "SignalLongName" SG_ 313 DrvrStPerfMdCsStReq "Driver Seat Performance Mode Customization Setting Request";
BA_ "SignalType" SG_ 313 DrvrStPerfMdCsStReq "ENM";
BA_ "VNSigAllNodes" SG_ 313 DrvrStPerfMdCsStReq 1;
BA_ "GenSigSendType" SG_ 313 DrvrStPerfMdCsStReq 10;
BA_ "SignalLongName" SG_ 313 ACCPerfMdCsStReq "Adaptive Cruise Control Performance Mode Customization Setting Request";
BA_ "SignalType" SG_ 313 ACCPerfMdCsStReq "ENM";
BA_ "VNSigAllNodes" SG_ 313 ACCPerfMdCsStReq 1;
BA_ "GenSigSendType" SG_ 313 ACCPerfMdCsStReq 10;
BA_ "SignalLongName" SG_ 313 PrkAstAdvSysAct "Parking Assistance Advanced  System Active";
BA_ "SignalType" SG_ 313 PrkAstAdvSysAct "BLN";
BA_ "VNSigAllNodes" SG_ 313 PrkAstAdvSysAct 1;
BA_ "GenSigSendType" SG_ 313 PrkAstAdvSysAct 10;
BA_ "SignalLongName" SG_ 313 SndPerfMdCsStRq "Sound Performance Mode Customization Setting Request";
BA_ "SignalType" SG_ 313 SndPerfMdCsStRq "ENM";
BA_ "VNSigAllNodes" SG_ 313 SndPerfMdCsStRq 1;
BA_ "GenSigSendType" SG_ 313 SndPerfMdCsStRq 10;
BA_ "SignalLongName" SG_ 313 HptcStVbnStat "Haptic Seat Vibration Status";
BA_ "SignalType" SG_ 313 HptcStVbnStat "ENM";
BA_ "VNSigAllNodes" SG_ 313 HptcStVbnStat 1;
BA_ "GenSigSendType" SG_ 313 HptcStVbnStat 10;
BA_ "SignalLongName" SG_ 313 ACCSettingType "Adaptive Cruise Control Setting Type";
BA_ "SignalType" SG_ 313 ACCSettingType "ENM";
BA_ "VNSigAllNodes" SG_ 313 ACCSettingType 1;
BA_ "GenSigSendType" SG_ 313 ACCSettingType 10;
BA_ "SignalLongName" SG_ 313 FCABrkPrflReq "Forward Collision Alert Brake Prefill Request";
BA_ "SignalType" SG_ 313 FCABrkPrflReq "BLN";
BA_ "VNSigAllNodes" SG_ 313 FCABrkPrflReq 1;
BA_ "GenSigSendType" SG_ 313 FCABrkPrflReq 10;
BA_ "SignalLongName" SG_ 313 ISA2CCC_ScndCdChr "International Standard Alpha 2 Coded Country Code : Second Code Character";
BA_ "PacketOrder" SG_ 313 ISA2CCC_ScndCdChr 2;
BA_ "SignalType" SG_ 313 ISA2CCC_ScndCdChr "ENM";
BA_ "VNSigAllNodes" SG_ 313 ISA2CCC_ScndCdChr 1;
BA_ "GenSigSendType" SG_ 313 ISA2CCC_ScndCdChr 10;
BA_ "SignalLongName" SG_ 313 ISA2CCC_FrstCdChr "International Standard Alpha 2 Coded Country Code : First Code Character";
BA_ "PacketOrder" SG_ 313 ISA2CCC_FrstCdChr 1;
BA_ "SignalType" SG_ 313 ISA2CCC_FrstCdChr "ENM";
BA_ "VNSigAllNodes" SG_ 313 ISA2CCC_FrstCdChr 1;
BA_ "GenSigSendType" SG_ 313 ISA2CCC_FrstCdChr 10;
BA_ "SignalLongName" SG_ 313 DispPerfMdCsStRq "Display Performance Mode Customization Setting Request";
BA_ "SignalType" SG_ 313 DispPerfMdCsStRq "ENM";
BA_ "VNSigAllNodes" SG_ 313 DispPerfMdCsStRq 1;
BA_ "GenSigSendType" SG_ 313 DispPerfMdCsStRq 10;
BA_ "SignalLongName" SG_ 313 CrshAlrtStPrsnt "Crash Alert Seat Present";
BA_ "SignalType" SG_ 313 CrshAlrtStPrsnt "BLN";
BA_ "VNSigAllNodes" SG_ 313 CrshAlrtStPrsnt 1;
BA_ "GenSigSendType" SG_ 313 CrshAlrtStPrsnt 10;
BA_ "GenSigSendOnInit" SG_ 313 CrshAlrtStPrsnt 1;
BA_ "SignalLongName" SG_ 313 FwdClnAlrtCustStngReq "Forward Collision Alert Customization Setting Request";
BA_ "SignalType" SG_ 313 FwdClnAlrtCustStngReq "ENM";
BA_ "VNSigAllNodes" SG_ 313 FwdClnAlrtCustStngReq 1;
BA_ "GenSigSendType" SG_ 313 FwdClnAlrtCustStngReq 10;
BA_ "GenSigSendOnInit" SG_ 313 FwdClnAlrtCustStngReq 1;
BA_ "SignalLongName" SG_ 313 GNCustStngReq "Go Notifier Customization Setting Request";
BA_ "SignalType" SG_ 313 GNCustStngReq "ENM";
BA_ "VNSigAllNodes" SG_ 313 GNCustStngReq 1;
BA_ "GenSigSendType" SG_ 313 GNCustStngReq 10;
BA_ "GenSigSendOnInit" SG_ 313 GNCustStngReq 1;
BA_ "SignalLongName" SG_ 1328 ACSAlarm9 "Alarm Clock Status : Alarm 9";
BA_ "PacketOrder" SG_ 1328 ACSAlarm9 10;
BA_ "SignalType" SG_ 1328 ACSAlarm9 "ENM";
BA_ "VNSigAllNodes" SG_ 1328 ACSAlarm9 1;
BA_ "GenSigSendType" SG_ 1328 ACSAlarm9 10;
BA_ "SignalLongName" SG_ 1328 ACSAlarm8 "Alarm Clock Status : Alarm 8";
BA_ "PacketOrder" SG_ 1328 ACSAlarm8 9;
BA_ "SignalType" SG_ 1328 ACSAlarm8 "ENM";
BA_ "VNSigAllNodes" SG_ 1328 ACSAlarm8 1;
BA_ "GenSigSendType" SG_ 1328 ACSAlarm8 10;
BA_ "SignalLongName" SG_ 1328 ACSAlarm7 "Alarm Clock Status : Alarm 7";
BA_ "PacketOrder" SG_ 1328 ACSAlarm7 8;
BA_ "SignalType" SG_ 1328 ACSAlarm7 "ENM";
BA_ "VNSigAllNodes" SG_ 1328 ACSAlarm7 1;
BA_ "GenSigSendType" SG_ 1328 ACSAlarm7 10;
BA_ "SignalLongName" SG_ 1328 ACSAlarm6 "Alarm Clock Status : Alarm 6";
BA_ "PacketOrder" SG_ 1328 ACSAlarm6 7;
BA_ "SignalType" SG_ 1328 ACSAlarm6 "ENM";
BA_ "VNSigAllNodes" SG_ 1328 ACSAlarm6 1;
BA_ "GenSigSendType" SG_ 1328 ACSAlarm6 10;
BA_ "SignalLongName" SG_ 1328 ACSAlarm5 "Alarm Clock Status : Alarm 5";
BA_ "PacketOrder" SG_ 1328 ACSAlarm5 6;
BA_ "SignalType" SG_ 1328 ACSAlarm5 "ENM";
BA_ "VNSigAllNodes" SG_ 1328 ACSAlarm5 1;
BA_ "GenSigSendType" SG_ 1328 ACSAlarm5 10;
BA_ "SignalLongName" SG_ 1328 ACSAlarm4 "Alarm Clock Status : Alarm 4";
BA_ "PacketOrder" SG_ 1328 ACSAlarm4 5;
BA_ "SignalType" SG_ 1328 ACSAlarm4 "ENM";
BA_ "VNSigAllNodes" SG_ 1328 ACSAlarm4 1;
BA_ "GenSigSendType" SG_ 1328 ACSAlarm4 10;
BA_ "SignalLongName" SG_ 1328 ACSAlarm3 "Alarm Clock Status : Alarm 3";
BA_ "PacketOrder" SG_ 1328 ACSAlarm3 4;
BA_ "SignalType" SG_ 1328 ACSAlarm3 "ENM";
BA_ "VNSigAllNodes" SG_ 1328 ACSAlarm3 1;
BA_ "GenSigSendType" SG_ 1328 ACSAlarm3 10;
BA_ "SignalLongName" SG_ 1328 ACSAlarm2 "Alarm Clock Status : Alarm 2";
BA_ "PacketOrder" SG_ 1328 ACSAlarm2 3;
BA_ "SignalType" SG_ 1328 ACSAlarm2 "ENM";
BA_ "VNSigAllNodes" SG_ 1328 ACSAlarm2 1;
BA_ "GenSigSendType" SG_ 1328 ACSAlarm2 10;
BA_ "SignalLongName" SG_ 1328 ACSAlarm15 "Alarm Clock Status : Alarm 15";
BA_ "PacketOrder" SG_ 1328 ACSAlarm15 16;
BA_ "SignalType" SG_ 1328 ACSAlarm15 "ENM";
BA_ "VNSigAllNodes" SG_ 1328 ACSAlarm15 1;
BA_ "GenSigSendType" SG_ 1328 ACSAlarm15 10;
BA_ "SignalLongName" SG_ 1328 ACSAlarm14 "Alarm Clock Status : Alarm 14";
BA_ "PacketOrder" SG_ 1328 ACSAlarm14 15;
BA_ "SignalType" SG_ 1328 ACSAlarm14 "ENM";
BA_ "VNSigAllNodes" SG_ 1328 ACSAlarm14 1;
BA_ "GenSigSendType" SG_ 1328 ACSAlarm14 10;
BA_ "SignalLongName" SG_ 1328 ACSAlarm13 "Alarm Clock Status : Alarm 13";
BA_ "PacketOrder" SG_ 1328 ACSAlarm13 14;
BA_ "SignalType" SG_ 1328 ACSAlarm13 "ENM";
BA_ "VNSigAllNodes" SG_ 1328 ACSAlarm13 1;
BA_ "GenSigSendType" SG_ 1328 ACSAlarm13 10;
BA_ "SignalLongName" SG_ 1328 ACSAlarm12 "Alarm Clock Status : Alarm 12";
BA_ "PacketOrder" SG_ 1328 ACSAlarm12 13;
BA_ "SignalType" SG_ 1328 ACSAlarm12 "ENM";
BA_ "VNSigAllNodes" SG_ 1328 ACSAlarm12 1;
BA_ "GenSigSendType" SG_ 1328 ACSAlarm12 10;
BA_ "SignalLongName" SG_ 1328 ACSAlarm11 "Alarm Clock Status : Alarm 11";
BA_ "PacketOrder" SG_ 1328 ACSAlarm11 12;
BA_ "SignalType" SG_ 1328 ACSAlarm11 "ENM";
BA_ "VNSigAllNodes" SG_ 1328 ACSAlarm11 1;
BA_ "GenSigSendType" SG_ 1328 ACSAlarm11 10;
BA_ "SignalLongName" SG_ 1328 ACSAlarm10 "Alarm Clock Status : Alarm 10";
BA_ "PacketOrder" SG_ 1328 ACSAlarm10 11;
BA_ "SignalType" SG_ 1328 ACSAlarm10 "ENM";
BA_ "VNSigAllNodes" SG_ 1328 ACSAlarm10 1;
BA_ "GenSigSendType" SG_ 1328 ACSAlarm10 10;
BA_ "SignalLongName" SG_ 1328 ACSAlarm1 "Alarm Clock Status : Alarm 1";
BA_ "PacketOrder" SG_ 1328 ACSAlarm1 2;
BA_ "SignalType" SG_ 1328 ACSAlarm1 "ENM";
BA_ "VNSigAllNodes" SG_ 1328 ACSAlarm1 1;
BA_ "GenSigSendType" SG_ 1328 ACSAlarm1 10;
BA_ "SignalLongName" SG_ 1328 ACSAlarm0 "Alarm Clock Status : Alarm 0";
BA_ "PacketOrder" SG_ 1328 ACSAlarm0 1;
BA_ "SignalType" SG_ 1328 ACSAlarm0 "ENM";
BA_ "VNSigAllNodes" SG_ 1328 ACSAlarm0 1;
BA_ "GenSigSendType" SG_ 1328 ACSAlarm0 10;
BA_ "SignalLongName" SG_ 311 PsngSysDilPrcs "Positioning System Dilution of Precision";
BA_ "SignalType" SG_ 311 PsngSysDilPrcs "UNM";
BA_ "VNSigAllNodes" SG_ 311 PsngSysDilPrcs 1;
BA_ "GenSigDeltaValue" SG_ 311 PsngSysDilPrcs 10;
BA_ "GenSigSendType" SG_ 311 PsngSysDilPrcs 12;
BA_ "SignalLongName" SG_ 311 Hrs "Hours";
BA_ "SignalType" SG_ 311 Hrs "UNM";
BA_ "VNSigAllNodes" SG_ 311 Hrs 1;
BA_ "GenSigDeltaValue" SG_ 311 Hrs 1;
BA_ "GenSigSendType" SG_ 311 Hrs 12;
BA_ "GenSigSendOnInit" SG_ 311 Hrs 1;
BA_ "SignalLongName" SG_ 311 PsngSysHding "Positioning System Heading";
BA_ "SignalType" SG_ 311 PsngSysHding "UNM";
BA_ "VNSigAllNodes" SG_ 311 PsngSysHding 1;
BA_ "GenSigDeltaValue" SG_ 311 PsngSysHding 50;
BA_ "GenSigSendType" SG_ 311 PsngSysHding 12;
BA_ "SignalLongName" SG_ 311 PsngSysElvtn "Positioning System Elevation";
BA_ "SignalType" SG_ 311 PsngSysElvtn "UNM";
BA_ "VNSigAllNodes" SG_ 311 PsngSysElvtn 1;
BA_ "GenSigDeltaValue" SG_ 311 PsngSysElvtn 100;
BA_ "GenSigSendType" SG_ 311 PsngSysElvtn 12;
BA_ "SignalLongName" SG_ 311 PsngSysHdingV "Positioning System Heading Validity";
BA_ "SignalType" SG_ 311 PsngSysHdingV "ENM";
BA_ "VNSigAllNodes" SG_ 311 PsngSysHdingV 1;
BA_ "GenSigSendType" SG_ 311 PsngSysHdingV 10;
BA_ "SignalLongName" SG_ 311 HrsV "Hours Validity";
BA_ "SignalType" SG_ 311 HrsV "ENM";
BA_ "VNSigAllNodes" SG_ 311 HrsV 1;
BA_ "GenSigSendType" SG_ 311 HrsV 10;
BA_ "GenSigSendOnInit" SG_ 311 HrsV 1;
BA_ "SignalLongName" SG_ 311 MinsV "Minutes Validity";
BA_ "SignalType" SG_ 311 MinsV "ENM";
BA_ "VNSigAllNodes" SG_ 311 MinsV 1;
BA_ "GenSigSendType" SG_ 311 MinsV 10;
BA_ "GenSigSendOnInit" SG_ 311 MinsV 1;
BA_ "SignalLongName" SG_ 311 Mins "Minutes";
BA_ "SignalType" SG_ 311 Mins "UNM";
BA_ "VNSigAllNodes" SG_ 311 Mins 1;
BA_ "GenSigDeltaValue" SG_ 311 Mins 1;
BA_ "GenSigSendType" SG_ 311 Mins 12;
BA_ "GenSigSendOnInit" SG_ 311 Mins 1;
BA_ "SignalLongName" SG_ 311 PsngSysDilPrcsV "Positioning System Dilution of Precision Validity";
BA_ "SignalType" SG_ 311 PsngSysDilPrcsV "ENM";
BA_ "VNSigAllNodes" SG_ 311 PsngSysDilPrcsV 1;
BA_ "GenSigSendType" SG_ 311 PsngSysDilPrcsV 10;
BA_ "SignalLongName" SG_ 311 PsngSysElvtnV "Positioning System Elevation Validity";
BA_ "SignalType" SG_ 311 PsngSysElvtnV "ENM";
BA_ "VNSigAllNodes" SG_ 311 PsngSysElvtnV 1;
BA_ "GenSigSendType" SG_ 311 PsngSysElvtnV 10;
BA_ "SignalLongName" SG_ 311 VehSpeSta "Vehicle Speed State";
BA_ "SignalType" SG_ 311 VehSpeSta "ENM";
BA_ "VNSigAllNodes" SG_ 311 VehSpeSta 1;
BA_ "SignalLongName" SG_ 810 PsngSysLongV "Positioning System Longitude Validity";
BA_ "SignalType" SG_ 810 PsngSysLongV "ENM";
BA_ "VNSigAllNodes" SG_ 810 PsngSysLongV 1;
BA_ "GenSigSendType" SG_ 810 PsngSysLongV 10;
BA_ "SignalLongName" SG_ 810 PsngSysLong "Positioning System Longitude";
BA_ "SignalType" SG_ 810 PsngSysLong "SNM";
BA_ "VNSigAllNodes" SG_ 810 PsngSysLong 1;
BA_ "GenSigDeltaValue" SG_ 810 PsngSysLong 10;
BA_ "GenSigSendType" SG_ 810 PsngSysLong 12;
BA_ "SignalLongName" SG_ 810 PsngSysLatV "Positioning System Latitude Validity";
BA_ "SignalType" SG_ 810 PsngSysLatV "ENM";
BA_ "VNSigAllNodes" SG_ 810 PsngSysLatV 1;
BA_ "GenSigSendType" SG_ 810 PsngSysLatV 10;
BA_ "SignalLongName" SG_ 810 PsngSysLat "Positioning System Latitude";
BA_ "SignalType" SG_ 810 PsngSysLat "SNM";
BA_ "VNSigAllNodes" SG_ 810 PsngSysLat 1;
BA_ "GenSigDeltaValue" SG_ 810 PsngSysLat 10;
BA_ "GenSigSendType" SG_ 810 PsngSysLat 12;
BA_ "GenSigSendOnInit" SG_ 810 PsngSysLat 2;
BA_ "SignalLongName" SG_ 304 PedFrndlyAlrtCsStReq "Pedestrian Friendly Alert Customization Setting Request";
BA_ "SignalType" SG_ 304 PedFrndlyAlrtCsStReq "ENM";
BA_ "VNSigAllNodes" SG_ 304 PedFrndlyAlrtCsStReq 1;
BA_ "GenSigSendType" SG_ 304 PedFrndlyAlrtCsStReq 10;
BA_ "SignalLongName" SG_ 304 AlrmStat "Alarm Status";
BA_ "SignalType" SG_ 304 AlrmStat "ENM";
BA_ "VNSigAllNodes" SG_ 304 AlrmStat 1;
BA_ "GenSigSendType" SG_ 304 AlrmStat 10;
BA_ "GenSigSendOnInit" SG_ 304 AlrmStat 2;
BA_ "SignalLongName" SG_ 1345 DgnInf_HS541 "Diagnostic Information HS541";
BA_ "SignalType" SG_ 1345 DgnInf_HS541 "UNM";
BA_ "VNSigAllNodes" SG_ 1345 DgnInf_HS541 1;
BA_ "VNSigSLHSSharedDiagnostic" SG_ 1345 DgnInf_HS541 1;
BA_ "SignalLongName" SG_ 322 AFLGPSCstStReq "Adaptive Forward Lighting With GPS Customization Setting Request";
BA_ "SignalType" SG_ 322 AFLGPSCstStReq "ENM";
BA_ "VNSigAllNodes" SG_ 322 AFLGPSCstStReq 1;
BA_ "GenSigSendType" SG_ 322 AFLGPSCstStReq 10;
BA_ "SignalLongName" SG_ 322 AFLCstStReq "Adaptive Forward Lighting Customization Setting Request";
BA_ "SignalType" SG_ 322 AFLCstStReq "ENM";
BA_ "VNSigAllNodes" SG_ 322 AFLCstStReq 1;
BA_ "GenSigSendType" SG_ 322 AFLCstStReq 10;
BA_ "SignalLongName" SG_ 322 LtRtHnTrCstStReq "Left Right Hand Traffic Customization Setting Request";
BA_ "SignalType" SG_ 322 LtRtHnTrCstStReq "ENM";
BA_ "VNSigAllNodes" SG_ 322 LtRtHnTrCstStReq 1;
BA_ "GenSigSendType" SG_ 322 LtRtHnTrCstStReq 10;
BA_ "SignalLongName" SG_ 322 AdpHgBmAsSnCsStRq "Adaptive High Beam Assist With Sensitivity Customization Setting Request";
BA_ "SignalType" SG_ 322 AdpHgBmAsSnCsStRq "ENM";
BA_ "VNSigAllNodes" SG_ 322 AdpHgBmAsSnCsStRq 1;
BA_ "GenSigSendType" SG_ 322 AdpHgBmAsSnCsStRq 10;
BA_ "SignalLongName" SG_ 322 AdpHgBmAstCstStRq "Adaptive High Beam Assist Customization Setting Request";
BA_ "SignalType" SG_ 322 AdpHgBmAstCstStRq "ENM";
BA_ "VNSigAllNodes" SG_ 322 AdpHgBmAstCstStRq 1;
BA_ "GenSigSendType" SG_ 322 AdpHgBmAstCstStRq 10;
BA_ "SignalLongName" SG_ 322 LtRtHnTrGPSCstStRq "Left Right Hand Traffic With GPS Customization Setting Request";
BA_ "SignalType" SG_ 322 LtRtHnTrGPSCstStRq "ENM";
BA_ "VNSigAllNodes" SG_ 322 LtRtHnTrGPSCstStRq 1;
BA_ "GenSigSendType" SG_ 322 LtRtHnTrGPSCstStRq 10;
BA_ "SignalLongName" SG_ 322 AutHgBmAsSnCsStRq "Auto High Beam Assist With Sensitivity Customization Setting Request";
BA_ "SignalType" SG_ 322 AutHgBmAsSnCsStRq "ENM";
BA_ "VNSigAllNodes" SG_ 322 AutHgBmAsSnCsStRq 1;
BA_ "GenSigSendType" SG_ 322 AutHgBmAsSnCsStRq 10;
BA_ "SignalLongName" SG_ 322 AutHgBmAstCstStRq "Auto High Beam Assist Customization Setting Request";
BA_ "SignalType" SG_ 322 AutHgBmAstCstStRq "ENM";
BA_ "VNSigAllNodes" SG_ 322 AutHgBmAstCstStRq 1;
BA_ "GenSigSendType" SG_ 322 AutHgBmAstCstStRq 10;
BA_ "SignalLongName" SG_ 309 StBltTgtCSRq "Seat Belt Tightening Customize Setting Request";
BA_ "SignalType" SG_ 309 StBltTgtCSRq "ENM";
BA_ "VNSigAllNodes" SG_ 309 StBltTgtCSRq 1;
BA_ "GenSigSendType" SG_ 309 StBltTgtCSRq 10;
BA_ "GenSigSendOnInit" SG_ 309 StBltTgtCSRq 1;
BA_ "SignalLongName" SG_ 309 ColPrSysCustReq "Collision Preparation System Customization Setting Request";
BA_ "SignalType" SG_ 309 ColPrSysCustReq "ENM";
BA_ "VNSigAllNodes" SG_ 309 ColPrSysCustReq 1;
BA_ "GenSigSendType" SG_ 309 ColPrSysCustReq 10;
BA_ "GenSigSendOnInit" SG_ 309 ColPrSysCustReq 1;
BA_ "SignalLongName" SG_ 309 SecV "Seconds Validity";
BA_ "SignalType" SG_ 309 SecV "ENM";
BA_ "VNSigAllNodes" SG_ 309 SecV 1;
BA_ "GenSigSendType" SG_ 309 SecV 10;
BA_ "GenSigSendOnInit" SG_ 309 SecV 1;
BA_ "SignalLongName" SG_ 309 Sec "Seconds";
BA_ "SignalType" SG_ 309 Sec "UNM";
BA_ "VNSigAllNodes" SG_ 309 Sec 1;
BA_ "GenSigDeltaValue" SG_ 309 Sec 1;
BA_ "GenSigSendType" SG_ 309 Sec 12;
BA_ "GenSigSendOnInit" SG_ 309 Sec 1;
BA_ "SignalLongName" SG_ 309 CldrYr_154 "Calendar Year";
BA_ "SignalType" SG_ 309 CldrYr_154 "UNM";
BA_ "VNSigAllNodes" SG_ 309 CldrYr_154 1;
BA_ "GenSigDeltaValue" SG_ 309 CldrYr_154 1;
BA_ "GenSigSendType" SG_ 309 CldrYr_154 12;
BA_ "GenSigSendOnInit" SG_ 309 CldrYr_154 1;
BA_ "SignalLongName" SG_ 309 CldrYr "Calendar Year";
BA_ "SignalType" SG_ 309 CldrYr "UNM";
BA_ "VNSigAllNodes" SG_ 309 CldrYr 1;
BA_ "GenSigDeltaValue" SG_ 309 CldrYr 1;
BA_ "GenSigSendType" SG_ 309 CldrYr 12;
BA_ "GenSigSendOnInit" SG_ 309 CldrYr 1;
BA_ "SignalLongName" SG_ 309 CldrMth_154 "Calendar Month";
BA_ "SignalType" SG_ 309 CldrMth_154 "ENM";
BA_ "VNSigAllNodes" SG_ 309 CldrMth_154 1;
BA_ "GenSigSendType" SG_ 309 CldrMth_154 10;
BA_ "GenSigSendOnInit" SG_ 309 CldrMth_154 1;
BA_ "SignalLongName" SG_ 309 CldrMth "Calendar Month";
BA_ "SignalType" SG_ 309 CldrMth "ENM";
BA_ "VNSigAllNodes" SG_ 309 CldrMth 1;
BA_ "GenSigSendType" SG_ 309 CldrMth 10;
BA_ "GenSigSendOnInit" SG_ 309 CldrMth 1;
BA_ "SignalLongName" SG_ 309 CldrDay_154 "Calendar Day";
BA_ "SignalType" SG_ 309 CldrDay_154 "UNM";
BA_ "VNSigAllNodes" SG_ 309 CldrDay_154 1;
BA_ "GenSigDeltaValue" SG_ 309 CldrDay_154 1;
BA_ "GenSigSendType" SG_ 309 CldrDay_154 12;
BA_ "GenSigSendOnInit" SG_ 309 CldrDay_154 1;
BA_ "SignalLongName" SG_ 309 CldrDay "Calendar Day";
BA_ "SignalType" SG_ 309 CldrDay "UNM";
BA_ "VNSigAllNodes" SG_ 309 CldrDay 1;
BA_ "GenSigDeltaValue" SG_ 309 CldrDay 1;
BA_ "GenSigSendType" SG_ 309 CldrDay 12;
BA_ "GenSigSendOnInit" SG_ 309 CldrDay 1;
BA_ "SignalLongName" SG_ 309 PedFrndlyAlrtSndMnAct "Pedestrian Friendly Alert Sound Manual Activation";
BA_ "SignalType" SG_ 309 PedFrndlyAlrtSndMnAct "BLN";
BA_ "VNSigAllNodes" SG_ 309 PedFrndlyAlrtSndMnAct 1;
BA_ "GenSigStartValue" SG_ 309 AutoHiBmVDA 1;
BA_ "SignalLongName" SG_ 309 AutoHiBmVDA "Automatic High Beam Virtual Device Availability";
BA_ "SignalType" SG_ 309 AutoHiBmVDA "ENM";
BA_ "VNSigAllNodes" SG_ 309 AutoHiBmVDA 1;
BA_ "SignalLongName" SG_ 309 CtLghtDet "City Light Detected";
BA_ "SignalType" SG_ 309 CtLghtDet "BLN";
BA_ "VNSigAllNodes" SG_ 309 CtLghtDet 1;
BA_ "GenSigSendType" SG_ 309 CtLghtDet 10;
BA_ "GenSigSendOnInit" SG_ 309 CtLghtDet 2;
BA_ "GenSigStartValue" SG_ 309 RrClosVDA 1;
BA_ "SignalLongName" SG_ 309 RrClosVDA "Rear Closure Virtual Device Availability";
BA_ "SignalType" SG_ 309 RrClosVDA "ENM";
BA_ "VNSigAllNodes" SG_ 309 RrClosVDA 1;
BA_ "SignalLongName" SG_ 309 TCSysDisSwAtv "Traction Control System Disable Switch Active";
BA_ "SignalType" SG_ 309 TCSysDisSwAtv "BLN";
BA_ "VNSigAllNodes" SG_ 309 TCSysDisSwAtv 1;
BA_ "SignalLongName" SG_ 309 VehMovState "Vehicle Movement State";
BA_ "SignalType" SG_ 309 VehMovState "ENM";
BA_ "VNSigAllNodes" SG_ 309 VehMovState 1;
BA_ "GenSigSendType" SG_ 309 VehMovState 10;
BA_ "GenSigSendOnInit" SG_ 309 VehMovState 1;
BA_ "SignalLongName" SG_ 309 TCSysDisSwAtvV "Traction Control System Disable Switch Active Validity";
BA_ "SignalType" SG_ 309 TCSysDisSwAtvV "ENM";
BA_ "VNSigAllNodes" SG_ 309 TCSysDisSwAtvV 1;
BA_ "SignalLongName" SG_ 309 HillDesCtrlMdSwActV "Hill Descent Control Mode Switch Active Validity";
BA_ "SignalType" SG_ 309 HillDesCtrlMdSwActV "ENM";
BA_ "VNSigAllNodes" SG_ 309 HillDesCtrlMdSwActV 1;
BA_ "SignalLongName" SG_ 309 WSWshSwAtv "Windshield Washer Switch Active";
BA_ "SignalType" SG_ 309 WSWshSwAtv "BLN";
BA_ "VNSigAllNodes" SG_ 309 WSWshSwAtv 1;
BA_ "SignalLongName" SG_ 309 HillDesCtrlMdSwAct "Hill Descent Control Mode Switch Active";
BA_ "SignalType" SG_ 309 HillDesCtrlMdSwAct "BLN";
BA_ "VNSigAllNodes" SG_ 309 HillDesCtrlMdSwAct 1;
BA_ "SignalLongName" SG_ 309 RrClosAjarSwAct "Rear Closure Ajar Switch Active";
BA_ "SignalType" SG_ 309 RrClosAjarSwAct "BLN";
BA_ "VNSigAllNodes" SG_ 309 RrClosAjarSwAct 1;
BA_ "GenSigSendType" SG_ 309 RrClosAjarSwAct 10;
BA_ "GenSigSendOnInit" SG_ 309 RrClosAjarSwAct 1;
BA_ "SignalLongName" SG_ 309 WSWprAct "Windshield Wiper Active";
BA_ "SignalType" SG_ 309 WSWprAct "BLN";
BA_ "VNSigAllNodes" SG_ 309 WSWprAct 1;
BA_ "GenSigSendType" SG_ 309 WSWprAct 10;
BA_ "SignalLongName" SG_ 352 AVHSwtchStats "Auto Vehicle Hold Switch Status";
BA_ "SignalType" SG_ 352 AVHSwtchStats "ENM";
BA_ "VNSigAllNodes" SG_ 352 AVHSwtchStats 1;
BA_ "SignalLongName" SG_ 352 TeenDrvAct "Teen Driver Active";
BA_ "SignalType" SG_ 352 TeenDrvAct "BLN";
BA_ "VNSigAllNodes" SG_ 352 TeenDrvAct 1;
BA_ "GenSigSendType" SG_ 352 TeenDrvAct 10;
BA_ "GenSigSendOnInit" SG_ 352 TeenDrvAct 2;
BA_ "SignalLongName" SG_ 352 LrnEnvIdSt "Learn Environment Identification Status";
BA_ "SignalType" SG_ 352 LrnEnvIdSt "ENM";
BA_ "VNSigAllNodes" SG_ 352 LrnEnvIdSt 1;
BA_ "GenSigSendOnInit" SG_ 352 LrnEnvIdSt 2;
BA_ "SignalLongName" SG_ 352 LrnEnvId "Learn Environment Identification";
BA_ "SignalType" SG_ 352 LrnEnvId "UNM";
BA_ "VNSigAllNodes" SG_ 352 LrnEnvId 1;
BA_ "GenSigSendOnInit" SG_ 352 LrnEnvId 2;
BA_ "SignalLongName" SG_ 352 ImoId "Immobilizer Identifier";
BA_ "SignalType" SG_ 352 ImoId "UNM";
BA_ "VNSigAllNodes" SG_ 352 ImoId 1;
BA_ "GenSigSendOnInit" SG_ 352 ImoId 2;
BA_ "SignalLongName" SG_ 352 ImoIdSt "Immobilizer Identifier Status";
BA_ "SignalType" SG_ 352 ImoIdSt "ENM";
BA_ "VNSigAllNodes" SG_ 352 ImoIdSt 1;
BA_ "GenSigSendOnInit" SG_ 352 ImoIdSt 2;
BA_ "SignalLongName" SG_ 2041 PCUInfo_7F9 "Pyrotechnical Control Unit Information 7F9";
BA_ "SignalType" SG_ 2041 PCUInfo_7F9 "UNM";
BA_ "VNSigAllNodes" SG_ 2041 PCUInfo_7F9 1;
BA_ "GenSigDeltaValue" SG_ 2041 PCUInfo_7F9 1;
BA_ "GenSigSendType" SG_ 2041 PCUInfo_7F9 12;
BA_ "SignalLongName" SG_ 1322 TireRRPrsV "Tire Right Rear Pressure Validity";
BA_ "SignalType" SG_ 1322 TireRRPrsV "ENM";
BA_ "VNSigAllNodes" SG_ 1322 TireRRPrsV 1;
BA_ "GenSigSendType" SG_ 1322 TireRRPrsV 10;
BA_ "GenSigSendOnInit" SG_ 1322 TireRRPrsV 1;
BA_ "SignalLongName" SG_ 1322 TireRRPrsStat "Tire Right Rear Pressure Status";
BA_ "SignalType" SG_ 1322 TireRRPrsStat "ENM";
BA_ "VNSigAllNodes" SG_ 1322 TireRRPrsStat 1;
BA_ "GenSigSendType" SG_ 1322 TireRRPrsStat 10;
BA_ "GenSigSendOnInit" SG_ 1322 TireRRPrsStat 1;
BA_ "GenSigStartValue" SG_ 1322 TireRRPrs 255;
BA_ "SignalLongName" SG_ 1322 TireRRPrs "Tire Right Rear Pressure";
BA_ "SignalType" SG_ 1322 TireRRPrs "UNM";
BA_ "VNSigAllNodes" SG_ 1322 TireRRPrs 1;
BA_ "GenSigDeltaValue" SG_ 1322 TireRRPrs 1;
BA_ "GenSigSendType" SG_ 1322 TireRRPrs 12;
BA_ "GenSigSendOnInit" SG_ 1322 TireRRPrs 1;
BA_ "SignalLongName" SG_ 1322 TireRFPrsV "Tire Right Front Pressure Validity";
BA_ "SignalType" SG_ 1322 TireRFPrsV "ENM";
BA_ "VNSigAllNodes" SG_ 1322 TireRFPrsV 1;
BA_ "GenSigSendType" SG_ 1322 TireRFPrsV 10;
BA_ "GenSigSendOnInit" SG_ 1322 TireRFPrsV 1;
BA_ "SignalLongName" SG_ 1322 TireRFPrsStat "Tire Right Front Pressure Status";
BA_ "SignalType" SG_ 1322 TireRFPrsStat "ENM";
BA_ "VNSigAllNodes" SG_ 1322 TireRFPrsStat 1;
BA_ "GenSigSendType" SG_ 1322 TireRFPrsStat 10;
BA_ "GenSigSendOnInit" SG_ 1322 TireRFPrsStat 1;
BA_ "GenSigStartValue" SG_ 1322 TireRFPrs 255;
BA_ "SignalLongName" SG_ 1322 TireRFPrs "Tire Right Front Pressure";
BA_ "SignalType" SG_ 1322 TireRFPrs "UNM";
BA_ "VNSigAllNodes" SG_ 1322 TireRFPrs 1;
BA_ "GenSigDeltaValue" SG_ 1322 TireRFPrs 1;
BA_ "GenSigSendType" SG_ 1322 TireRFPrs 12;
BA_ "GenSigSendOnInit" SG_ 1322 TireRFPrs 1;
BA_ "SignalLongName" SG_ 1322 TireLRPrsV "Tire Left Rear Pressure Validity";
BA_ "SignalType" SG_ 1322 TireLRPrsV "ENM";
BA_ "VNSigAllNodes" SG_ 1322 TireLRPrsV 1;
BA_ "GenSigSendType" SG_ 1322 TireLRPrsV 10;
BA_ "GenSigSendOnInit" SG_ 1322 TireLRPrsV 1;
BA_ "SignalLongName" SG_ 1322 TireLRPrsStat "Tire Left Rear Pressure Status";
BA_ "SignalType" SG_ 1322 TireLRPrsStat "ENM";
BA_ "VNSigAllNodes" SG_ 1322 TireLRPrsStat 1;
BA_ "GenSigSendType" SG_ 1322 TireLRPrsStat 10;
BA_ "GenSigSendOnInit" SG_ 1322 TireLRPrsStat 1;
BA_ "GenSigStartValue" SG_ 1322 TireLRPrs 255;
BA_ "SignalLongName" SG_ 1322 TireLRPrs "Tire Left Rear Pressure";
BA_ "SignalType" SG_ 1322 TireLRPrs "UNM";
BA_ "VNSigAllNodes" SG_ 1322 TireLRPrs 1;
BA_ "GenSigDeltaValue" SG_ 1322 TireLRPrs 1;
BA_ "GenSigSendType" SG_ 1322 TireLRPrs 12;
BA_ "GenSigSendOnInit" SG_ 1322 TireLRPrs 1;
BA_ "SignalLongName" SG_ 1322 TireLFPrsV "Tire Left Front Pressure Validity";
BA_ "SignalType" SG_ 1322 TireLFPrsV "ENM";
BA_ "VNSigAllNodes" SG_ 1322 TireLFPrsV 1;
BA_ "GenSigSendType" SG_ 1322 TireLFPrsV 10;
BA_ "GenSigSendOnInit" SG_ 1322 TireLFPrsV 1;
BA_ "SignalLongName" SG_ 1322 TireLFPrsStat "Tire Left Front Pressure Status";
BA_ "SignalType" SG_ 1322 TireLFPrsStat "ENM";
BA_ "VNSigAllNodes" SG_ 1322 TireLFPrsStat 1;
BA_ "GenSigSendType" SG_ 1322 TireLFPrsStat 10;
BA_ "GenSigSendOnInit" SG_ 1322 TireLFPrsStat 1;
BA_ "GenSigStartValue" SG_ 1322 TireLFPrs 255;
BA_ "SignalLongName" SG_ 1322 TireLFPrs "Tire Left Front Pressure";
BA_ "SignalType" SG_ 1322 TireLFPrs "UNM";
BA_ "VNSigAllNodes" SG_ 1322 TireLFPrs 1;
BA_ "GenSigDeltaValue" SG_ 1322 TireLFPrs 1;
BA_ "GenSigSendType" SG_ 1322 TireLFPrs 12;
BA_ "GenSigSendOnInit" SG_ 1322 TireLFPrs 1;
BA_ "SignalLongName" SG_ 1601 DgnInf "Diagnostic Information";
BA_ "SignalType" SG_ 1601 DgnInf "UNM";
BA_ "VNSigAllNodes" SG_ 1601 DgnInf 1;
BA_ "VNSigSLHSSharedDiagnostic" SG_ 1601 DgnInf 1;
BA_ "SignalLongName" SG_ 1300 VehIdNmDig2_9 "Vehicle Identification Number Digits 2-9";
BA_ "SignalType" SG_ 1300 VehIdNmDig2_9 "ASC";
BA_ "VNSigAllNodes" SG_ 1300 VehIdNmDig2_9 1;
BA_ "GenSigSendOnInit" SG_ 1300 VehIdNmDig2_9 2;
BA_ "SignalLongName" SG_ 288 VehOdo "Vehicle Odometer";
BA_ "SignalType" SG_ 288 VehOdo "UNM";
BA_ "VNSigAllNodes" SG_ 288 VehOdo 1;
BA_ "SignalLongName" SG_ 288 VehOdoV "Vehicle Odometer Validity";
BA_ "SignalType" SG_ 288 VehOdoV "ENM";
BA_ "VNSigAllNodes" SG_ 288 VehOdoV 1;
BA_ "GenSigStartValue" SG_ 208 WhlSlipRRWhl 32768;
BA_ "SignalLongName" SG_ 208 WhlSlipRRWhl "Wheel Slip Right Rear Wheel";
BA_ "SignalType" SG_ 208 WhlSlipRRWhl "UNM";
BA_ "VNSigAllNodes" SG_ 208 WhlSlipRRWhl 1;
BA_ "GenSigStartValue" SG_ 208 WhlSlipRFWhl 32768;
BA_ "SignalLongName" SG_ 208 WhlSlipRFWhl "Wheel Slip Right Front Wheel";
BA_ "SignalType" SG_ 208 WhlSlipRFWhl "UNM";
BA_ "VNSigAllNodes" SG_ 208 WhlSlipRFWhl 1;
BA_ "GenSigStartValue" SG_ 208 WhlSlipLRWhl 32768;
BA_ "SignalLongName" SG_ 208 WhlSlipLRWhl "Wheel Slip Left Rear Wheel";
BA_ "SignalType" SG_ 208 WhlSlipLRWhl "UNM";
BA_ "VNSigAllNodes" SG_ 208 WhlSlipLRWhl 1;
BA_ "GenSigStartValue" SG_ 208 WhlSlipLFWhl 32768;
BA_ "SignalLongName" SG_ 208 WhlSlipLFWhl "Wheel Slip Left Front Wheel";
BA_ "SignalType" SG_ 208 WhlSlipLFWhl "UNM";
BA_ "VNSigAllNodes" SG_ 208 WhlSlipLFWhl 1;
BA_ "SignalLongName" SG_ 1247 RrPTCoolFanStatV "Rear Powertrain Cooling Fan Status Validity";
BA_ "SignalType" SG_ 1247 RrPTCoolFanStatV "ENM";
BA_ "VNSigAllNodes" SG_ 1247 RrPTCoolFanStatV 1;
BA_ "SignalLongName" SG_ 1247 RrPTCoolFanStat "Rear Powertrain Cooling Fan Status";
BA_ "SignalType" SG_ 1247 RrPTCoolFanStat "ENM";
BA_ "VNSigAllNodes" SG_ 1247 RrPTCoolFanStat 1;
BA_ "SignalLongName" SG_ 1247 RrPTCoolFanSpPctCmd "Rear Powertrain Cooling Fan Speed Percent Commanded";
BA_ "SignalType" SG_ 1247 RrPTCoolFanSpPctCmd "UNM";
BA_ "VNSigAllNodes" SG_ 1247 RrPTCoolFanSpPctCmd 1;
BA_ "SignalLongName" SG_ 389 StrAngSnsPolRat "Steering Angle Sensor Polarity Rationality";
BA_ "SignalType" SG_ 389 StrAngSnsPolRat "ENM";
BA_ "VNSigAllNodes" SG_ 389 StrAngSnsPolRat 1;
BA_ "SignalLongName" SG_ 389 LatAccSnsPolRat "Lateral Acceleration Sensor Polarity Rationality";
BA_ "SignalType" SG_ 389 LatAccSnsPolRat "ENM";
BA_ "VNSigAllNodes" SG_ 389 LatAccSnsPolRat 1;
BA_ "SignalLongName" SG_ 389 VSELongAccLoResV "Vehicle Stability Enhancement Longitudinal Acceleration Low Resolution Validity";
BA_ "SignalType" SG_ 389 VSELongAccLoResV "ENM";
BA_ "VNSigAllNodes" SG_ 389 VSELongAccLoResV 1;
BA_ "SignalLongName" SG_ 389 VSELongAccLoRes "Vehicle Stability Enhancement Longitudinal Acceleration Low Resolution";
BA_ "SignalType" SG_ 389 VSELongAccLoRes "SNM";
BA_ "VNSigAllNodes" SG_ 389 VSELongAccLoRes 1;
BA_ "SignalLongName" SG_ 2018 DgnInf "Diagnostic Information";
BA_ "SignalType" SG_ 2018 DgnInf "UNM";
BA_ "VNSigAllNodes" SG_ 2018 DgnInf 1;
BA_ "VNSigSLHSSharedDiagnostic" SG_ 2018 DgnInf 1;
BA_ "SignalLongName" SG_ 1013 Sig1889 "Signal1889";
BA_ "SignalType" SG_ 1013 Sig1889 "ENM";
BA_ "VNSigAllNodes" SG_ 1013 Sig1889 1;
BA_ "SignalLongName" SG_ 1013 Sig1888 "Signal1888";
BA_ "SignalType" SG_ 1013 Sig1888 "ENM";
BA_ "VNSigAllNodes" SG_ 1013 Sig1888 1;
BA_ "SignalLongName" SG_ 425 TransClch5FlTm "Transmission Clutch 5 Fill Time";
BA_ "SignalType" SG_ 425 TransClch5FlTm "UNM";
BA_ "VNSigAllNodes" SG_ 425 TransClch5FlTm 1;
BA_ "SignalLongName" SG_ 425 TransCltch5EstTrq "Transmission Clutch 5 Estimated Torque";
BA_ "SignalType" SG_ 425 TransCltch5EstTrq "UNM";
BA_ "VNSigAllNodes" SG_ 425 TransCltch5EstTrq 1;
BA_ "SignalLongName" SG_ 425 TransClch5MaxEngy "Transmission Clutch 5 Maximum Energy";
BA_ "SignalType" SG_ 425 TransClch5MaxEngy "UNM";
BA_ "VNSigAllNodes" SG_ 425 TransClch5MaxEngy 1;
BA_ "SignalLongName" SG_ 425 TransClch5FlAch "Transmission Clutch 5 Fill Achieved";
BA_ "SignalType" SG_ 425 TransClch5FlAch "BLN";
BA_ "VNSigAllNodes" SG_ 425 TransClch5FlAch 1;
BA_ "SignalLongName" SG_ 425 TransClch4FlTm "Transmission Clutch 4 Fill Time";
BA_ "SignalType" SG_ 425 TransClch4FlTm "UNM";
BA_ "VNSigAllNodes" SG_ 425 TransClch4FlTm 1;
BA_ "SignalLongName" SG_ 425 TransClch4EstTorq "Transmission Clutch 4 Estimated Torque";
BA_ "SignalType" SG_ 425 TransClch4EstTorq "UNM";
BA_ "VNSigAllNodes" SG_ 425 TransClch4EstTorq 1;
BA_ "SignalLongName" SG_ 425 TransClch4MaxEnrgy "Transmission Clutch 4 Maximum Energy";
BA_ "SignalType" SG_ 425 TransClch4MaxEnrgy "UNM";
BA_ "VNSigAllNodes" SG_ 425 TransClch4MaxEnrgy 1;
BA_ "SignalLongName" SG_ 425 TransClch4FlAch "Transmission Clutch 4 Fill Achieved";
BA_ "SignalType" SG_ 425 TransClch4FlAch "BLN";
BA_ "VNSigAllNodes" SG_ 425 TransClch4FlAch 1;
BA_ "SignalLongName" SG_ 424 TransClch3FlTm "Transmission Clutch 3 Fill Time";
BA_ "SignalType" SG_ 424 TransClch3FlTm "UNM";
BA_ "VNSigAllNodes" SG_ 424 TransClch3FlTm 1;
BA_ "SignalLongName" SG_ 424 TransClch3EstTorq "Transmission Clutch 3 Estimated Torque";
BA_ "SignalType" SG_ 424 TransClch3EstTorq "UNM";
BA_ "VNSigAllNodes" SG_ 424 TransClch3EstTorq 1;
BA_ "SignalLongName" SG_ 424 TransClch3MaxEnrgy "Transmission Clutch 3 Maximum Energy";
BA_ "SignalType" SG_ 424 TransClch3MaxEnrgy "UNM";
BA_ "VNSigAllNodes" SG_ 424 TransClch3MaxEnrgy 1;
BA_ "SignalLongName" SG_ 424 TransClch3FlAch "Transmission Clutch 3 Fill Achieved";
BA_ "SignalType" SG_ 424 TransClch3FlAch "BLN";
BA_ "VNSigAllNodes" SG_ 424 TransClch3FlAch 1;
BA_ "SignalLongName" SG_ 424 TransClch2FlTm "Transmission Clutch 2 Fill Time";
BA_ "SignalType" SG_ 424 TransClch2FlTm "UNM";
BA_ "VNSigAllNodes" SG_ 424 TransClch2FlTm 1;
BA_ "SignalLongName" SG_ 424 TransClch2EstTorq "Transmission Clutch 2 Estimated Torque";
BA_ "SignalType" SG_ 424 TransClch2EstTorq "UNM";
BA_ "VNSigAllNodes" SG_ 424 TransClch2EstTorq 1;
BA_ "SignalLongName" SG_ 424 TransClch2MaxEnrgy "Transmission Clutch 2 Maximum Energy";
BA_ "SignalType" SG_ 424 TransClch2MaxEnrgy "UNM";
BA_ "VNSigAllNodes" SG_ 424 TransClch2MaxEnrgy 1;
BA_ "SignalLongName" SG_ 424 TransClch2FlAch "Transmission Clutch 2 Fill Achieved";
BA_ "SignalType" SG_ 424 TransClch2FlAch "BLN";
BA_ "VNSigAllNodes" SG_ 424 TransClch2FlAch 1;
BA_REL_ "GenSigTimeoutTime" BU_SG_REL_ CGM_HS SG_ 388 HndsOffStrWhlDtSt 250;
BA_REL_ "GenSigTimeoutMsg" BU_SG_REL_ CGM_HS SG_ 388 HndsOffStrWhlDtSt 388;
BA_REL_ "GenSigSuprvResp" BU_SG_REL_ CGM_HS SG_ 388 HndsOffStrWhlDtSt 1;
BA_REL_ "GenSigTimeoutTime" BU_SG_REL_ CGM_HS SG_ 388 HndsOffStrWhlDtMd 250;
BA_REL_ "GenSigTimeoutMsg" BU_SG_REL_ CGM_HS SG_ 388 HndsOffStrWhlDtMd 388;
BA_REL_ "GenSigSuprvResp" BU_SG_REL_ CGM_HS SG_ 388 HndsOffStrWhlDtMd 1;
BA_REL_ "GenSigTimeoutTime" BU_SG_REL_ CGM_HS SG_ 388 LKATrqOvrlDltTrqDlvd 250;
BA_REL_ "GenSigTimeoutMsg" BU_SG_REL_ CGM_HS SG_ 388 LKATrqOvrlDltTrqDlvd 388;
BA_REL_ "GenSigSuprvResp" BU_SG_REL_ CGM_HS SG_ 388 LKATrqOvrlDltTrqDlvd 1;
BA_REL_ "GenSigTimeoutTime" BU_SG_REL_ CGM_HS SG_ 388 LKAElPwrStTtlTqDlvd 250;
BA_REL_ "GenSigTimeoutMsg" BU_SG_REL_ CGM_HS SG_ 388 LKAElPwrStTtlTqDlvd 388;
BA_REL_ "GenSigSuprvResp" BU_SG_REL_ CGM_HS SG_ 388 LKAElPwrStTtlTqDlvd 1;
BA_REL_ "GenSigTimeoutTime" BU_SG_REL_ CGM_HS SG_ 388 LKATrqOvrlTrqDStat 250;
BA_REL_ "GenSigTimeoutMsg" BU_SG_REL_ CGM_HS SG_ 388 LKATrqOvrlTrqDStat 388;
BA_REL_ "GenSigSuprvResp" BU_SG_REL_ CGM_HS SG_ 388 LKATrqOvrlTrqDStat 1;
BA_REL_ "GenSigTimeoutTime" BU_SG_REL_ CGM_HS SG_ 388 LKADrvAppldTrq 250;
BA_REL_ "GenSigTimeoutMsg" BU_SG_REL_ CGM_HS SG_ 388 LKADrvAppldTrq 388;
BA_REL_ "GenSigSuprvResp" BU_SG_REL_ CGM_HS SG_ 388 LKADrvAppldTrq 1;
BA_REL_ "GenSigTimeoutTime" BU_SG_REL_ BCM_HS SG_ 894 HdLtLvlFlrIO 3750;
BA_REL_ "GenSigTimeoutMsg" BU_SG_REL_ BCM_HS SG_ 894 HdLtLvlFlrIO 894;
BA_REL_ "GenSigSuprvResp" BU_SG_REL_ BCM_HS SG_ 894 HdLtLvlFlrIO 1;
BA_REL_ "GenSigTimeoutTime" BU_SG_REL_ BCM_HS SG_ 804 VehHghtStatV 1250;
BA_REL_ "GenSigTimeoutMsg" BU_SG_REL_ BCM_HS SG_ 804 VehHghtStatV 804;
BA_REL_ "GenSigSuprvRespSubValue" BU_SG_REL_ BCM_HS SG_ 804 VehHghtStatV 1;
BA_REL_ "GenSigSuprvResp" BU_SG_REL_ BCM_HS SG_ 804 VehHghtStatV 2;
BA_REL_ "GenSigTimeoutTime" BU_SG_REL_ BCM_HS SG_ 804 VehHghtStat 1250;
BA_REL_ "GenSigTimeoutMsg" BU_SG_REL_ BCM_HS SG_ 804 VehHghtStat 804;
BA_REL_ "GenSigVBitResp" BU_SG_REL_ BCM_HS SG_ 804 VehHghtStat 1;
BA_REL_ "GenSigSuprvResp" BU_SG_REL_ BCM_HS SG_ 804 VehHghtStat 1;
BA_REL_ "GenSigTimeoutTime" BU_SG_REL_ BCM_HS SG_ 804 SrvLevSysIO 1250;
BA_REL_ "GenSigTimeoutMsg" BU_SG_REL_ BCM_HS SG_ 804 SrvLevSysIO 804;
BA_REL_ "GenSigSuprvResp" BU_SG_REL_ BCM_HS SG_ 804 SrvLevSysIO 1;
BA_REL_ "GenSigTimeoutTime" BU_SG_REL_ BCM_HS SG_ 804 LevSysVehTopSpdLim 1250;
BA_REL_ "GenSigTimeoutMsg" BU_SG_REL_ BCM_HS SG_ 804 LevSysVehTopSpdLim 804;
BA_REL_ "GenSigSuprvResp" BU_SG_REL_ BCM_HS SG_ 804 LevSysVehTopSpdLim 1;
BA_REL_ "GenSigTimeoutTime" BU_SG_REL_ CGM_HS SG_ 842 WhlGrndVlctyRtNnDrvn 250;
BA_REL_ "GenSigTimeoutMsg" BU_SG_REL_ CGM_HS SG_ 842 WhlGrndVlctyRtNnDrvn 842;
BA_REL_ "GenSigSuprvResp" BU_SG_REL_ CGM_HS SG_ 842 WhlGrndVlctyRtNnDrvn 1;
BA_REL_ "GenSigTimeoutTime" BU_SG_REL_ EPS_HS SG_ 842 WhlGrndVlctyRtNnDrvn 250;
BA_REL_ "GenSigTimeoutMsg" BU_SG_REL_ EPS_HS SG_ 842 WhlGrndVlctyRtNnDrvn 842;
BA_REL_ "GenSigSuprvResp" BU_SG_REL_ EPS_HS SG_ 842 WhlGrndVlctyRtNnDrvn 1;
BA_REL_ "GenSigTimeoutTime" BU_SG_REL_ EPB_HS SG_ 842 WhlGrndVlctyRtNnDrvn 125;
BA_REL_ "GenSigTimeoutMsg" BU_SG_REL_ EPB_HS SG_ 842 WhlGrndVlctyRtNnDrvn 842;
BA_REL_ "GenSigSuprvResp" BU_SG_REL_ EPB_HS SG_ 842 WhlGrndVlctyRtNnDrvn 1;
BA_REL_ "GenSigTimeoutTime" BU_SG_REL_ TCCM_HS SG_ 842 WhlGrndVlctyRtNnDrvn 250;
BA_REL_ "GenSigTimeoutMsg" BU_SG_REL_ TCCM_HS SG_ 842 WhlGrndVlctyRtNnDrvn 842;
BA_REL_ "GenSigSuprvResp" BU_SG_REL_ TCCM_HS SG_ 842 WhlGrndVlctyRtNnDrvn 1;
BA_REL_ "GenSigTimeoutTime" BU_SG_REL_ BCM_HS SG_ 842 WhlGrndVlctyRtNnDrvn 250;
BA_REL_ "GenSigTimeoutMsg" BU_SG_REL_ BCM_HS SG_ 842 WhlGrndVlctyRtNnDrvn 842;
BA_REL_ "GenSigVBitResp" BU_SG_REL_ BCM_HS SG_ 842 WhlGrndVlctyRtNnDrvn 1;
BA_REL_ "GenSigSuprvResp" BU_SG_REL_ BCM_HS SG_ 842 WhlGrndVlctyRtNnDrvn 1;
BA_REL_ "GenSigTimeoutTime" BU_SG_REL_ CGM_HS SG_ 842 WhlGrndVlctyLftNnDrvn 250;
BA_REL_ "GenSigTimeoutMsg" BU_SG_REL_ CGM_HS SG_ 842 WhlGrndVlctyLftNnDrvn 842;
BA_REL_ "GenSigSuprvResp" BU_SG_REL_ CGM_HS SG_ 842 WhlGrndVlctyLftNnDrvn 1;
BA_REL_ "GenSigTimeoutTime" BU_SG_REL_ EPB_HS SG_ 842 WhlGrndVlctyLftNnDrvn 125;
BA_REL_ "GenSigTimeoutMsg" BU_SG_REL_ EPB_HS SG_ 842 WhlGrndVlctyLftNnDrvn 842;
BA_REL_ "GenSigSuprvResp" BU_SG_REL_ EPB_HS SG_ 842 WhlGrndVlctyLftNnDrvn 1;
BA_REL_ "GenSigTimeoutTime" BU_SG_REL_ TCCM_HS SG_ 842 WhlGrndVlctyLftNnDrvn 250;
BA_REL_ "GenSigTimeoutMsg" BU_SG_REL_ TCCM_HS SG_ 842 WhlGrndVlctyLftNnDrvn 842;
BA_REL_ "GenSigSuprvResp" BU_SG_REL_ TCCM_HS SG_ 842 WhlGrndVlctyLftNnDrvn 1;
BA_REL_ "GenSigTimeoutTime" BU_SG_REL_ BCM_HS SG_ 842 WhlGrndVlctyLftNnDrvn 250;
BA_REL_ "GenSigTimeoutMsg" BU_SG_REL_ BCM_HS SG_ 842 WhlGrndVlctyLftNnDrvn 842;
BA_REL_ "GenSigVBitResp" BU_SG_REL_ BCM_HS SG_ 842 WhlGrndVlctyLftNnDrvn 1;
BA_REL_ "GenSigSuprvResp" BU_SG_REL_ BCM_HS SG_ 842 WhlGrndVlctyLftNnDrvn 1;
BA_REL_ "GenSigTimeoutTime" BU_SG_REL_ CGM_HS SG_ 842 WhlRotDrctnlSRtNDrvn 250;
BA_REL_ "GenSigTimeoutMsg" BU_SG_REL_ CGM_HS SG_ 842 WhlRotDrctnlSRtNDrvn 842;
BA_REL_ "GenSigSuprvResp" BU_SG_REL_ CGM_HS SG_ 842 WhlRotDrctnlSRtNDrvn 1;
BA_REL_ "GenSigTimeoutTime" BU_SG_REL_ EPS_HS SG_ 842 WhlRotDrctnlSRtNDrvn 250;
BA_REL_ "GenSigTimeoutMsg" BU_SG_REL_ EPS_HS SG_ 842 WhlRotDrctnlSRtNDrvn 842;
BA_REL_ "GenSigSuprvResp" BU_SG_REL_ EPS_HS SG_ 842 WhlRotDrctnlSRtNDrvn 1;
BA_REL_ "GenSigTimeoutTime" BU_SG_REL_ CGM_HS SG_ 842 WhlRotDrctnlStLfNDrvn 250;
BA_REL_ "GenSigTimeoutMsg" BU_SG_REL_ CGM_HS SG_ 842 WhlRotDrctnlStLfNDrvn 842;
BA_REL_ "GenSigSuprvResp" BU_SG_REL_ CGM_HS SG_ 842 WhlRotDrctnlStLfNDrvn 1;
BA_REL_ "GenSigTimeoutTime" BU_SG_REL_ EPS_HS SG_ 842 WhlRotDrctnlStLfNDrvn 250;
BA_REL_ "GenSigTimeoutMsg" BU_SG_REL_ EPS_HS SG_ 842 WhlRotDrctnlStLfNDrvn 842;
BA_REL_ "GenSigSuprvResp" BU_SG_REL_ EPS_HS SG_ 842 WhlRotDrctnlStLfNDrvn 1;
BA_REL_ "GenSigTimeoutTime" BU_SG_REL_ CGM_HS SG_ 840 WhlGrndVlctyRtDrvn 250;
BA_REL_ "GenSigTimeoutMsg" BU_SG_REL_ CGM_HS SG_ 840 WhlGrndVlctyRtDrvn 840;
BA_REL_ "GenSigSuprvResp" BU_SG_REL_ CGM_HS SG_ 840 WhlGrndVlctyRtDrvn 1;
BA_REL_ "GenSigTimeoutTime" BU_SG_REL_ EPS_HS SG_ 840 WhlGrndVlctyRtDrvn 250;
BA_REL_ "GenSigTimeoutMsg" BU_SG_REL_ EPS_HS SG_ 840 WhlGrndVlctyRtDrvn 840;
BA_REL_ "GenSigSuprvResp" BU_SG_REL_ EPS_HS SG_ 840 WhlGrndVlctyRtDrvn 1;
BA_REL_ "GenSigTimeoutTime" BU_SG_REL_ TCCM_HS SG_ 840 WhlGrndVlctyRtDrvn 250;
BA_REL_ "GenSigTimeoutMsg" BU_SG_REL_ TCCM_HS SG_ 840 WhlGrndVlctyRtDrvn 840;
BA_REL_ "GenSigSuprvResp" BU_SG_REL_ TCCM_HS SG_ 840 WhlGrndVlctyRtDrvn 1;
BA_REL_ "GenSigTimeoutTime" BU_SG_REL_ EPB_HS SG_ 840 WhlGrndVlctyRtDrvn 125;
BA_REL_ "GenSigTimeoutMsg" BU_SG_REL_ EPB_HS SG_ 840 WhlGrndVlctyRtDrvn 840;
BA_REL_ "GenSigSuprvResp" BU_SG_REL_ EPB_HS SG_ 840 WhlGrndVlctyRtDrvn 1;
BA_REL_ "GenSigTimeoutTime" BU_SG_REL_ BCM_HS SG_ 840 WhlGrndVlctyRtDrvn 250;
BA_REL_ "GenSigTimeoutMsg" BU_SG_REL_ BCM_HS SG_ 840 WhlGrndVlctyRtDrvn 840;
BA_REL_ "GenSigVBitResp" BU_SG_REL_ BCM_HS SG_ 840 WhlGrndVlctyRtDrvn 1;
BA_REL_ "GenSigSuprvResp" BU_SG_REL_ BCM_HS SG_ 840 WhlGrndVlctyRtDrvn 1;
BA_REL_ "GenSigTimeoutTime" BU_SG_REL_ CGM_HS SG_ 840 WhlGrndVlctyLftDrvn 250;
BA_REL_ "GenSigTimeoutMsg" BU_SG_REL_ CGM_HS SG_ 840 WhlGrndVlctyLftDrvn 840;
BA_REL_ "GenSigSuprvResp" BU_SG_REL_ CGM_HS SG_ 840 WhlGrndVlctyLftDrvn 1;
BA_REL_ "GenSigTimeoutTime" BU_SG_REL_ TCCM_HS SG_ 840 WhlGrndVlctyLftDrvn 250;
BA_REL_ "GenSigTimeoutMsg" BU_SG_REL_ TCCM_HS SG_ 840 WhlGrndVlctyLftDrvn 840;
BA_REL_ "GenSigSuprvResp" BU_SG_REL_ TCCM_HS SG_ 840 WhlGrndVlctyLftDrvn 1;
BA_REL_ "GenSigTimeoutTime" BU_SG_REL_ EPB_HS SG_ 840 WhlGrndVlctyLftDrvn 125;
BA_REL_ "GenSigTimeoutMsg" BU_SG_REL_ EPB_HS SG_ 840 WhlGrndVlctyLftDrvn 840;
BA_REL_ "GenSigSuprvResp" BU_SG_REL_ EPB_HS SG_ 840 WhlGrndVlctyLftDrvn 1;
BA_REL_ "GenSigTimeoutTime" BU_SG_REL_ BCM_HS SG_ 840 WhlGrndVlctyLftDrvn 250;
BA_REL_ "GenSigTimeoutMsg" BU_SG_REL_ BCM_HS SG_ 840 WhlGrndVlctyLftDrvn 840;
BA_REL_ "GenSigVBitResp" BU_SG_REL_ BCM_HS SG_ 840 WhlGrndVlctyLftDrvn 1;
BA_REL_ "GenSigSuprvResp" BU_SG_REL_ BCM_HS SG_ 840 WhlGrndVlctyLftDrvn 1;
BA_REL_ "GenSigTimeoutTime" BU_SG_REL_ CGM_HS SG_ 840 WhlRotDrctnlStLftDrvn 250;
BA_REL_ "GenSigTimeoutMsg" BU_SG_REL_ CGM_HS SG_ 840 WhlRotDrctnlStLftDrvn 840;
BA_REL_ "GenSigSuprvResp" BU_SG_REL_ CGM_HS SG_ 840 WhlRotDrctnlStLftDrvn 1;
BA_REL_ "GenSigTimeoutTime" BU_SG_REL_ EPS_HS SG_ 840 WhlRotDrctnlStLftDrvn 250;
BA_REL_ "GenSigTimeoutMsg" BU_SG_REL_ EPS_HS SG_ 840 WhlRotDrctnlStLftDrvn 840;
BA_REL_ "GenSigSuprvResp" BU_SG_REL_ EPS_HS SG_ 840 WhlRotDrctnlStLftDrvn 1;
BA_REL_ "GenSigTimeoutTime" BU_SG_REL_ CGM_HS SG_ 840 WhlRotDrctnlStRtDrvn 250;
BA_REL_ "GenSigTimeoutMsg" BU_SG_REL_ CGM_HS SG_ 840 WhlRotDrctnlStRtDrvn 840;
BA_REL_ "GenSigSuprvResp" BU_SG_REL_ CGM_HS SG_ 840 WhlRotDrctnlStRtDrvn 1;
BA_REL_ "GenSigTimeoutTime" BU_SG_REL_ EPS_HS SG_ 840 WhlRotDrctnlStRtDrvn 250;
BA_REL_ "GenSigTimeoutMsg" BU_SG_REL_ EPS_HS SG_ 840 WhlRotDrctnlStRtDrvn 840;
BA_REL_ "GenSigSuprvResp" BU_SG_REL_ EPS_HS SG_ 840 WhlRotDrctnlStRtDrvn 1;
BA_REL_ "GenSigTimeoutTime" BU_SG_REL_ ICCM_OBD_HS SG_ 1323 TireLRTmp 2500;
BA_REL_ "GenSigTimeoutMsg" BU_SG_REL_ ICCM_OBD_HS SG_ 1323 TireLRTmp 1323;
BA_REL_ "GenSigSuprvResp" BU_SG_REL_ ICCM_OBD_HS SG_ 1323 TireLRTmp 1;
BA_REL_ "GenSigTimeoutTime" BU_SG_REL_ EBCM_OBD_HS SG_ 1323 TireLRTmp 2500;
BA_REL_ "GenSigTimeoutMsg" BU_SG_REL_ EBCM_OBD_HS SG_ 1323 TireLRTmp 1323;
BA_REL_ "GenSigSuprvResp" BU_SG_REL_ EBCM_OBD_HS SG_ 1323 TireLRTmp 1;
BA_REL_ "GenSigTimeoutTime" BU_SG_REL_ ICCM_HS SG_ 1323 TireLRTmp 2500;
BA_REL_ "GenSigTimeoutMsg" BU_SG_REL_ ICCM_HS SG_ 1323 TireLRTmp 1323;
BA_REL_ "GenSigSuprvResp" BU_SG_REL_ ICCM_HS SG_ 1323 TireLRTmp 1;
BA_REL_ "GenSigTimeoutTime" BU_SG_REL_ EBCM_HS SG_ 1323 TireLRTmp 2500;
BA_REL_ "GenSigTimeoutMsg" BU_SG_REL_ EBCM_HS SG_ 1323 TireLRTmp 1323;
BA_REL_ "GenSigSuprvResp" BU_SG_REL_ EBCM_HS SG_ 1323 TireLRTmp 1;
BA_REL_ "GenSigTimeoutTime" BU_SG_REL_ ICCM_OBD_HS SG_ 1323 TireLFTmp 2500;
BA_REL_ "GenSigTimeoutMsg" BU_SG_REL_ ICCM_OBD_HS SG_ 1323 TireLFTmp 1323;
BA_REL_ "GenSigSuprvResp" BU_SG_REL_ ICCM_OBD_HS SG_ 1323 TireLFTmp 1;
BA_REL_ "GenSigTimeoutTime" BU_SG_REL_ EBCM_OBD_HS SG_ 1323 TireLFTmp 2500;
BA_REL_ "GenSigTimeoutMsg" BU_SG_REL_ EBCM_OBD_HS SG_ 1323 TireLFTmp 1323;
BA_REL_ "GenSigSuprvResp" BU_SG_REL_ EBCM_OBD_HS SG_ 1323 TireLFTmp 1;
BA_REL_ "GenSigTimeoutTime" BU_SG_REL_ ICCM_HS SG_ 1323 TireLFTmp 2500;
BA_REL_ "GenSigTimeoutMsg" BU_SG_REL_ ICCM_HS SG_ 1323 TireLFTmp 1323;
BA_REL_ "GenSigSuprvResp" BU_SG_REL_ ICCM_HS SG_ 1323 TireLFTmp 1;
BA_REL_ "GenSigTimeoutTime" BU_SG_REL_ EBCM_HS SG_ 1323 TireLFTmp 2500;
BA_REL_ "GenSigTimeoutMsg" BU_SG_REL_ EBCM_HS SG_ 1323 TireLFTmp 1323;
BA_REL_ "GenSigSuprvResp" BU_SG_REL_ EBCM_HS SG_ 1323 TireLFTmp 1;
BA_REL_ "GenSigTimeoutTime" BU_SG_REL_ ICCM_OBD_HS SG_ 1323 TireRRTmp 2500;
BA_REL_ "GenSigTimeoutMsg" BU_SG_REL_ ICCM_OBD_HS SG_ 1323 TireRRTmp 1323;
BA_REL_ "GenSigSuprvResp" BU_SG_REL_ ICCM_OBD_HS SG_ 1323 TireRRTmp 1;
BA_REL_ "GenSigTimeoutTime" BU_SG_REL_ EBCM_OBD_HS SG_ 1323 TireRRTmp 2500;
BA_REL_ "GenSigTimeoutMsg" BU_SG_REL_ EBCM_OBD_HS SG_ 1323 TireRRTmp 1323;
BA_REL_ "GenSigSuprvResp" BU_SG_REL_ EBCM_OBD_HS SG_ 1323 TireRRTmp 1;
BA_REL_ "GenSigTimeoutTime" BU_SG_REL_ ICCM_HS SG_ 1323 TireRRTmp 2500;
BA_REL_ "GenSigTimeoutMsg" BU_SG_REL_ ICCM_HS SG_ 1323 TireRRTmp 1323;
BA_REL_ "GenSigSuprvResp" BU_SG_REL_ ICCM_HS SG_ 1323 TireRRTmp 1;
BA_REL_ "GenSigTimeoutTime" BU_SG_REL_ EBCM_HS SG_ 1323 TireRRTmp 2500;
BA_REL_ "GenSigTimeoutMsg" BU_SG_REL_ EBCM_HS SG_ 1323 TireRRTmp 1323;
BA_REL_ "GenSigSuprvResp" BU_SG_REL_ EBCM_HS SG_ 1323 TireRRTmp 1;
BA_REL_ "GenSigTimeoutTime" BU_SG_REL_ ICCM_OBD_HS SG_ 1323 TireRFTmp 2500;
BA_REL_ "GenSigTimeoutMsg" BU_SG_REL_ ICCM_OBD_HS SG_ 1323 TireRFTmp 1323;
BA_REL_ "GenSigSuprvResp" BU_SG_REL_ ICCM_OBD_HS SG_ 1323 TireRFTmp 1;
BA_REL_ "GenSigTimeoutTime" BU_SG_REL_ EBCM_OBD_HS SG_ 1323 TireRFTmp 2500;
BA_REL_ "GenSigTimeoutMsg" BU_SG_REL_ EBCM_OBD_HS SG_ 1323 TireRFTmp 1323;
BA_REL_ "GenSigSuprvResp" BU_SG_REL_ EBCM_OBD_HS SG_ 1323 TireRFTmp 1;
BA_REL_ "GenSigTimeoutTime" BU_SG_REL_ ICCM_HS SG_ 1323 TireRFTmp 2500;
BA_REL_ "GenSigTimeoutMsg" BU_SG_REL_ ICCM_HS SG_ 1323 TireRFTmp 1323;
BA_REL_ "GenSigSuprvResp" BU_SG_REL_ ICCM_HS SG_ 1323 TireRFTmp 1;
BA_REL_ "GenSigTimeoutTime" BU_SG_REL_ EBCM_HS SG_ 1323 TireRFTmp 2500;
BA_REL_ "GenSigTimeoutMsg" BU_SG_REL_ EBCM_HS SG_ 1323 TireRFTmp 1323;
BA_REL_ "GenSigSuprvResp" BU_SG_REL_ EBCM_HS SG_ 1323 TireRFTmp 1;
BA_REL_ "GenSigTimeoutTime" BU_SG_REL_ EBCM_OBD_HS SG_ 313 DrvStyPerfMdCsStReq 250;
BA_REL_ "GenSigTimeoutMsg" BU_SG_REL_ EBCM_OBD_HS SG_ 313 DrvStyPerfMdCsStReq 313;
BA_REL_ "GenSigSuprvResp" BU_SG_REL_ EBCM_OBD_HS SG_ 313 DrvStyPerfMdCsStReq 1;
BA_REL_ "GenSigTimeoutTime" BU_SG_REL_ EBCM_HS SG_ 313 DrvStyPerfMdCsStReq 250;
BA_REL_ "GenSigTimeoutMsg" BU_SG_REL_ EBCM_HS SG_ 313 DrvStyPerfMdCsStReq 313;
BA_REL_ "GenSigSuprvResp" BU_SG_REL_ EBCM_HS SG_ 313 DrvStyPerfMdCsStReq 1;
BA_REL_ "GenSigTimeoutTime" BU_SG_REL_ EBCM_OBD_HS SG_ 313 PsngStPerfMdCsStReq 250;
BA_REL_ "GenSigTimeoutMsg" BU_SG_REL_ EBCM_OBD_HS SG_ 313 PsngStPerfMdCsStReq 313;
BA_REL_ "GenSigSuprvResp" BU_SG_REL_ EBCM_OBD_HS SG_ 313 PsngStPerfMdCsStReq 1;
BA_REL_ "GenSigTimeoutTime" BU_SG_REL_ EBCM_HS SG_ 313 PsngStPerfMdCsStReq 250;
BA_REL_ "GenSigTimeoutMsg" BU_SG_REL_ EBCM_HS SG_ 313 PsngStPerfMdCsStReq 313;
BA_REL_ "GenSigSuprvResp" BU_SG_REL_ EBCM_HS SG_ 313 PsngStPerfMdCsStReq 1;
BA_REL_ "GenSigTimeoutTime" BU_SG_REL_ EBCM_OBD_HS SG_ 313 DrvrStPerfMdCsStReq 250;
BA_REL_ "GenSigTimeoutMsg" BU_SG_REL_ EBCM_OBD_HS SG_ 313 DrvrStPerfMdCsStReq 313;
BA_REL_ "GenSigSuprvResp" BU_SG_REL_ EBCM_OBD_HS SG_ 313 DrvrStPerfMdCsStReq 1;
BA_REL_ "GenSigTimeoutTime" BU_SG_REL_ EBCM_HS SG_ 313 DrvrStPerfMdCsStReq 250;
BA_REL_ "GenSigTimeoutMsg" BU_SG_REL_ EBCM_HS SG_ 313 DrvrStPerfMdCsStReq 313;
BA_REL_ "GenSigSuprvResp" BU_SG_REL_ EBCM_HS SG_ 313 DrvrStPerfMdCsStReq 1;
BA_REL_ "GenSigTimeoutTime" BU_SG_REL_ EBCM_OBD_HS SG_ 313 ACCPerfMdCsStReq 250;
BA_REL_ "GenSigTimeoutMsg" BU_SG_REL_ EBCM_OBD_HS SG_ 313 ACCPerfMdCsStReq 313;
BA_REL_ "GenSigSuprvResp" BU_SG_REL_ EBCM_OBD_HS SG_ 313 ACCPerfMdCsStReq 1;
BA_REL_ "GenSigTimeoutTime" BU_SG_REL_ EBCM_HS SG_ 313 ACCPerfMdCsStReq 250;
BA_REL_ "GenSigTimeoutMsg" BU_SG_REL_ EBCM_HS SG_ 313 ACCPerfMdCsStReq 313;
BA_REL_ "GenSigSuprvResp" BU_SG_REL_ EBCM_HS SG_ 313 ACCPerfMdCsStReq 1;
BA_REL_ "GenSigTimeoutTime" BU_SG_REL_ EBCM_OBD_HS SG_ 313 SndPerfMdCsStRq 250;
BA_REL_ "GenSigTimeoutMsg" BU_SG_REL_ EBCM_OBD_HS SG_ 313 SndPerfMdCsStRq 313;
BA_REL_ "GenSigSuprvResp" BU_SG_REL_ EBCM_OBD_HS SG_ 313 SndPerfMdCsStRq 1;
BA_REL_ "GenSigTimeoutTime" BU_SG_REL_ EBCM_HS SG_ 313 SndPerfMdCsStRq 250;
BA_REL_ "GenSigTimeoutMsg" BU_SG_REL_ EBCM_HS SG_ 313 SndPerfMdCsStRq 313;
BA_REL_ "GenSigSuprvResp" BU_SG_REL_ EBCM_HS SG_ 313 SndPerfMdCsStRq 1;
BA_REL_ "GenSigTimeoutTime" BU_SG_REL_ EBCM_OBD_HS SG_ 313 DispPerfMdCsStRq 250;
BA_REL_ "GenSigTimeoutMsg" BU_SG_REL_ EBCM_OBD_HS SG_ 313 DispPerfMdCsStRq 313;
BA_REL_ "GenSigSuprvResp" BU_SG_REL_ EBCM_OBD_HS SG_ 313 DispPerfMdCsStRq 1;
BA_REL_ "GenSigTimeoutTime" BU_SG_REL_ EBCM_HS SG_ 313 DispPerfMdCsStRq 250;
BA_REL_ "GenSigTimeoutMsg" BU_SG_REL_ EBCM_HS SG_ 313 DispPerfMdCsStRq 313;
BA_REL_ "GenSigSuprvResp" BU_SG_REL_ EBCM_HS SG_ 313 DispPerfMdCsStRq 1;
BA_REL_ "GenSigTimeoutTime" BU_SG_REL_ EBCM_OBD_HS SG_ 313 CrshAlrtStPrsnt 250;
BA_REL_ "GenSigTimeoutMsg" BU_SG_REL_ EBCM_OBD_HS SG_ 313 CrshAlrtStPrsnt 313;
BA_REL_ "GenSigSuprvResp" BU_SG_REL_ EBCM_OBD_HS SG_ 313 CrshAlrtStPrsnt 1;
BA_REL_ "GenSigTimeoutTime" BU_SG_REL_ EBCM_HS SG_ 313 CrshAlrtStPrsnt 250;
BA_REL_ "GenSigTimeoutMsg" BU_SG_REL_ EBCM_HS SG_ 313 CrshAlrtStPrsnt 313;
BA_REL_ "GenSigSuprvResp" BU_SG_REL_ EBCM_HS SG_ 313 CrshAlrtStPrsnt 1;
BA_REL_ "GenSigTimeoutTime" BU_SG_REL_ EBCM_OBD_HS SG_ 810 PsngSysLong 250;
BA_REL_ "GenSigTimeoutMsg" BU_SG_REL_ EBCM_OBD_HS SG_ 810 PsngSysLong 810;
BA_REL_ "GenSigSuprvResp" BU_SG_REL_ EBCM_OBD_HS SG_ 810 PsngSysLong 1;
BA_REL_ "GenSigTimeoutTime" BU_SG_REL_ EBCM_HS SG_ 810 PsngSysLong 250;
BA_REL_ "GenSigTimeoutMsg" BU_SG_REL_ EBCM_HS SG_ 810 PsngSysLong 810;
BA_REL_ "GenSigSuprvResp" BU_SG_REL_ EBCM_HS SG_ 810 PsngSysLong 1;
BA_REL_ "GenSigTimeoutTime" BU_SG_REL_ EBCM_OBD_HS SG_ 810 PsngSysLat 250;
BA_REL_ "GenSigTimeoutMsg" BU_SG_REL_ EBCM_OBD_HS SG_ 810 PsngSysLat 810;
BA_REL_ "GenSigSuprvResp" BU_SG_REL_ EBCM_OBD_HS SG_ 810 PsngSysLat 1;
BA_REL_ "GenSigTimeoutTime" BU_SG_REL_ EBCM_HS SG_ 810 PsngSysLat 250;
BA_REL_ "GenSigTimeoutMsg" BU_SG_REL_ EBCM_HS SG_ 810 PsngSysLat 810;
BA_REL_ "GenSigSuprvResp" BU_SG_REL_ EBCM_HS SG_ 810 PsngSysLat 1;
BA_REL_ "GenSigTimeoutTime" BU_SG_REL_ EBCM_OBD_HS SG_ 309 StBltTgtCSRq 250;
BA_REL_ "GenSigTimeoutMsg" BU_SG_REL_ EBCM_OBD_HS SG_ 309 StBltTgtCSRq 309;
BA_REL_ "GenSigSuprvResp" BU_SG_REL_ EBCM_OBD_HS SG_ 309 StBltTgtCSRq 1;
BA_REL_ "GenSigTimeoutTime" BU_SG_REL_ EBCM_HS SG_ 309 StBltTgtCSRq 250;
BA_REL_ "GenSigTimeoutMsg" BU_SG_REL_ EBCM_HS SG_ 309 StBltTgtCSRq 309;
BA_REL_ "GenSigSuprvResp" BU_SG_REL_ EBCM_HS SG_ 309 StBltTgtCSRq 1;
BA_REL_ "GenSigTimeoutTime" BU_SG_REL_ EBCM_OBD_HS SG_ 309 CldrYr 250;
BA_REL_ "GenSigTimeoutMsg" BU_SG_REL_ EBCM_OBD_HS SG_ 309 CldrYr 309;
BA_REL_ "GenSigSuprvResp" BU_SG_REL_ EBCM_OBD_HS SG_ 309 CldrYr 1;
BA_REL_ "GenSigTimeoutTime" BU_SG_REL_ EBCM_HS SG_ 309 CldrYr 250;
BA_REL_ "GenSigTimeoutMsg" BU_SG_REL_ EBCM_HS SG_ 309 CldrYr 309;
BA_REL_ "GenSigSuprvResp" BU_SG_REL_ EBCM_HS SG_ 309 CldrYr 1;
BA_REL_ "GenSigTimeoutTime" BU_SG_REL_ EBCM_OBD_HS SG_ 309 CldrMth 250;
BA_REL_ "GenSigTimeoutMsg" BU_SG_REL_ EBCM_OBD_HS SG_ 309 CldrMth 309;
BA_REL_ "GenSigSuprvResp" BU_SG_REL_ EBCM_OBD_HS SG_ 309 CldrMth 1;
BA_REL_ "GenSigTimeoutTime" BU_SG_REL_ EBCM_HS SG_ 309 CldrMth 250;
BA_REL_ "GenSigTimeoutMsg" BU_SG_REL_ EBCM_HS SG_ 309 CldrMth 309;
BA_REL_ "GenSigSuprvResp" BU_SG_REL_ EBCM_HS SG_ 309 CldrMth 1;
BA_REL_ "GenSigTimeoutTime" BU_SG_REL_ EBCM_OBD_HS SG_ 309 CldrDay 250;
BA_REL_ "GenSigTimeoutMsg" BU_SG_REL_ EBCM_OBD_HS SG_ 309 CldrDay 309;
BA_REL_ "GenSigSuprvResp" BU_SG_REL_ EBCM_OBD_HS SG_ 309 CldrDay 1;
BA_REL_ "GenSigTimeoutTime" BU_SG_REL_ EBCM_HS SG_ 309 CldrDay 250;
BA_REL_ "GenSigTimeoutMsg" BU_SG_REL_ EBCM_HS SG_ 309 CldrDay 309;
BA_REL_ "GenSigSuprvResp" BU_SG_REL_ EBCM_HS SG_ 309 CldrDay 1;
BA_REL_ "GenSigTimeoutTime" BU_SG_REL_ HMIM_HS SG_ 309 VehMovState 250;
BA_REL_ "GenSigTimeoutMsg" BU_SG_REL_ HMIM_HS SG_ 309 VehMovState 309;
BA_REL_ "GenSigSuprvResp" BU_SG_REL_ HMIM_HS SG_ 309 VehMovState 1;
BA_REL_ "GenSigTimeoutTime" BU_SG_REL_ EBCM_OBD_HS SG_ 352 AVHSwtchStats 250;
BA_REL_ "GenSigTimeoutMsg" BU_SG_REL_ EBCM_OBD_HS SG_ 352 AVHSwtchStats 352;
BA_REL_ "GenSigSuprvResp" BU_SG_REL_ EBCM_OBD_HS SG_ 352 AVHSwtchStats 1;
BA_REL_ "GenSigTimeoutTime" BU_SG_REL_ EBCM_HS SG_ 352 AVHSwtchStats 250;
BA_REL_ "GenSigTimeoutMsg" BU_SG_REL_ EBCM_HS SG_ 352 AVHSwtchStats 352;
BA_REL_ "GenSigSuprvResp" BU_SG_REL_ EBCM_HS SG_ 352 AVHSwtchStats 1;
BA_REL_ "GenSigTimeoutTime" BU_SG_REL_ CGM_HS SG_ 352 TeenDrvAct 250;
BA_REL_ "GenSigTimeoutMsg" BU_SG_REL_ CGM_HS SG_ 352 TeenDrvAct 352;
BA_REL_ "GenSigSuprvResp" BU_SG_REL_ CGM_HS SG_ 352 TeenDrvAct 1;
BA_REL_ "GenSigTimeoutTime" BU_SG_REL_ EBCM_OBD_HS SG_ 352 TeenDrvAct 250;
BA_REL_ "GenSigTimeoutMsg" BU_SG_REL_ EBCM_OBD_HS SG_ 352 TeenDrvAct 352;
BA_REL_ "GenSigSuprvResp" BU_SG_REL_ EBCM_OBD_HS SG_ 352 TeenDrvAct 1;
BA_REL_ "GenSigTimeoutTime" BU_SG_REL_ EBCM_HS SG_ 352 TeenDrvAct 250;
BA_REL_ "GenSigTimeoutMsg" BU_SG_REL_ EBCM_HS SG_ 352 TeenDrvAct 352;
BA_REL_ "GenSigSuprvResp" BU_SG_REL_ EBCM_HS SG_ 352 TeenDrvAct 1;
BA_REL_ "GenSigTimeoutTime" BU_SG_REL_ ICCM_OBD_HS SG_ 1322 TireRRPrsStat 2500;
BA_REL_ "GenSigTimeoutMsg" BU_SG_REL_ ICCM_OBD_HS SG_ 1322 TireRRPrsStat 1322;
BA_REL_ "GenSigSuprvResp" BU_SG_REL_ ICCM_OBD_HS SG_ 1322 TireRRPrsStat 1;
BA_REL_ "GenSigTimeoutTime" BU_SG_REL_ ICCM_HS SG_ 1322 TireRRPrsStat 2500;
BA_REL_ "GenSigTimeoutMsg" BU_SG_REL_ ICCM_HS SG_ 1322 TireRRPrsStat 1322;
BA_REL_ "GenSigSuprvResp" BU_SG_REL_ ICCM_HS SG_ 1322 TireRRPrsStat 1;
BA_REL_ "GenSigTimeoutTime" BU_SG_REL_ ICCM_OBD_HS SG_ 1322 TireRRPrs 2500;
BA_REL_ "GenSigTimeoutMsg" BU_SG_REL_ ICCM_OBD_HS SG_ 1322 TireRRPrs 1322;
BA_REL_ "GenSigSuprvResp" BU_SG_REL_ ICCM_OBD_HS SG_ 1322 TireRRPrs 1;
BA_REL_ "GenSigTimeoutTime" BU_SG_REL_ ICCM_HS SG_ 1322 TireRRPrs 2500;
BA_REL_ "GenSigTimeoutMsg" BU_SG_REL_ ICCM_HS SG_ 1322 TireRRPrs 1322;
BA_REL_ "GenSigSuprvResp" BU_SG_REL_ ICCM_HS SG_ 1322 TireRRPrs 1;
BA_REL_ "GenSigTimeoutTime" BU_SG_REL_ ICCM_OBD_HS SG_ 1322 TireRFPrsStat 2500;
BA_REL_ "GenSigTimeoutMsg" BU_SG_REL_ ICCM_OBD_HS SG_ 1322 TireRFPrsStat 1322;
BA_REL_ "GenSigSuprvResp" BU_SG_REL_ ICCM_OBD_HS SG_ 1322 TireRFPrsStat 1;
BA_REL_ "GenSigTimeoutTime" BU_SG_REL_ ICCM_HS SG_ 1322 TireRFPrsStat 2500;
BA_REL_ "GenSigTimeoutMsg" BU_SG_REL_ ICCM_HS SG_ 1322 TireRFPrsStat 1322;
BA_REL_ "GenSigSuprvResp" BU_SG_REL_ ICCM_HS SG_ 1322 TireRFPrsStat 1;
BA_REL_ "GenSigTimeoutTime" BU_SG_REL_ ICCM_OBD_HS SG_ 1322 TireRFPrs 2500;
BA_REL_ "GenSigTimeoutMsg" BU_SG_REL_ ICCM_OBD_HS SG_ 1322 TireRFPrs 1322;
BA_REL_ "GenSigSuprvResp" BU_SG_REL_ ICCM_OBD_HS SG_ 1322 TireRFPrs 1;
BA_REL_ "GenSigTimeoutTime" BU_SG_REL_ ICCM_HS SG_ 1322 TireRFPrs 2500;
BA_REL_ "GenSigTimeoutMsg" BU_SG_REL_ ICCM_HS SG_ 1322 TireRFPrs 1322;
BA_REL_ "GenSigSuprvResp" BU_SG_REL_ ICCM_HS SG_ 1322 TireRFPrs 1;
BA_REL_ "GenSigTimeoutTime" BU_SG_REL_ ICCM_OBD_HS SG_ 1322 TireLRPrsStat 2500;
BA_REL_ "GenSigTimeoutMsg" BU_SG_REL_ ICCM_OBD_HS SG_ 1322 TireLRPrsStat 1322;
BA_REL_ "GenSigSuprvResp" BU_SG_REL_ ICCM_OBD_HS SG_ 1322 TireLRPrsStat 1;
BA_REL_ "GenSigTimeoutTime" BU_SG_REL_ ICCM_HS SG_ 1322 TireLRPrsStat 2500;
BA_REL_ "GenSigTimeoutMsg" BU_SG_REL_ ICCM_HS SG_ 1322 TireLRPrsStat 1322;
BA_REL_ "GenSigSuprvResp" BU_SG_REL_ ICCM_HS SG_ 1322 TireLRPrsStat 1;
BA_REL_ "GenSigTimeoutTime" BU_SG_REL_ ICCM_OBD_HS SG_ 1322 TireLRPrs 2500;
BA_REL_ "GenSigTimeoutMsg" BU_SG_REL_ ICCM_OBD_HS SG_ 1322 TireLRPrs 1322;
BA_REL_ "GenSigSuprvResp" BU_SG_REL_ ICCM_OBD_HS SG_ 1322 TireLRPrs 1;
BA_REL_ "GenSigTimeoutTime" BU_SG_REL_ ICCM_HS SG_ 1322 TireLRPrs 2500;
BA_REL_ "GenSigTimeoutMsg" BU_SG_REL_ ICCM_HS SG_ 1322 TireLRPrs 1322;
BA_REL_ "GenSigSuprvResp" BU_SG_REL_ ICCM_HS SG_ 1322 TireLRPrs 1;
BA_REL_ "GenSigTimeoutTime" BU_SG_REL_ ICCM_OBD_HS SG_ 1322 TireLFPrsStat 2500;
BA_REL_ "GenSigTimeoutMsg" BU_SG_REL_ ICCM_OBD_HS SG_ 1322 TireLFPrsStat 1322;
BA_REL_ "GenSigSuprvResp" BU_SG_REL_ ICCM_OBD_HS SG_ 1322 TireLFPrsStat 1;
BA_REL_ "GenSigTimeoutTime" BU_SG_REL_ ICCM_HS SG_ 1322 TireLFPrsStat 2500;
BA_REL_ "GenSigTimeoutMsg" BU_SG_REL_ ICCM_HS SG_ 1322 TireLFPrsStat 1322;
BA_REL_ "GenSigSuprvResp" BU_SG_REL_ ICCM_HS SG_ 1322 TireLFPrsStat 1;
BA_REL_ "GenSigTimeoutTime" BU_SG_REL_ ICCM_OBD_HS SG_ 1322 TireLFPrs 2500;
BA_REL_ "GenSigTimeoutMsg" BU_SG_REL_ ICCM_OBD_HS SG_ 1322 TireLFPrs 1322;
BA_REL_ "GenSigSuprvResp" BU_SG_REL_ ICCM_OBD_HS SG_ 1322 TireLFPrs 1;
BA_REL_ "GenSigTimeoutTime" BU_SG_REL_ ICCM_HS SG_ 1322 TireLFPrs 2500;
BA_REL_ "GenSigTimeoutMsg" BU_SG_REL_ ICCM_HS SG_ 1322 TireLFPrs 1322;
BA_REL_ "GenSigSuprvResp" BU_SG_REL_ ICCM_HS SG_ 1322 TireLFPrs 1;
BA_REL_ "GenSigTimeoutTime" BU_SG_REL_ CGM_HS SG_ 1300 VehIdNmDig2_9 2500;
BA_REL_ "GenSigTimeoutMsg" BU_SG_REL_ CGM_HS SG_ 1300 VehIdNmDig2_9 1300;
BA_REL_ "GenSigSuprvResp" BU_SG_REL_ CGM_HS SG_ 1300 VehIdNmDig2_9 1;
BA_REL_ "GenSigTimeoutTime" BU_SG_REL_ EBCM_OBD_HS SG_ 1300 VehIdNmDig2_9 2500;
BA_REL_ "GenSigTimeoutMsg" BU_SG_REL_ EBCM_OBD_HS SG_ 1300 VehIdNmDig2_9 1300;
BA_REL_ "GenSigSuprvResp" BU_SG_REL_ EBCM_OBD_HS SG_ 1300 VehIdNmDig2_9 1;
BA_REL_ "GenSigTimeoutTime" BU_SG_REL_ TCCM_HS SG_ 1300 VehIdNmDig2_9 2500;
BA_REL_ "GenSigTimeoutMsg" BU_SG_REL_ TCCM_HS SG_ 1300 VehIdNmDig2_9 1300;
BA_REL_ "GenSigSuprvResp" BU_SG_REL_ TCCM_HS SG_ 1300 VehIdNmDig2_9 1;
BA_REL_ "GenSigTimeoutTime" BU_SG_REL_ EBCM_HS SG_ 1300 VehIdNmDig2_9 2500;
BA_REL_ "GenSigTimeoutMsg" BU_SG_REL_ EBCM_HS SG_ 1300 VehIdNmDig2_9 1300;
BA_REL_ "GenSigSuprvResp" BU_SG_REL_ EBCM_HS SG_ 1300 VehIdNmDig2_9 1;
BA_REL_ "GenSigTimeoutMsg" BU_SG_REL_ CGM_HS SG_ 288 VehOdo 288;
BA_REL_ "GenSigSuprvResp" BU_SG_REL_ CGM_HS SG_ 288 VehOdo 1;
BA_REL_ "GenSigTimeoutMsg" BU_SG_REL_ EBCM_OBD_HS SG_ 288 VehOdo 288;
BA_REL_ "GenSigSuprvResp" BU_SG_REL_ EBCM_OBD_HS SG_ 288 VehOdo 1;
BA_REL_ "GenSigTimeoutMsg" BU_SG_REL_ EPB_HS SG_ 288 VehOdo 288;
BA_REL_ "GenSigSuprvResp" BU_SG_REL_ EPB_HS SG_ 288 VehOdo 1;
BA_REL_ "GenSigTimeoutMsg" BU_SG_REL_ TCCM_HS SG_ 288 VehOdo 288;
BA_REL_ "GenSigSuprvResp" BU_SG_REL_ TCCM_HS SG_ 288 VehOdo 1;
BA_REL_ "GenSigTimeoutMsg" BU_SG_REL_ EBCM_HS SG_ 288 VehOdo 288;
BA_REL_ "GenSigSuprvResp" BU_SG_REL_ EBCM_HS SG_ 288 VehOdo 1;
BA_REL_ "GenSigTimeoutTime" BU_SG_REL_ TCM_HS SG_ 208 WhlSlipRRWhl 250;
BA_REL_ "GenSigTimeoutMsg" BU_SG_REL_ TCM_HS SG_ 208 WhlSlipRRWhl 208;
BA_REL_ "GenSigSuprvResp" BU_SG_REL_ TCM_HS SG_ 208 WhlSlipRRWhl 1;
BA_REL_ "GenSigTimeoutTime" BU_SG_REL_ TCM_HS SG_ 208 WhlSlipRFWhl 250;
BA_REL_ "GenSigTimeoutMsg" BU_SG_REL_ TCM_HS SG_ 208 WhlSlipRFWhl 208;
BA_REL_ "GenSigSuprvResp" BU_SG_REL_ TCM_HS SG_ 208 WhlSlipRFWhl 1;
BA_REL_ "GenSigTimeoutTime" BU_SG_REL_ TCM_HS SG_ 208 WhlSlipLRWhl 250;
BA_REL_ "GenSigTimeoutMsg" BU_SG_REL_ TCM_HS SG_ 208 WhlSlipLRWhl 208;
BA_REL_ "GenSigSuprvResp" BU_SG_REL_ TCM_HS SG_ 208 WhlSlipLRWhl 1;
BA_REL_ "GenSigTimeoutTime" BU_SG_REL_ TCM_HS SG_ 208 WhlSlipLFWhl 250;
BA_REL_ "GenSigTimeoutMsg" BU_SG_REL_ TCM_HS SG_ 208 WhlSlipLFWhl 208;
BA_REL_ "GenSigSuprvResp" BU_SG_REL_ TCM_HS SG_ 208 WhlSlipLFWhl 1;
BA_REL_ "GenSigTimeoutTime" BU_SG_REL_ TCM_HS SG_ 1247 RrPTCoolFanStat 1250;
BA_REL_ "GenSigTimeoutMsg" BU_SG_REL_ TCM_HS SG_ 1247 RrPTCoolFanStat 1247;
BA_REL_ "GenSigSuprvResp" BU_SG_REL_ TCM_HS SG_ 1247 RrPTCoolFanStat 1;
BA_REL_ "GenSigTimeoutTime" BU_SG_REL_ TCM_HS SG_ 1247 RrPTCoolFanSpPctCmd 1250;
BA_REL_ "GenSigTimeoutMsg" BU_SG_REL_ TCM_HS SG_ 1247 RrPTCoolFanSpPctCmd 1247;
BA_REL_ "GenSigSuprvResp" BU_SG_REL_ TCM_HS SG_ 1247 RrPTCoolFanSpPctCmd 1;
BA_REL_ "GenSigTimeoutTime" BU_SG_REL_ EPS_HS SG_ 389 StrAngSnsPolRat 250;
BA_REL_ "GenSigTimeoutMsg" BU_SG_REL_ EPS_HS SG_ 389 StrAngSnsPolRat 389;
BA_REL_ "GenSigSuprvResp" BU_SG_REL_ EPS_HS SG_ 389 StrAngSnsPolRat 1;
BA_REL_ "GenSigTimeoutTime" BU_SG_REL_ EPS_HS SG_ 389 LatAccSnsPolRat 250;
BA_REL_ "GenSigTimeoutMsg" BU_SG_REL_ EPS_HS SG_ 389 LatAccSnsPolRat 389;
BA_REL_ "GenSigSuprvResp" BU_SG_REL_ EPS_HS SG_ 389 LatAccSnsPolRat 1;
BA_REL_ "GenSigTimeoutTime" BU_SG_REL_ CGM_HS SG_ 389 VSELongAccLoRes 250;
BA_REL_ "GenSigTimeoutMsg" BU_SG_REL_ CGM_HS SG_ 389 VSELongAccLoRes 389;
BA_REL_ "GenSigSuprvResp" BU_SG_REL_ CGM_HS SG_ 389 VSELongAccLoRes 1;
BA_REL_ "GenSigTimeoutTime" BU_SG_REL_ EPS_HS SG_ 389 VSELongAccLoRes 250;
BA_REL_ "GenSigTimeoutMsg" BU_SG_REL_ EPS_HS SG_ 389 VSELongAccLoRes 389;
BA_REL_ "GenSigSuprvResp" BU_SG_REL_ EPS_HS SG_ 389 VSELongAccLoRes 1;
BA_REL_ "GenSigTimeoutTime" BU_SG_REL_ EBCM_OBD_HS SG_ 1013 Sig1889 625;
BA_REL_ "GenSigTimeoutMsg" BU_SG_REL_ EBCM_OBD_HS SG_ 1013 Sig1889 1013;
BA_REL_ "GenSigSuprvResp" BU_SG_REL_ EBCM_OBD_HS SG_ 1013 Sig1889 1;
BA_REL_ "GenSigTimeoutTime" BU_SG_REL_ EBCM_HS SG_ 1013 Sig1889 625;
BA_REL_ "GenSigTimeoutMsg" BU_SG_REL_ EBCM_HS SG_ 1013 Sig1889 1013;
BA_REL_ "GenSigSuprvResp" BU_SG_REL_ EBCM_HS SG_ 1013 Sig1889 1;
BA_REL_ "GenSigTimeoutTime" BU_SG_REL_ EBCM_OBD_HS SG_ 1013 Sig1888 625;
BA_REL_ "GenSigTimeoutMsg" BU_SG_REL_ EBCM_OBD_HS SG_ 1013 Sig1888 1013;
BA_REL_ "GenSigSuprvResp" BU_SG_REL_ EBCM_OBD_HS SG_ 1013 Sig1888 1;
BA_REL_ "GenSigTimeoutTime" BU_SG_REL_ EBCM_HS SG_ 1013 Sig1888 625;
BA_REL_ "GenSigTimeoutMsg" BU_SG_REL_ EBCM_HS SG_ 1013 Sig1888 1013;
BA_REL_ "GenSigSuprvResp" BU_SG_REL_ EBCM_HS SG_ 1013 Sig1888 1;
VAL_ 3221225472 PTOStdbSpdCsCrStVal 0 "No Action" 1 "900 rpm" 2 "1000 rpm" 3 "1100 rpm" 4 "1200 rpm" 5 "1300 rpm" 6 "1400 rpm" 7 "1500 rpm" ;
VAL_ 3221225472 HVBatChrgCrdAlrtReq 0 "None" 1 "Pedestrian" 2 "Theft" ;
VAL_ 3221225472 PTOSet2SpdCsStAvl 1 "true" 0 "false" ;
VAL_ 3221225472 PTOSet2SpdCsCrStVal 0 "No Action" 1 "1900 rpm" 2 "2000 rpm" 3 "2100 rpm" 4 "2200 rpm" 5 "2300 rpm" 6 "2400 rpm" 7 "2500 rpm" 8 "2600 rpm" 9 "2700 rpm" 10 "2800 rpm" 11 "2900 rpm" 12 "3000 rpm" 13 "3100 rpm" 14 "3200 rpm" 15 "3300 rpm" ;
VAL_ 3221225472 PTOSet1SpdCsStAvl 1 "true" 0 "false" ;
VAL_ 3221225472 PTOSet1SpdCsCrStVal 0 "No Action" 1 "1100 rpm" 2 "1200 rpm" 3 "1300 rpm" 4 "1400 rpm" 5 "1500 rpm" 6 "1600 rpm" 7 "1700 rpm" 8 "1800 rpm" 9 "1900 rpm" 10 "2000 rpm" 11 "2100 rpm" 12 "2200 rpm" 13 "2300 rpm" 14 "2400 rpm" 15 "2500 rpm" ;
VAL_ 3221225472 PTOEngRnTmrCsStAvl 1 "true" 0 "false" ;
VAL_ 3221225472 PTOEnRnTmCsCrStVal 7 "210 min" 0 "No Action" 1 "10 min" 2 "30 min" 3 "90 min" 4 "120 min" 5 "150 min" 6 "180 min" 8 "240 min" 9 "270 min" 10 "300 min" 11 "330 min" 12 "360 min" 13 "390 min" 14 "420 min" 15 "450 min" ;
VAL_ 3221225472 MntnceMdStEngRq 1 "true" 0 "false" ;
VAL_ 3221225472 PTOAccelUpnBrkRelIO 1 "true" 0 "false" ;
VAL_ 3221225472 PTOEngUpnBrkRelIO 1 "true" 0 "false" ;
VAL_ 3221225472 PTOManTransInGrIO 1 "true" 0 "false" ;
VAL_ 3221225472 PTOServIndOn 1 "true" 0 "false" ;
VAL_ 3221225472 PTOTransInGearIO 1 "true" 0 "false" ;
VAL_ 3221225472 PTOSetPrkBrkIO 1 "true" 0 "false" ;
VAL_ 3221225472 PTORelCltPedIO 1 "true" 0 "false" ;
VAL_ 3221225472 PTORelBrkPedIO 1 "true" 0 "false" ;
VAL_ 3221225472 PTORelAccPedIO 1 "true" 0 "false" ;
VAL_ 3221225472 PTORedEngSpdIO 1 "true" 0 "false" ;
VAL_ 3221225472 PTOPrsRelCltPedIO 1 "true" 0 "false" ;
VAL_ 3221225472 PTOPrsRelBrkPedIO 1 "true" 0 "false" ;
VAL_ 3221225472 PTOEngmntStatInd 0 "No Indication" 1 "Continuous Indication" 2 "Slow Flashing Indication" 3 "Fast Flashing Indication" ;
VAL_ 3221225472 PTODisengCrsCntlIO 1 "true" 0 "false" ;
VAL_ 3221225472 PTOMobModTrnsInGrIO 1 "true" 0 "false" ;
VAL_ 3221225472 ActVbnCtrlMlfIO 1 "true" 0 "false" ;
VAL_ 3221225472 SrvSuspSysIO 1 "true" 0 "false" ;
VAL_ 3221225472 DCCnvStblznErrIO 1 "true" 0 "false" ;
VAL_ 558 CDSP_CmpDgrdOp 1 "true" 0 "false" ;
VAL_ 558 CDSP_CmpIntShdwnFltSt 2 "state0805" 1 "Fault" 0 "state0622" ;
VAL_ 558 CDSP_CmpIntRecblFltSt 2 "state0805" 1 "Fault" 0 "state0622" ;
VAL_ 558 CDSP_CmpOpOvrldSt 2 "state0805" 1 "Fault" 0 "state0622" ;
VAL_ 558 CDSP_CmpDrCrctFltSt 2 "state0805" 1 "Fault" 0 "state0622" ;
VAL_ 558 CDSP_CmpMtrPerfFltSt 2 "state0805" 1 "Fault" 0 "state0622" ;
VAL_ 558 CDSP_CmpEEPROMFltSt 2 "state0805" 1 "Fault" 0 "state0622" ;
VAL_ 558 CDSP_CmpROMFltSt 2 "state0805" 1 "Fault" 0 "state0622" ;
VAL_ 558 CDSP_CmpRAMFltSt 2 "state0805" 1 "Fault" 0 "state0622" ;
VAL_ 558 CSSP_CmpIGBTTpOtRgLSt 2 "state0805" 1 "Fault" 0 "state0622" ;
VAL_ 558 CSSP_CmpIGBTTpOtRgHSt 2 "state0805" 1 "Fault" 0 "state0622" ;
VAL_ 558 CSSP_CmpCPUTmpOtRgLSt 2 "state0805" 1 "Fault" 0 "state0622" ;
VAL_ 558 CSSP_CmpCPUTmpOtRgHSt 2 "state0805" 1 "Fault" 0 "state0622" ;
VAL_ 558 CSSP_CmpHVSnsOtRgLSt 2 "state0805" 1 "Fault" 0 "state0622" ;
VAL_ 558 CSSP_CmpHVSnsOtRgHSt 2 "state0805" 1 "Fault" 0 "state0622" ;
VAL_ 558 CSSP_CmpPhCrntOtRgLSt 2 "state0805" 1 "Fault" 0 "state0622" ;
VAL_ 558 CSSP_CmpPhCrntOtRgHSt 2 "state0805" 1 "Fault" 0 "state0622" ;
VAL_ 558 CDP_HVDevShtdnCdARCSt 2 "state0805" 1 "Fault" 0 "state0622" ;
VAL_ 558 CDP_CmpSpdReqARCSt 2 "state0805" 1 "Fault" 0 "state0622" ;
VAL_ 558 CDP_CmpLossCommOcc 1 "true" 0 "false" ;
VAL_ 558 CDP_CmpWkUp 1 "true" 0 "false" ;
VAL_ 558 CDP_CmpRunCrnk 1 "true" 0 "false" ;
VAL_ 558 CDSP_CmpOvrTmpSt 2 "state0805" 1 "Fault" 0 "state0622" ;
VAL_ 558 CDSP_CmpHVAbnrlOrVltSt 2 "state0805" 1 "Fault" 0 "state0622" ;
VAL_ 558 CDSP_CmpHVUndrVltgSt 2 "state0805" 1 "Fault" 0 "state0622" ;
VAL_ 558 CDSP_CmpHVOvrVltgSt 2 "state0805" 1 "Fault" 0 "state0622" ;
VAL_ 558 CDSP_CmpHVOvrCrntSt 2 "state0805" 1 "Fault" 0 "state0622" ;
VAL_ 558 CDSP_OvrTempWrnInd 1 "true" 0 "false" ;
VAL_ 550 ACCMCII_DatStat 0 "Cal ID Index Not Used" 1 "Cal Verification Number Uncalculated" 2 "Cal Verification Number Calculated" ;
VAL_ 546 ThrmlRefCompStatFdbck 3 "Invalid" 2 "Inoperative" 1 "Degraded Operation" 0 "Normal Operation" ;
VAL_ 289 Sig0935 0 "Reserved 1" 1 "Position" 2 "state0646" 3 "state0655" 4 "state0631" 5 "state0630" 6 "state0618" 7 "Reserved 2" ;
VAL_ 1910 DTCI_DTCFaultType_776 3 "Type C" 2 "Type B" 1 "Type A" 0 "Not Supported" ;
VAL_ 1910 DTCI_CodeSupported_776 1 "true" 0 "false" ;
VAL_ 1910 DTCI_CurrentStatus_776 1 "true" 0 "false" ;
VAL_ 1910 DTCI_TstNPsdCdClrdSt_776 1 "true" 0 "false" ;
VAL_ 1910 DTCI_TstFldCdClrdStat_776 1 "true" 0 "false" ;
VAL_ 1910 DTCI_HistStat_776 1 "true" 0 "false" ;
VAL_ 1910 DTCI_TstNPsdPwrUpSt_776 1 "true" 0 "false" ;
VAL_ 1910 DTCI_TstFldPwrUpSt_776 1 "true" 0 "false" ;
VAL_ 1910 DTCI_WrnIndRqdSt_776 1 "true" 0 "false" ;
VAL_ 1910 DTCI_DTCTriggered_776 1 "true" 0 "false" ;
VAL_ 1910 DTCIUnused7_776 1 "true" 0 "false" ;
VAL_ 1910 DTCIUnused6_776 1 "true" 0 "false" ;
VAL_ 1910 DTCIUnused5_776 1 "true" 0 "false" ;
VAL_ 1910 DTCIUnused4_776 1 "true" 0 "false" ;
VAL_ 1910 DTCIUnused3_776 1 "true" 0 "false" ;
VAL_ 1910 DTCIUnused2_776 1 "true" 0 "false" ;
VAL_ 1910 DTCIUnused1_776 1 "true" 0 "false" ;
VAL_ 1916 DTCI_DTCFaultType_77C 3 "Type C" 2 "Type B" 1 "Type A" 0 "Not Supported" ;
VAL_ 1916 DTCI_CodeSupported_77C 1 "true" 0 "false" ;
VAL_ 1916 DTCI_CurrentStatus_77C 1 "true" 0 "false" ;
VAL_ 1916 DTCI_TstNPsdCdClrdSt_77C 1 "true" 0 "false" ;
VAL_ 1916 DTCI_TstFldCdClrdStat_77C 1 "true" 0 "false" ;
VAL_ 1916 DTCI_HistStat_77C 1 "true" 0 "false" ;
VAL_ 1916 DTCI_TstNPsdPwrUpSt_77C 1 "true" 0 "false" ;
VAL_ 1916 DTCI_TstFldPwrUpSt_77C 1 "true" 0 "false" ;
VAL_ 1916 DTCI_WrnIndRqdSt_77C 1 "true" 0 "false" ;
VAL_ 1916 DTCI_DTCTriggered_77C 1 "true" 0 "false" ;
VAL_ 1916 DTCIUnused7_77C 1 "true" 0 "false" ;
VAL_ 1916 DTCIUnused6_77C 1 "true" 0 "false" ;
VAL_ 1916 DTCIUnused5_77C 1 "true" 0 "false" ;
VAL_ 1916 DTCIUnused4_77C 1 "true" 0 "false" ;
VAL_ 1916 DTCIUnused3_77C 1 "true" 0 "false" ;
VAL_ 1916 DTCIUnused2_77C 1 "true" 0 "false" ;
VAL_ 1916 DTCIUnused1_77C 1 "true" 0 "false" ;
VAL_ 1917 DTCI_DTCFaultType_77D 3 "Type C" 2 "Type B" 1 "Type A" 0 "Not Supported" ;
VAL_ 1917 DTCI_CodeSupported_77D 1 "true" 0 "false" ;
VAL_ 1917 DTCI_CurrentStatus_77D 1 "true" 0 "false" ;
VAL_ 1917 DTCI_TstNPsdCdClrdSt_77D 1 "true" 0 "false" ;
VAL_ 1917 DTCI_TstFldCdClrdStat_77D 1 "true" 0 "false" ;
VAL_ 1917 DTCI_HistStat_77D 1 "true" 0 "false" ;
VAL_ 1917 DTCI_TstNPsdPwrUpSt_77D 1 "true" 0 "false" ;
VAL_ 1917 DTCI_TstFldPwrUpSt_77D 1 "true" 0 "false" ;
VAL_ 1917 DTCI_WrnIndRqdSt_77D 1 "true" 0 "false" ;
VAL_ 1917 DTCI_DTCTriggered_77D 1 "true" 0 "false" ;
VAL_ 1917 DTCIUnused7_77D 1 "true" 0 "false" ;
VAL_ 1917 DTCIUnused6_77D 1 "true" 0 "false" ;
VAL_ 1917 DTCIUnused5_77D 1 "true" 0 "false" ;
VAL_ 1917 DTCIUnused4_77D 1 "true" 0 "false" ;
VAL_ 1917 DTCIUnused3_77D 1 "true" 0 "false" ;
VAL_ 1917 DTCIUnused2_77D 1 "true" 0 "false" ;
VAL_ 1917 DTCIUnused1_77D 1 "true" 0 "false" ;
VAL_ 388 HndsOffStrWhlDtStV 1 "Invalid" 0 "Valid" ;
VAL_ 388 HndsOffStrWhlDtSt 0 "Hands Off" 1 "Hands On" ;
VAL_ 388 HndsOffStrWhlDtMd 0 "Disabled" 1 "Enabled" 2 "Failed" ;
VAL_ 388 LKATrqOvrlTrqDStat 0 "Inactive" 1 "Active" 2 "Temporarily Limited" 3 "Permanently Failed" ;
VAL_ 388 LKADrvAppldTrqV 1 "Invalid" 0 "Valid" ;
VAL_ 884 AdvWthrStat 0 "Clear weather" 1 "Fog" 2 "Snow" 3 "Rain" ;
VAL_ 884 DtctdLghtSrcDrvngDrctn 0 "Unknown" 1 "Incoming Traffic" 2 "Ahead Traffic" ;
VAL_ 884 TwnDtctnSts 0 "Not Active" 1 "Town Not Detected" 2 "Town Detected" 3 "Undefined" ;
VAL_ 884 DtctdLghtSrcDstncV 1 "Invalid" 0 "Valid" ;
VAL_ 884 IntLghtRngAct 1 "true" 0 "false" ;
VAL_ 1930 DTCI_CodeSupported_78A 1 "true" 0 "false" ;
VAL_ 1930 DTCI_CurrentStatus_78A 1 "true" 0 "false" ;
VAL_ 1930 DTCI_DTCFaultType_78A 3 "Type C" 2 "Type B" 1 "Type A" 0 "Not Supported" ;
VAL_ 1930 DTCI_DTCTriggered_78A 1 "true" 0 "false" ;
VAL_ 1930 DTCI_HistStat_78A 1 "true" 0 "false" ;
VAL_ 1930 DTCI_TstFldCdClrdStat_78A 1 "true" 0 "false" ;
VAL_ 1930 DTCI_TstFldPwrUpSt_78A 1 "true" 0 "false" ;
VAL_ 1930 DTCI_TstNPsdCdClrdSt_78A 1 "true" 0 "false" ;
VAL_ 1930 DTCI_TstNPsdPwrUpSt_78A 1 "true" 0 "false" ;
VAL_ 1930 DTCIUnused1_78A 1 "true" 0 "false" ;
VAL_ 1930 DTCIUnused2_78A 1 "true" 0 "false" ;
VAL_ 1930 DTCIUnused3_78A 1 "true" 0 "false" ;
VAL_ 1930 DTCIUnused4_78A 1 "true" 0 "false" ;
VAL_ 1930 DTCIUnused5_78A 1 "true" 0 "false" ;
VAL_ 1930 DTCIUnused6_78A 1 "true" 0 "false" ;
VAL_ 1930 DTCIUnused7_78A 1 "true" 0 "false" ;
VAL_ 1930 DTCI_WrnIndRqdSt_78A 1 "true" 0 "false" ;
VAL_ 1914 DTCI_DTCFaultType_77A 3 "Type C" 2 "Type B" 1 "Type A" 0 "Not Supported" ;
VAL_ 1914 DTCI_CodeSupported_77A 1 "true" 0 "false" ;
VAL_ 1914 DTCI_CurrentStatus_77A 1 "true" 0 "false" ;
VAL_ 1914 DTCI_TstNPsdCdClrdSt_77A 1 "true" 0 "false" ;
VAL_ 1914 DTCI_TstFldCdClrdStat_77A 1 "true" 0 "false" ;
VAL_ 1914 DTCI_HistStat_77A 1 "true" 0 "false" ;
VAL_ 1914 DTCI_TstNPsdPwrUpSt_77A 1 "true" 0 "false" ;
VAL_ 1914 DTCI_TstFldPwrUpSt_77A 1 "true" 0 "false" ;
VAL_ 1914 DTCI_WrnIndRqdSt_77A 1 "true" 0 "false" ;
VAL_ 1914 DTCI_DTCTriggered_77A 1 "true" 0 "false" ;
VAL_ 1914 DTCIUnused7_77A 1 "true" 0 "false" ;
VAL_ 1914 DTCIUnused6_77A 1 "true" 0 "false" ;
VAL_ 1914 DTCIUnused5_77A 1 "true" 0 "false" ;
VAL_ 1914 DTCIUnused4_77A 1 "true" 0 "false" ;
VAL_ 1914 DTCIUnused3_77A 1 "true" 0 "false" ;
VAL_ 1914 DTCIUnused2_77A 1 "true" 0 "false" ;
VAL_ 1914 DTCIUnused1_77A 1 "true" 0 "false" ;
VAL_ 894 RtLwBmFld 1 "true" 0 "false" ;
VAL_ 894 LftLwBmFld 1 "true" 0 "false" ;
VAL_ 894 AdvFrntLghtSysIndRq 7 "Indication 7" 6 "Indication 6" 5 "Indication 5" 4 "Indication 4" 3 "Indication 3" 2 "Indication 2" 1 "Indication 1" 0 "No Indication" ;
VAL_ 894 HdLtLvlFlrIO 1 "true" 0 "false" ;
VAL_ 804 CompOvrhtIndOn 1 "true" 0 "false" ;
VAL_ 804 VehHghtStatV 1 "Invalid" 0 "Valid" ;
VAL_ 804 VehHghtStat 4 "Maximum Height" 3 "Kneeling Height" 2 "Aerodynamic Height" 1 "Normal Design Ride Height" 0 "Unknown" ;
VAL_ 804 SrvLevSysIO 1 "true" 0 "false" ;
VAL_ 804 VehOvrLdIndOn 1 "true" 0 "false" ;
VAL_ 842 WhlGrndVlctyRtNnDrvnV 1 "Invalid" 0 "Valid" ;
VAL_ 842 WhlGrndVlctyLftNnDrvnV 1 "Invalid" 0 "Valid" ;
VAL_ 842 WhlRotDrctnlSRtNDrvn 0 "Unknown" 1 "Forward" 2 "Reverse" 3 "Not Supported" 4 "Failed" 5 "Reserved 1" 6 "Reserved 2" 7 "Reserved 3" ;
VAL_ 842 WhlRotDrctnlStLfNDrvn 0 "Unknown" 1 "Forward" 2 "Reverse" 3 "Not Supported" 4 "Failed" 5 "Reserved 1" 6 "Reserved 2" 7 "Reserved 3" ;
VAL_ 840 WhlGrndVlctyRtDrvnV 1 "Invalid" 0 "Valid" ;
VAL_ 840 WhlGrndVlctyLftDrvnV 1 "Invalid" 0 "Valid" ;
VAL_ 840 WhlRotDrctnlStLftDrvn 0 "Unknown" 1 "Forward" 2 "Reverse" 3 "Not Supported" 4 "Failed" 5 "Reserved 1" 6 "Reserved 2" 7 "Reserved 3" ;
VAL_ 840 WhlRotDrctnlStRtDrvn 0 "Unknown" 1 "Forward" 2 "Reverse" 3 "Not Supported" 4 "Failed" 5 "Reserved 1" 6 "Reserved 2" 7 "Reserved 3" ;
VAL_ 1323 TireLRTmpV 1 "Invalid" 0 "Valid" ;
VAL_ 1323 TireLFTmpV 1 "Invalid" 0 "Valid" ;
VAL_ 1323 TireRRTmpV 1 "Invalid" 0 "Valid" ;
VAL_ 1323 TireRFTmpV 1 "Invalid" 0 "Valid" ;
VAL_ 543 PTOTpStpSpdCsStReq 0 "No Action" 1 "5 rpm" 2 "10 rpm" 3 "25 rpm" 4 "50 rpm" 5 "100 rpm" 6 "250 rpm" 7 "500 rpm" ;
VAL_ 543 PTOStdbySpdCsStReq 0 "No Action" 1 "900 rpm" 2 "1000 rpm" 3 "1100 rpm" 4 "1200 rpm" 5 "1300 rpm" 6 "1400 rpm" 7 "1500 rpm" ;
VAL_ 543 PTOEngRnTmrCsStRq 0 "No Action" 1 "10 min" 2 "30 min" 3 "90 min" 4 "120 min" 5 "150 min" 6 "180 min" 7 "210 min" 8 "240 min" 9 "270 min" 10 "300 min" 11 "330 min" 12 "360 min" 13 "390 min" 14 "420 min" 15 "450 min" ;
VAL_ 543 PTOSet2SpdCsStReq 0 "No Action" 1 "1900 rpm" 2 "2000 rpm" 3 "2100 rpm" 4 "2200 rpm" 5 "2300 rpm" 6 "2400 rpm" 7 "2500 rpm" 8 "2600 rpm" 9 "2700 rpm" 10 "2800 rpm" 11 "2900 rpm" 12 "3000 rpm" 13 "3100 rpm" 14 "3200 rpm" 15 "3300 rpm" ;
VAL_ 543 PTOSet1SpdCsStReq 0 "No Action" 1 "1100 rpm" 2 "1200 rpm" 3 "1300 rpm" 4 "1400 rpm" 5 "1500 rpm" 6 "1600 rpm" 7 "1700 rpm" 8 "1800 rpm" 9 "1900 rpm" 10 "2000 rpm" 11 "2100 rpm" 12 "2200 rpm" 13 "2300 rpm" 14 "2400 rpm" 15 "2500 rpm" ;
VAL_ 313 ExtHlStrAssCsStRq 2 "Standard Hold" 1 "Extended Hold" 0 "No Action" ;
VAL_ 313 DrvStyPerfMdCsStReq 7 "Performance Mode 7" 6 "Performance Mode 6" 5 "Performance Mode 5" 4 "Performance Mode 4" 3 "Performance Mode 3" 2 "Performance Mode 2" 1 "Performance Mode 1" 0 "No Action" ;
VAL_ 313 PsngStPerfMdCsStReq 7 "Auto" 6 "Performance Mode 6" 5 "Performance Mode 5" 4 "Performance Mode 4" 3 "Performance Mode 3" 2 "Performance Mode 2" 1 "Performance Mode 1" 0 "No Action" ;
VAL_ 313 DrvrStPerfMdCsStReq 7 "Auto" 6 "Performance Mode 6" 5 "Performance Mode 5" 4 "Performance Mode 4" 3 "Performance Mode 3" 2 "Performance Mode 2" 1 "Performance Mode 1" 0 "No Action" ;
VAL_ 313 ACCPerfMdCsStReq 7 "Auto" 6 "Performance Mode 6" 5 "Performance Mode 5" 4 "Performance Mode 4" 3 "Performance Mode 3" 2 "Performance Mode 2" 1 "Performance Mode 1" 0 "No Action" ;
VAL_ 313 PrkAstAdvSysAct 1 "true" 0 "false" ;
VAL_ 313 SndPerfMdCsStRq 0 "No Action" 1 "Performance Mode 1" 2 "Performance Mode 2" 3 "Performance Mode 3" 4 "Performance Mode 4" 5 "Performance Mode 5" 6 "Performance Mode 6" 7 "Auto" ;
VAL_ 313 HptcStVbnStat 0 "Normal Operation" 1 "Unknown" 2 "Failed" ;
VAL_ 313 ACCSettingType 0 "Manual" 1 "Auto" ;
VAL_ 313 FCABrkPrflReq 1 "true" 0 "false" ;
VAL_ 313 ISA2CCC_ScndCdChr 0 "Unknown" 1 "A" 2 "B" 3 "C" 4 "D" 5 "E" 6 "F" 7 "G" 8 "H" 9 "I" 10 "J" 11 "K" 12 "L" 13 "M" 14 "N" 15 "O" 16 "P" 17 "Q" 18 "R" 19 "S" 20 "T" 21 "U" 22 "V" 23 "W" 24 "X" 25 "Y" 26 "Z" ;
VAL_ 313 ISA2CCC_FrstCdChr 0 "Unknown" 1 "A" 2 "B" 3 "C" 4 "D" 5 "E" 6 "F" 7 "G" 8 "H" 9 "I" 10 "J" 11 "K" 12 "L" 13 "M" 14 "N" 15 "O" 16 "P" 17 "Q" 18 "R" 19 "S" 20 "T" 21 "U" 22 "V" 23 "W" 24 "X" 25 "Y" 26 "Z" ;
VAL_ 313 DispPerfMdCsStRq 0 "No Action" 1 "Performance Mode 1" 2 "Performance Mode 2" 3 "Performance Mode 3" 4 "Performance Mode 4" 5 "Performance Mode 5" 6 "Performance Mode 6" 7 "Auto" ;
VAL_ 313 CrshAlrtStPrsnt 1 "true" 0 "false" ;
VAL_ 313 FwdClnAlrtCustStngReq 0 "No Action" 1 "Off" 2 "On" ;
VAL_ 313 GNCustStngReq 0 "No Action" 1 "Off" 2 "On" ;
VAL_ 1328 ACSAlarm5 2 "Expired" 1 "Active" 0 "Inactive" ;
VAL_ 1328 ACSAlarm4 2 "Expired" 1 "Active" 0 "Inactive" ;
VAL_ 1328 ACSAlarm3 2 "Expired" 1 "Active" 0 "Inactive" ;
VAL_ 1328 ACSAlarm2 2 "Expired" 1 "Active" 0 "Inactive" ;
VAL_ 1328 ACSAlarm15 2 "Expired" 1 "Active" 0 "Inactive" ;
VAL_ 1328 ACSAlarm14 2 "Expired" 1 "Active" 0 "Inactive" ;
VAL_ 1328 ACSAlarm13 2 "Expired" 1 "Active" 0 "Inactive" ;
VAL_ 1328 ACSAlarm12 2 "Expired" 1 "Active" 0 "Inactive" ;
VAL_ 1328 ACSAlarm11 2 "Expired" 1 "Active" 0 "Inactive" ;
VAL_ 1328 ACSAlarm10 2 "Expired" 1 "Active" 0 "Inactive" ;
VAL_ 1328 ACSAlarm1 2 "Expired" 1 "Active" 0 "Inactive" ;
VAL_ 1328 ACSAlarm0 2 "Expired" 1 "Active" 0 "Inactive" ;
VAL_ 311 PsngSysHdingV 1 "Invalid" 0 "Valid" ;
VAL_ 311 HrsV 1 "Invalid" 0 "Valid" ;
VAL_ 311 MinsV 1 "Invalid" 0 "Valid" ;
VAL_ 311 PsngSysDilPrcsV 1 "Invalid" 0 "Valid" ;
VAL_ 311 PsngSysElvtnV 1 "Invalid" 0 "Valid" ;
VAL_ 311 VehSpeSta 3 "Invalid" 2 "Fast" 1 "Slow" 0 "Stationary" ;
VAL_ 810 PsngSysLongV 1 "Invalid" 0 "Valid" ;
VAL_ 810 PsngSysLatV 1 "Invalid" 0 "Valid" ;
VAL_ 304 PedFrndlyAlrtCsStReq 0 "No Action" 1 "Off" 2 "On" ;
VAL_ 304 AlrmStat 4 "Arming Delay" 3 "Alarm Active" 2 "Disarmed" 1 "Armed" 0 "Off" ;
VAL_ 322 AFLGPSCstStReq 0 "No Action" 1 "Corner And Curve Lighting Only" 2 "Intelligent Light Distribution" 3 "GPS Assistance" 4 "Reserved1" 5 "Reserved2" 6 "Reserved3" 7 "Off" ;
VAL_ 322 AFLCstStReq 0 "No Action" 1 "Corner And Curve Lighting Only" 2 "Intelligent Light Distribution" 3 "Reserved1" 4 "Reserved2" 5 "Reserved3" 6 "Reserved4" 7 "Off" ;
VAL_ 322 LtRtHnTrCstStReq 0 "No Action" 1 "Left Hand Drive" 2 "Right Hand Drive" ;
VAL_ 322 AdpHgBmAsSnCsStRq 0 "No Action" 1 "Off" 2 "Normal Sensitivity" 3 "Reduced Sensitivity" 4 "Reserved1" 5 "Reserved2" 6 "Reserved3" 7 "Reserved4" ;
VAL_ 322 AdpHgBmAstCstStRq 0 "No Action" 1 "Off" 2 "On" 3 "Reserved1" 4 "Reserved2" 5 "Reserved3" 6 "Reserved4" 7 "Reserved5" ;
VAL_ 322 LtRtHnTrGPSCstStRq 0 "No Action" 1 "Left Hand Traffic" 2 "Right Hand Traffic" 3 "Automatic" 4 "Reserved1" 5 "Reserved2" 6 "Reserved3" 7 "Reserved4" ;
VAL_ 322 AutHgBmAsSnCsStRq 0 "No Action" 1 "Off" 2 "On Normal Sensitivity" 3 "On Reduced Sensitivity" 4 "Reserved1" 5 "Reserved2" 6 "Reserved3" 7 "Reserved4" ;
VAL_ 322 AutHgBmAstCstStRq 0 "No Action" 1 "Off" 2 "On" 3 "Reserved1" 4 "Reserved2" 5 "Reserved3" 6 "Reserved4" 7 "Reserved5" ;
VAL_ 309 StBltTgtCSRq 0 "No Action" 1 "Low" 2 "Normal" 3 "Performance" 4 "Locked" ;
VAL_ 309 ColPrSysCustReq 0 "No Action" 1 "Off" 2 "Alert" 3 "Alert and Brake" ;
VAL_ 309 SecV 1 "Invalid" 0 "Valid" ;
VAL_ 309 CldrMth_154 12 "December" 11 "November" 10 "October" 9 "September" 8 "August" 7 "July" 6 "June" 5 "May" 4 "April" 3 "March" 2 "February" 1 "January" 0 "Unknown" ;
VAL_ 309 CldrMth 12 "December" 11 "November" 10 "October" 9 "September" 8 "August" 7 "July" 6 "June" 5 "May" 4 "April" 3 "March" 2 "February" 1 "January" 0 "Unknown" ;
VAL_ 309 PedFrndlyAlrtSndMnAct 1 "true" 0 "false" ;
VAL_ 309 AutoHiBmVDA 1 "VirtualDeviceAvailable" 0 "VirtualDeviceUnavailable" ;
VAL_ 309 CtLghtDet 1 "true" 0 "false" ;
VAL_ 309 RrClosVDA 1 "VirtualDeviceAvailable" 0 "VirtualDeviceUnavailable" ;
VAL_ 309 TCSysDisSwAtv 1 "true" 0 "false" ;
VAL_ 309 VehMovState 4 "Invalid" 3 "Reverse" 2 "Forward" 1 "Neutral" 0 "Parked" ;
VAL_ 309 TCSysDisSwAtvV 1 "Invalid" 0 "Valid" ;
VAL_ 309 HillDesCtrlMdSwActV 1 "Invalid" 0 "Valid" ;
VAL_ 309 WSWshSwAtv 1 "true" 0 "false" ;
VAL_ 309 HillDesCtrlMdSwAct 1 "true" 0 "false" ;
VAL_ 309 RrClosAjarSwAct 1 "true" 0 "false" ;
VAL_ 309 WSWprAct 1 "true" 0 "false" ;
VAL_ 352 AVHSwtchStats 1 "Active" 0 "Not Active" ;
VAL_ 352 TeenDrvAct 1 "true" 0 "false" ;
VAL_ 352 LrnEnvIdSt 1 "Info_valid" 0 "No_info" ;
VAL_ 352 ImoIdSt 1 "Info valid" 0 "No info" ;
VAL_ 1322 TireRRPrsV 1 "Invalid" 0 "Valid" ;
VAL_ 1322 TireRRPrsStat 5 "High" 4 "Low - Extended Mobility" 3 "Low" 2 "Low - Service Now" 1 "Nominal" 0 "Unknown" ;
VAL_ 1322 TireRFPrsV 1 "Invalid" 0 "Valid" ;
VAL_ 1322 TireRFPrsStat 5 "High" 4 "Low - Extended Mobility" 3 "Low" 2 "Low - Service Now" 1 "Nominal" 0 "Unknown" ;
VAL_ 1322 TireLRPrsV 1 "Invalid" 0 "Valid" ;
VAL_ 1322 TireLRPrsStat 5 "High" 4 "Low - Extended Mobility" 3 "Low" 2 "Low - Service Now" 1 "Nominal" 0 "Unknown" ;
VAL_ 1322 TireLFPrsV 1 "Invalid" 0 "Valid" ;
VAL_ 1322 TireLFPrsStat 5 "High" 4 "Low - Extended Mobility" 3 "Low" 2 "Low - Service Now" 1 "Nominal" 0 "Unknown" ;
VAL_ 288 VehOdoV 1 "Invalid" 0 "Valid" ;
VAL_ 1247 RrPTCoolFanStatV 1 "Invalid" 0 "Valid" ;
VAL_ 1247 RrPTCoolFanStat 0 "Off" 1 "On" ;
VAL_ 389 StrAngSnsPolRat 0 "Not Passed" 1 "Passed" ;
VAL_ 389 LatAccSnsPolRat 0 "Not Passed" 1 "Passed" ;
VAL_ 389 VSELongAccLoResV 1 "Invalid" 0 "Valid" ;
VAL_ 1013 Sig1889 0 "Normal" 1 "Reduced Speed 1" 2 "Reduced Speed 2" 3 "Reduced Speed 3" ;
VAL_ 1013 Sig1888 0 "Normal" 1 "Level 1" 2 "Level 2" 3 "Level 3" ;
VAL_ 425 TransClch5FlAch 1 "true" 0 "false" ;
VAL_ 425 TransClch4FlAch 1 "true" 0 "false" ;
VAL_ 424 TransClch3FlAch 1 "true" 0 "false" ;
VAL_ 424 TransClch2FlAch 1 "true" 0 "false" ;
SIG_GROUP_ 558 CmpDevStPkt 1 : CDSP_CmpHVAbnrlOrVltSt CDSP_CmpHVUndrVltgSt CDSP_CmpHVOvrVltgSt CDSP_CmpHVOvrCrntSt CDSP_OvrTempWrnInd CDSP_CmpDgrdOp CDSP_CmpIntShdwnFltSt CDSP_CmpIntRecblFltSt CDSP_CmpOpOvrldSt CDSP_CmpDrCrctFltSt CDSP_CmpMtrPerfFltSt CDSP_CmpEEPROMFltSt CDSP_CmpROMFltSt CDSP_CmpRAMFltSt CDSP_CmpOvrTmpSt;
SIG_GROUP_ 558 CmpSnsrStPkt 1 : CSSP_CmpIGBTTpOtRgLSt CSSP_CmpIGBTTpOtRgHSt CSSP_CmpCPUTmpOtRgLSt CSSP_CmpCPUTmpOtRgHSt CSSP_CmpHVSnsOtRgLSt CSSP_CmpHVSnsOtRgHSt CSSP_CmpPhCrntOtRgLSt CSSP_CmpPhCrntOtRgHSt;
SIG_GROUP_ 558 CmpDataPkt 1 : CDP_HVDevShtdnCdARCSt CDP_CmpSpdReqARCSt CDP_CmpLossCommOcc CDP_CmpWkUp CDP_CmpRunCrnk;
SIG_GROUP_ 550 ACCModCalIdInf 1 : ACCMCII_DtBtG ACCMCII_DtBtF ACCMCII_DtBtE ACCMCII_DtBtD ACCMCII_DtBtC ACCMCII_DtBtB ACCMCII_DtBtA ACCMCII_SeqNum ACCMCII_Index ACCMCII_DatStat;
SIG_GROUP_ 289 ADASISRawDatMplxd 1 : Sig0936 Sig0935;
SIG_GROUP_ 1910 DTCInfo_776 1 : DTCI_DTCFaultType_776 DTCI_CodeSupported_776 DTCI_CurrentStatus_776 DTCI_TstNPsdCdClrdSt_776 DTCI_TstFldCdClrdStat_776 DTCI_HistStat_776 DTCI_TstNPsdPwrUpSt_776 DTCI_TstFldPwrUpSt_776 DTCI_WrnIndRqdSt_776 DTCI_DTCFailType_776 DTCI_DTCNumber_776 DTCI_DTCSource_776 DTCI_DTCTriggered_776 DTCIUnused7_776 DTCIUnused6_776 DTCIUnused5_776 DTCIUnused4_776 DTCIUnused3_776 DTCIUnused2_776 DTCIUnused1_776;
SIG_GROUP_ 1916 DTCInfo_77C 1 : DTCI_DTCFaultType_77C DTCI_CodeSupported_77C DTCI_CurrentStatus_77C DTCI_TstNPsdCdClrdSt_77C DTCI_TstFldCdClrdStat_77C DTCI_HistStat_77C DTCI_TstNPsdPwrUpSt_77C DTCI_TstFldPwrUpSt_77C DTCI_WrnIndRqdSt_77C DTCI_DTCFailType_77C DTCI_DTCNumber_77C DTCI_DTCSource_77C DTCI_DTCTriggered_77C DTCIUnused7_77C DTCIUnused6_77C DTCIUnused5_77C DTCIUnused4_77C DTCIUnused3_77C DTCIUnused2_77C DTCIUnused1_77C;
SIG_GROUP_ 1917 DTCInfo_77D 1 : DTCI_DTCFaultType_77D DTCI_CodeSupported_77D DTCI_CurrentStatus_77D DTCI_TstNPsdCdClrdSt_77D DTCI_TstFldCdClrdStat_77D DTCI_HistStat_77D DTCI_TstNPsdPwrUpSt_77D DTCI_TstFldPwrUpSt_77D DTCI_WrnIndRqdSt_77D DTCI_DTCFailType_77D DTCI_DTCNumber_77D DTCI_DTCSource_77D DTCI_DTCTriggered_77D DTCIUnused7_77D DTCIUnused6_77D DTCIUnused5_77D DTCIUnused4_77D DTCIUnused3_77D DTCIUnused2_77D DTCIUnused1_77D;
SIG_GROUP_ 1930 DTCInfo_78A 1 : DTCI_CodeSupported_78A DTCI_CurrentStatus_78A DTCI_DTCFailType_78A DTCI_DTCFaultType_78A DTCI_DTCNumber_78A DTCI_DTCSource_78A DTCI_DTCTriggered_78A DTCI_HistStat_78A DTCI_TstFldCdClrdStat_78A DTCI_TstFldPwrUpSt_78A DTCI_TstNPsdCdClrdSt_78A DTCI_TstNPsdPwrUpSt_78A DTCIUnused1_78A DTCIUnused2_78A DTCIUnused3_78A DTCIUnused4_78A DTCIUnused5_78A DTCIUnused6_78A DTCIUnused7_78A DTCI_WrnIndRqdSt_78A;
SIG_GROUP_ 1914 DTCInfo_77A 1 : DTCI_DTCFaultType_77A DTCI_CodeSupported_77A DTCI_CurrentStatus_77A DTCI_TstNPsdCdClrdSt_77A DTCI_TstFldCdClrdStat_77A DTCI_HistStat_77A DTCI_TstNPsdPwrUpSt_77A DTCI_TstFldPwrUpSt_77A DTCI_WrnIndRqdSt_77A DTCI_DTCFailType_77A DTCI_DTCNumber_77A DTCI_DTCSource_77A DTCI_DTCTriggered_77A DTCIUnused7_77A DTCIUnused6_77A DTCIUnused5_77A DTCIUnused4_77A DTCIUnused3_77A DTCIUnused2_77A DTCIUnused1_77A;
SIG_GROUP_ 313 IntlStdAlph2CddCntryCd 1 : ISA2CCC_ScndCdChr ISA2CCC_FrstCdChr;
SIG_GROUP_ 1328 AlrmClkStat 1 : ACSAlarm9 ACSAlarm8 ACSAlarm7 ACSAlarm6 ACSAlarm5 ACSAlarm4 ACSAlarm3 ACSAlarm2 ACSAlarm15 ACSAlarm14 ACSAlarm13 ACSAlarm12 ACSAlarm11 ACSAlarm10 ACSAlarm1 ACSAlarm0;
